VERSION ""

NS_ :

BS_:

BU_: ATCM_FFSM GENERIC_GWMWakeup IPMB Generic_BCM GWM _delete ABS_ESC HUD IPMA CCM PSCM SCCM TBM OCS TCCM TSTR RCM
VAL_TABLE_ Faulty_F 15 "Faulty" ;
VAL_TABLE_ TrlrTrgtAcquire_D_Rq 7 "NotUsed_2" 6 "NotUsed_1" 5 "ActivateRVCforTBA" 4 "CancelAcquisition" 3 "RetryAcquisition" 2 "AcquisitionSuccessful" 1 "StartAcquisition" 0 "Inactive" ;
VAL_TABLE_ TrlrTrgtAcquire_D_Stat 7 "Faulty" 6 "NotUsed_2" 5 "NotUsed_1" 4 "RVCforTBA_Activated" 3 "Processing" 2 "TargetNotAcquired" 1 "TargetAcquired" 0 "Null" ;
VAL_TABLE_ TrlrAidSetup_D_Rq 3 "NotUsed" 2 "EndSetup" 1 "BeginSetup" 0 "Inactive" ;
VAL_TABLE_ TrlBrkInitOut 3 "NotUsed" 2 "Heavy" 1 "Medium" 0 "Light" ;
VAL_TABLE_ BeltWarnThres_D_Stat 7 "Faulty" 6 "No_Data_Exists" 5 "NotUsed3" 4 "NotUsed2" 3 "NotUsed1" 2 "Over_Threshold" 1 "Under_Threshold" 0 "NotSupported" ;
VAL_TABLE_ IsaVLimUnit_D_Rq 3 "NoDataExists" 2 "Mph" 1 "Kph" 0 "Null" ;
VAL_TABLE_ IsaVLim_D_Rq 183 "NotUsed_3_to_72_toHexFC" 2 "LimitSpeed2_to_178_toHexB2" 255 "Faulty" 254 "NoDataExists" 253 "NotUsed_73" 182 "NotUsed_2" 181 "NotUsed_1" 180 "LimitSpeed_180_kph_mph" 179 "LimitSpeed_179_kph_mph" 1 "LimitSpeed_1_kph_mph" 0 "LimitSpeed_0_kph_mph" ;
VAL_TABLE_ NotSupported_Supported 1 "Supported" 0 "NotSupported" ;
VAL_TABLE_ OffOn_NotUsed_NoData 3 "No_Data_Present" 2 "NotUsed" 1 "On" 0 "Off" ;
VAL_TABLE_ BrkDrvMde_D_Rq 7 "Faulty" 6 "NotUsed3" 5 "NotUsed2" 4 "NotUsed1" 3 "Track" 2 "Snow_Wet" 1 "Sport" 0 "Normal" ;
VAL_TABLE_ Off_Indicate1_2_Faulty 3 "Faulty" 2 "Indication_2" 1 "Indication_1" 0 "Off" ;
VAL_TABLE_ AutoHoldMsgTxt_D_Rq 15 "Message15" 14 "Message14" 13 "Message13" 12 "Message12" 11 "Message11" 10 "Message10" 9 "Message9" 8 "Message8" 7 "Message7" 6 "Message6" 5 "Message5" 4 "Message4" 3 "Message3" 2 "Message2" 1 "Message1" 0 "NoMessage" ;
VAL_TABLE_ NoYesNoDataFaulty 3 "Faulty" 2 "NoDataExists" 1 "Yes" 0 "No" ;
VAL_TABLE_ TsrVlPrmntMsgTxt_D_Rq 3 "NotUsed" 2 "ShowPermanentlyWithSupp" 1 "ShowPermanentlyWithoutSupp" 0 "DoNotShowSignPermanent" ;
VAL_TABLE_ TsrVl1RstrcMsgTxt2_D_Rq 7 "NotUsed" 6 "Time" 5 "Trailer" 4 "Snow" 3 "RainWet" 2 "NoRecognizableRestrictn" 1 "NoSpeedLimitRestrictn" 0 "Null" ;
VAL_TABLE_ PtDrvMde_D_Rq 15 "Faulty" 14 "NotUsed11" 13 "NotUsed10" 12 "NotUsed9" 11 "NotUsed8" 10 "NotUsed7" 9 "NotUsed6" 8 "NotUsed5" 7 "NotUsed4" 6 "NotUsed3" 5 "NotUsed2" 4 "NotUsed1" 3 "TowHaulGradeAssist" 2 "SnowWet" 1 "Sport" 0 "Normal" ;
VAL_TABLE_ SteEffort_D_Stat 7 "NotUsed5" 6 "NotUsed4" 5 "NotUsed3" 4 "NotUsed2" 3 "NotUsed1" 2 "Comfort" 1 "Sport" 0 "Normal" ;
VAL_TABLE_ TsrOvtkMsgTxt2_D_Rq 15 "NotUsed5" 14 "NotUsed4" 13 "NotUsed3" 12 "NotUsed2" 11 "NotUsed1" 10 "LimForTrucksCancelled" 9 "LimForTrucksWoQlfdRstrc" 8 "LimForTrucksWithoutRstrc" 7 "LimAllCancelled" 6 "LimAllWithRstrcTime" 5 "LimAllWithRstrcTrailer" 4 "LimAllWithRstrcSnow" 3 "LimAllWithRstrcRain" 2 "LimAllWithoutQlfdRstrc" 1 "LimAllWithoutRestriction" 0 "OvertakingAllowed" ;
VAL_TABLE_ TrlrAnOffstDir 3 "NotUSed" 2 "Right" 1 "Left_or_Center" 0 "Null" ;
VAL_TABLE_ TrlrBrkMde_D_Rq 1 "ElectricOverHydraulic" 0 "Electric" ;
VAL_TABLE_ TrlrAidMsgTxt_D_Rq 31 "Message31" 30 "Message30" 29 "Message29" 28 "Message28" 27 "Message27" 26 "Message26" 25 "Message25" 24 "Message24" 23 "Message23" 22 "Message22" 21 "Message21" 20 "Message20" 19 "Message19" 18 "Message18" 17 "Message17" 16 "Message16" 15 "Message15" 14 "Message14" 13 "Message13" 12 "Message12" 11 "Message11" 10 "Message10" 9 "Message9" 8 "Message8" 7 "Message7" 6 "Message6" 5 "Message5" 4 "Message4" 3 "Message3" 2 "Message2" 1 "Message1" 0 "NoMessage" ;
VAL_TABLE_ Invalid_7F 127 "Invalid" ;
VAL_TABLE_ Faulty_1FFF 8191 "Faulty" ;
VAL_TABLE_ VehStab_D_Stat 15 "Faulty" 14 "NotUsed7" 13 "NotUsed6" 12 "NotUsed5" 11 "NotUsed4" 10 "NotUsed3" 9 "NotUsed2" 8 "NotUsed1" 7 "High_SSRA_no_OS" 6 "Straight" 5 "Post_Oversteer" 4 "Post_Transition" 3 "Countersteer" 2 "Understeer" 1 "Oversteer" 0 "Linear" ;
VAL_TABLE_ TrlrAidEnbl_D_Stat 7 "Faulty" 6 "NoDataExists" 5 "NotUsed2" 4 "NotUsed1" 3 "TbaNotAvailable" 2 "TbaInactive" 1 "TbaActive" 0 "Null" ;
VAL_TABLE_ TrlrAidEnbl_D_Rq 3 "Faulty" 2 "DeactivateTba" 1 "ActivateTba" 0 "Inactive" ;
VAL_TABLE_ Null_Pers1_4_Vehicle 7 "Unused_2" 6 "Unused_1" 5 "Vehicle" 4 "PERS_4" 3 "PERS_3" 2 "PERS_2" 1 "PERS_1" 0 "Null" ;
VAL_TABLE_ PrkLckCtlUnlck_D_Stat 3 "Trans_And_Steer_Unlckd" 2 "Steering_Unlckd" 1 "Transmission_Unlckd" 0 "Null" ;
VAL_TABLE_ VehKeyActv_D_Stat 15 "NotUsed7" 14 "NotUsed6" 13 "NotUsed5" 12 "NotUsed4" 11 "NotUsed3" 10 "NotUsed2" 9 "NotUsed1" 8 "Key8Active" 7 "Key7Active" 6 "Key6Active" 5 "Key5Active" 4 "Key4Active" 3 "Key3Active" 2 "Key2Active" 1 "Key1Active" 0 "NoKeyActive" ;
VAL_TABLE_ PrkBrkDynmc_D_Allw 3 "NotUsed" 2 "EPB_ECD_NotPossible" 1 "EPB_ECD_Possible" 0 "Used_at_Start_Up" ;
VAL_TABLE_ TrnGearMsgTxt_D_Rq 31 "Message_31" 30 "Message_30" 29 "Message_29" 28 "Message_28" 27 "Message_27" 26 "Message_26" 25 "Message_25" 24 "Message_24" 23 "Message_23" 22 "Message_22" 21 "Message_21" 20 "Message_20" 19 "Message_19" 18 "Message_18" 17 "Message_17" 16 "Message_16" 15 "Message_15" 14 "Message_14" 13 "Message_13" 12 "Message_12" 11 "Message_11" 10 "Message_10" 9 "Message_9" 8 "Message_8" 7 "Message_7" 6 "Message_6" 5 "Message_5" 4 "Message_4" 3 "Message_3" 2 "Message_2" 1 "Message_1" 0 "NoMessage" ;
VAL_TABLE_ Off_On_Unknown_Invalid 3 "Invalid" 2 "Unknown" 1 "On" 0 "Off" ;
VAL_TABLE_ TowBarMsgTxt_D_Rq 7 "NotUsed3" 6 "NotUsed2" 5 "NotUsed1" 4 "TowBar_Ext_No_Trlr" 3 "Error_Dealer_Fix" 2 "Start_Engine_Swivel" 1 "Check_Tow_Bar" 0 "Null" ;
VAL_TABLE_ PrkBrk_D_Stat 7 "Gen_Faults_or_Maint_Mode" 6 "ECD_by_Brake_ECU_Active" 5 "EPB_Limphome_Active" 4 "Rear_Caliper_Open" 3 "RWU_by_EPB_Active" 2 "Rear_Caliper_Transition" 1 "Rear_Caliper_Closed" 0 "Not_Supported" ;
VAL_TABLE_ AutoLghtMde_D_Stat 3 "Not_Used" 2 "GFHB" 1 "AHBC" 0 "Manual" ;
VAL_TABLE_ GfhbDistr_D_Stat 7 "High_Beam_Classis" 6 "High_Beam_GFHB" 5 "GFHB_with_Vert_Adjustment" 4 "GFHB_with_Spot" 3 "Motorway" 2 "Low_Beam_GFHB" 1 "Low_Beam_Classic" 0 "Symmetric" ;
VAL_TABLE_ GfhbV_D 3 "Immediately" 2 "Fast" 1 "Medium" 0 "Slow" ;
VAL_TABLE_ GfhbLamp_D_Stat 3 "Both_On" 2 "Left_On_Right_Off" 1 "Right_On_Left_Off" 0 "Both_Off" ;
VAL_TABLE_ GfhbDistrChng_D_Stat 3 "Both_in_Transition" 2 "Left_in_Transition" 1 "Right_in_Transition" 0 "Both_Static" ;
VAL_TABLE_ Faulty_1FF 511 "Faulty" ;
VAL_TABLE_ NoData_Faulty_1FFF_1FFE 8191 "Faulty" 8190 "NoDataExists" ;
VAL_TABLE_ AwdSys_D_Stat 3 "Faulty" 2 "NotUsed" 1 "_4x4_L_H_Active" 0 "_4x4_L_H_Inactive" ;
VAL_TABLE_ TrnSrvcRqd_B_Rq 1 "On" 0 "Off" ;
VAL_TABLE_ immoSecureIdleMode 3 "NotUsed2" 2 "NotUsed1" 1 "Active" 0 "Inactive" ;
VAL_TABLE_ SteMdule_D_Stat 7 "NotUsed" 6 "EPAS_Failure3" 5 "EPAS_Failure2" 4 "System_Failure" 3 "EPAS_Shutdown" 2 "Normal_Op_Full_Assist" 1 "Normal_Op_Limited_Assist" 0 "EPAS_Initialization" ;
VAL_TABLE_ TrlrAid_D_Stat 15 "Faulty" 14 "NoDataExists" 13 "NotUsed5" 12 "NotUsed4" 11 "NotUsed3" 10 "NotUsed2" 9 "NotUsed1" 8 "Sensor_Fault" 7 "Sensor_Blocked" 6 "Target_Cannot_Be_Located" 5 "Acquired_Confidence5" 4 "Acquired_Confidence4" 3 "Acquired_Confidence3" 2 "Acquired_Confidence2" 1 "Acquired_Confidence1" 0 "Target_Not_Acquired" ;
VAL_TABLE_ Faulty_FFF 4095 "Faulty" ;
VAL_TABLE_ Faulty_3FF 1023 "Faulty" ;
VAL_TABLE_ NoData_Faulty_FE_FF 255 "Faulty" 254 "NoDataExists" ;
VAL_TABLE_ TrnLvrV_D_Rq 3 "Full_Speed" 2 "Aggressive" 1 "Normal" 0 "Quiet" ;
VAL_TABLE_ DynoMde_B_Cmd 1 "Two_Wheel_Dyno" 0 "Normal_Operation" ;
VAL_TABLE_ NoData_Faulty_FFFE_FFFF 65535 "Faulty" 65534 "NoDataExists" ;
VAL_TABLE_ NoData_Faulty_7FFE_7FFF 32767 "Faulty" 32766 "NoDataExists" ;
VAL_TABLE_ NoData_Faulty_3FE_3FF 1023 "Faulty" 1022 "NoDataExists" ;
VAL_TABLE_ OffOn_NotUsed 3 "NotUsed2" 2 "NotUsed1" 1 "On" 0 "Off" ;
VAL_TABLE_ DrQltyDrv_D_StatGsm 7 "Faulty" 6 "NoDataExists" 5 "NotUsed2" 4 "NotUsed1" 3 "ClosedDegraded" 2 "OpenDegraded" 1 "ClosedOkay" 0 "OpenOkay" ;
VAL_TABLE_ NoData_Fault_1FF_1FE 511 "Fault" 510 "NoDataExists" ;
VAL_TABLE_ NoData_Fault_FFE_FFF 4095 "Fault" 4094 "NoDataExists" ;
VAL_TABLE_ Quality_Faulty 3 "OK" 2 "Degraded" 1 "No_Data_Exists" 0 "Faulty" ;
VAL_TABLE_ TrnDtpCmd_D_Actl 7 "NotUsed4" 6 "NotUsed3" 5 "NotUsed2" 4 "Relatch" 3 "Deploy" 2 "Self_Test" 1 "No_Command" 0 "NotUsed1" ;
VAL_TABLE_ TrnGsmNtmState_D_Actl 3 "Faulty" 2 "Neutral_Tow_Mode" 1 "Car_Wash_Mode" 0 "None" ;
VAL_TABLE_ TrnTrcmPwmSig_D_Actl 15 "Faulty" 14 "NoDataExists" 13 "NotUsed5" 12 "NotUsed4" 11 "NotUsed3" 10 "NotUsed2" 9 "NotUsed1" 8 "Default_To_Park" 7 "Neutral_Tow" 6 "Car_Wash_Mode" 5 "Manual" 4 "Drive" 3 "Neutral" 2 "Reverse" 1 "Park" 0 "No_Gear" ;
VAL_TABLE_ RgenBrkDynoMde_B_Actl 1 "TwoWheelDyno" 0 "NormalOperation" ;
VAL_TABLE_ Fault_3FFF 16383 "Fault" ;
VAL_TABLE_ CtaInnr_D_Stat 3 "Reporting" 2 "Not_Reporting" 1 "System_Standby" 0 "Initialization" ;
VAL_TABLE_ PrkBrkActv_D_RqTrnGear 3 "NotUsed2" 2 "RequestParkBrakeEngage" 1 "NoRequest" 0 "NotUsed1" ;
VAL_TABLE_ NoRequest_Request 1 "Request" 0 "NoRequest" ;
VAL_TABLE_ Fault_FFF_NoData 4094 "NoDataExists" 4095 "Fault" ;
VAL_TABLE_ Fault_3FF_NoData 1022 "NoDataExists" 1023 "Fault" ;
VAL_TABLE_ ICI_Coding_BtnID_A 15 "Idle" 5 "Stuck" 4 "LongEvent" 3 "ShortElapsed" 2 "ShortEvent" 1 "Active" 0 "Inactive" ;
VAL_TABLE_ Foh_D_Stat 7 "Unused3" 6 "Unused2" 5 "Unused1" 4 "Stopping" 3 "Running" 2 "Starting" 1 "Prestart" 0 "Off" ;
VAL_TABLE_ Fault_1FF 511 "Fault" ;
VAL_TABLE_ SteWhlHeat 15 "NotUsed6" 14 "NotUsed5" 13 "NotUsed4" 12 "NotUsed3" 11 "NotUsed2" 10 "NotUsed1" 9 "Reserved_3" 8 "Reserved_2" 7 "Reserved_1" 6 "Level_3_Heating" 5 "Level_3_Heating_LS" 4 "Level_2_Heating" 3 "Level_2_Heating_LS" 2 "Level_1_Heating" 1 "Level_1_Heating_LS" 0 "Off" ;
VAL_TABLE_ NullKphMph 3 "NoDataExists" 2 "Mph" 1 "Kph" 0 "Null" ;
VAL_TABLE_ TsrVLim1MsgTxt_D_Rq 255 "NoLimit" 254 "NotUsed2" 253 "NotUsed1" 252 "NotToBeDisplayed" 251 "LimitCancelled" 31 "1F_FA_Message31_250" 30 "Message30" 29 "Message29" 28 "Message28" 27 "Message27" 26 "Message26" 25 "Message25" 24 "Message24" 23 "Message23" 22 "Message22" 21 "Message21" 20 "Message20" 19 "Message19" 18 "Message18" 17 "Message17" 16 "Message16" 15 "Message15" 14 "Message14" 13 "Message13" 12 "Message12" 11 "Message11" 10 "Message10" 9 "Message9" 8 "Message8" 7 "Message7" 6 "Message6" 5 "Message5" 4 "Message4" 3 "Message3" 2 "Message2" 1 "Message1" 0 "Null" ;
VAL_TABLE_ TsrVl1RstrcMsgTxt_D_Rq 3 "NotUsed" 2 "NoRecognizableRestriction" 1 "NoSpeedLimitRestriction" 0 "Null" ;
VAL_TABLE_ TsrMsgTxt_D_Rq 15 "NotUsed5" 14 "NotUsed5" 13 "NotUsed4" 12 "NotUsed3" 11 "NotUsed2" 10 "NotUsed1" 9 "RecgnzdSignNotUsblForDsply" 8 "LimitedSystemPerformance" 7 "OffRoad" 6 "RegionNotSupported" 5 "CountryNotSupported" 4 "WrngNavDatIncompDatCarrier" 3 "NoNavDataAvailable" 2 "NoNavAvailableSwitchedOff" 1 "NoInformationAllOK" 0 "Null" ;
VAL_TABLE_ TsrOvtkTypeMsgTxt_D_Rq 3 "NotUsed" 2 "Explicit" 1 "Implicit" 0 "Null" ;
VAL_TABLE_ TsrOvtkStatMsgTxt_D_Rq 3 "LimitOutdated" 2 "LimitReiable" 1 "LimitChanged" 0 "Null" ;
VAL_TABLE_ TsrOvtkMsgTxt_D_Rq 7 "LimForTrucksCancelled" 6 "LimForTrucksWoQlfdRstrc" 5 "LimForTrucksWithoutRstrc" 4 "LimAllCancelled" 3 "LimAllWithoutQlfdRstrc" 2 "LimAllWithoutRestriction" 1 "OvertakingAllowed" 0 "Null" ;
VAL_TABLE_ Null_False_True 3 "NotUsed" 2 "True" 1 "False" 0 "Null" ;
VAL_TABLE_ TsrStatMsgTxt_D_Rq 7 "NotUsed" 6 "NoDataExists" 5 "TSR_Error" 4 "Available_NavigationOnly" 3 "Available_CameraOnly" 2 "Available_FusionMode" 1 "TSR_Off" 0 "Null" ;
VAL_TABLE_ NoMessage_DisplayMessage 1 "DisplayMessage" 0 "NoMessage" ;
VAL_TABLE_ FdsmTrgRight 1 "Object_in_Right_Lobe" 0 "No_Object" ;
VAL_TABLE_ FdsmTrgCntr 1 "Object_in_Center_Lobe" 0 "No_Object" ;
VAL_TABLE_ FdsmTrgLeft 1 "Object_in_Left_Lobe" 0 "No_Object" ;
VAL_TABLE_ EngineBrakeOff_Active 1 "Engine_Braking_Activated" 0 "Engine_Braking_Off" ;
VAL_TABLE_ NoEngineBrake_Brake 1 "Engine_Braking" 0 "No_Engine_Braking" ;
VAL_TABLE_ EngSrvcRqd_B_Rq 1 "Engine_Service_Required" 0 "No_engine_service_required" ;
VAL_TABLE_ Allowed_Denied 1 "Denied" 0 "Allowed" ;
VAL_TABLE_ PrkAidMsgTxt_D_Rq 15 "NotUsed7" 14 "NotUsed6" 13 "NotUsed5" 12 "R_Sns_Inactive_Trlr_atch" 11 "Not_Avail_Trlr_attchd" 10 "Fail_Mode_no_Chime" 9 "Fail_Mode_with_Chime" 8 "NotUsed4" 7 "NotUsed3" 6 "Park_Sys_Alternate_Mode" 5 "R_Snsrs_On_F_Snsrs_On" 4 "NotUsed2" 3 "NotUsed1" 2 "R_Snsrs_Off_F_Snsrs_On" 1 "R_Snsrs_On_F_Snsrs_Off" 0 "All_Park_Sensors_Off" ;
VAL_TABLE_ PrkAidSns_D_Stat 15 "Zone_15" 14 "Zone_14" 13 "Zone_13" 12 "Zone_12" 11 "Zone_11" 10 "Zone_10" 9 "Zone_9" 8 "Zone_8" 7 "Zone_7" 6 "Zone_6" 5 "Zone_5" 4 "Zone_4" 3 "Zone_3" 2 "Zone_2" 1 "Zone_1" 0 "Off" ;
VAL_TABLE_ PrkAid_D_Falt 7 "NotUsed2" 6 "NotUsed1" 5 "Failure_Front_PSM_Sensors" 4 "No_Data_Exists" 3 "Failure_Rear_Sensors" 2 "Speaker_Fault" 1 "ECU_Fault" 0 "No_Fault" ;
VAL_TABLE_ OffOnNoDataFault 3 "Fault" 2 "No_Data_Exists" 1 "On" 0 "Off" ;
VAL_TABLE_ ApaActvSd_D_Actl 3 "Dirver_Side" 2 "Passenger_Side" 1 "No_Side" 0 "Null" ;
VAL_TABLE_ ApaMde_D_Avail 15 "NotUsed7" 14 "NotUsed6" 13 "NotUsed5" 12 "NotUsed4" 11 "NotUsed3" 10 "NotUsed2" 9 "NotUsed1" 8 "PPA_POA" 7 "SAPP_POA" 6 "POA" 5 "PPA" 4 "SAPP" 3 "SAPP_PPA_POA" 2 "SAPP_PPA" 1 "None" 0 "Null" ;
VAL_TABLE_ ApaMde_D_Stat 7 "NotUsed3" 6 "NotUsed2" 5 "NotUsed1" 4 "POA" 3 "PPA" 2 "SAPP" 1 "Off" 0 "Null" ;
VAL_TABLE_ _7F_Null 127 "Null" ;
VAL_TABLE_ MemFeedback 8 "Recall_4" 7 "Recall_3" 6 "Recall_2" 5 "Recall_1" 4 "Store_4" 3 "Store_3" 2 "Store_2" 1 "Store_1" 0 "Inactive" ;
VAL_TABLE_ Null_Off_LowHigh 3 "High" 2 "Low" 1 "Off" 0 "Null" ;
VAL_TABLE_ NotUpdate_Update 1 "Updating" 0 "NotUpdating" ;
VAL_TABLE_ SeatFnDrv_D_Stat 7 "CushionMassage" 6 "LumbarMassage" 5 "UpperBolster" 4 "LowerBolster" 3 "UpperLumbar" 2 "MiddleLumbar" 1 "LowerLumbar" 0 "Null" ;
VAL_TABLE_ GearRvrse_D_Actl 7 "Fault" 6 "NotUsed_3" 5 "NotUsed_2" 4 "NotUsed_1" 3 "Active_confirmed" 2 "Active_not_confirmed" 1 "Inactive_confirmed" 0 "Inactive_not_confirmed" ;
VAL_TABLE_ SideDetect_SnStat_Invalid 3 "Invalid" 2 "System_Failure" 1 "Blocked" 0 "Clear" ;
VAL_TABLE_ SideDetect_OpStat 4 "Invalid" 3 "Disabled" 2 "On" 1 "Trailer_Tow_Off" 0 "Off" ;
VAL_TABLE_ SideDetect_Present 4 "Sensor_Blocked" 3 "Sensor_Fault" 2 "Flash_On" 1 "Alert_On" 0 "AlertOff_FlashOff_SensrClr" ;
VAL_TABLE_ Off_On_Flash_BulbProveout 3 "Bulb_Proveout" 2 "Flash" 1 "On" 0 "Off" ;
VAL_TABLE_ SideDetect_report 3 "Reporting" 2 "Not_Reporting" 1 "System_Standby" 0 "Initialization" ;
VAL_TABLE_ DcacElPw_D_Rq 3 "NotUsed" 2 "AC_HighPower_Requested" 1 "AC_LowPower_Requested" 0 "AC_Power_NotRequested" ;
VAL_TABLE_ Null_Up_Down 3 "Unused" 2 "Down" 1 "Up" 0 "Null" ;
VAL_TABLE_ Null_Fwd_Rwd 3 "Unused" 2 "Rearward" 1 "Forward" 0 "Null" ;
VAL_TABLE_ BattTracWarnLamp_B_Rq 1 "On" 0 "Off" ;
VAL_TABLE_ BattTracSrvcRqd_B_Rq 1 "On" 0 "Off" ;
VAL_TABLE_ HtrnWarnLamp_B_Dsply 1 "On" 0 "Off" ;
VAL_TABLE_ HtrnSrvcRqd_B_Dsply 1 "On" 0 "Off" ;
VAL_TABLE_ NoData_Faulty_7E_7F 127 "Faulty" 126 "NoDataExists" ;
VAL_TABLE_ HMI_HMIMode_St 5 "Load_Shed_Active" 0 "Invalid" 1 "OffMode" 2 "On" 3 "Phone" 4 "Climate" ;
VAL_TABLE_ FuelPumpPwr_D_Stat 7 "NotUsed3" 6 "NotUsed2" 5 "NotUsed1" 4 "Power_Off_Default" 3 "Power_Off_Command" 2 "Power_Off_Service" 1 "Power_Off_Impact" 0 "Power_On" ;
VAL_TABLE_ PtcHtr_D_Cmd 3 "TurnOn" 2 "AutoMode" 1 "TurnOff" 0 "NoDecision_Initializing" ;
VAL_TABLE_ NoData_Fault_FFFE_FFFF 65535 "Fault" 65534 "NoDataExists" ;
VAL_TABLE_ Fault_1FFF 8191 "Fault" ;
VAL_TABLE_ TrlrBattChrg_D_Stat 3 "Reverse" 2 "Normal" 1 "Low" 0 "Null" ;
VAL_TABLE_ TrlrLampCtl_D_Stat 3 "NotUsed" 2 "TrlrLampCnnctDrvFailure" 1 "TrlrLampNotCnnctDrvFailure" 0 "Null" ;
VAL_TABLE_ ElPw_D_StatStrtStop 15 "NotUsed6" 14 "NotUsed5" 13 "NotUsed4" 12 "NotUsed3" 11 "NotUsed2" 10 "NotUsed1" 9 "Supported_Level_4" 8 "Supported_Level_3" 7 "Supported_Level_2" 6 "Supported_Level_1" 5 "Limited_Support" 4 "Fault_Limited" 3 "LV_Event_in_Progress" 2 "Not_Supported_Imminent" 1 "Supported_All" 0 "Not_Supported" ;
VAL_TABLE_ ImpactEvntFdbck_D_Stat 3 "NotUsed" 2 "EventComplete" 1 "EventInProgress" 0 "Normal" ;
VAL_TABLE_ NoData_Fault_7FFE_7FFF 32767 "Fault" 32766 "NoDataExists" ;
VAL_TABLE_ NoData_Fault_3E_3F 63 "Fault" 62 "NoDataExists" ;
VAL_TABLE_ DrvSte_D_Stat 15 "NotUsed10" 14 "NotUsed9" 13 "NotUsed8" 12 "NotUsed7" 11 "NotUsed6" 10 "NotUsed5" 9 "NotUsed4" 8 "NotUsed3" 7 "NotUsed2" 6 "NotUsed1" 5 "Request_Active" 4 "Ignition_Off" 3 "DSR_in_Normal_Idle_Mode" 2 "EPAS_Comm_Disturbed" 1 "DSR_Request_Not_Applicable" 0 "DSR_Deactivated" ;
VAL_TABLE_ HeadLghtHiFdbck_D_Stat 3 "NotUsed" 2 "Cancel" 1 "Hold" 0 "Allow_Change" ;
VAL_TABLE_ Backlit_LED_Status 15 "Unused3" 14 "Unused2" 13 "Unused1" 12 "Night_12" 11 "Night_11" 10 "Night_10" 9 "Night_9" 8 "Night_8" 7 "Night_7" 6 "Night_6" 5 "Night_5" 4 "Night_4" 3 "Night_3" 2 "Night_2" 1 "Night_1" 0 "Off" ;
VAL_TABLE_ Veh_Lock_Status 3 "UNLOCK_DRV" 2 "UNLOCK_ALL" 1 "LOCK_ALL" 0 "LOCK_DBL" ;
VAL_TABLE_ PrkLckCtlMsgTxt_D_Rq 3 "BTSI_DI_3" 2 "BTSI_DI_2" 1 "BTSI_DI_1" 0 "Null_BTSI_DI" ;
VAL_TABLE_ NoShift_Shift 1 "Shift" 0 "NoShift" ;
VAL_TABLE_ CcdMsgTxt_D_RqDsply 15 "Unused8" 14 "Unused7" 13 "Unused6" 12 "Unused5" 11 "Unused4" 10 "Unused3" 9 "Unused2" 8 "Unused1" 7 "Mode_Change_Unavailable" 6 "CCD_Temporarily_Off" 5 "CCD_Service_Required" 4 "Fault" 3 "Sport" 2 "Normal" 1 "Comfort" 0 "No_Mode_Selected" ;
VAL_TABLE_ CrashEvnt_D_Stat 3 "Invalid" 2 "Fuel_Cutoff_Event" 1 "Deploy_Event" 0 "No_Event" ;
VAL_TABLE_ ReducedGuard_D_Stat 3 "NotUsed" 2 "Alarm_On" 1 "Alarm_Off_Previously_On" 0 "Alarm_Off" ;
VAL_TABLE_ ButtonNotPressed 1 "Button_Pressed" 0 "Button_Not_Pressed" ;
VAL_TABLE_ PudLamp_D_Rq 3 "RAMP_DOWN" 2 "RAMP_UP" 1 "ON" 0 "OFF" ;
VAL_TABLE_ WndwGlbl_D_Cmd 7 "NotUsed3" 6 "NotUsed2" 5 "NotUsed1" 4 "GLEARN" 3 "GCLOSE" 2 "GOPEN" 1 "GSTOP" 0 "Null" ;
VAL_TABLE_ Wiper 15 "NO_DATA_EXISTS" 14 "STALLED" 13 "RESERVED" 12 "AUTO_ADJUST" 11 "COURTESYWIPE" 10 "AUTO_HIGH" 9 "AUTO_LOW" 8 "WASH" 7 "MIST_FLICK" 6 "MAN_HIGH" 5 "MAN_LOW" 4 "MAN_INT_ON" 3 "MAN_INT_OFF" 2 "OFF_MOVING" 1 "AUTO_OFF" 0 "OFF" ;
VAL_TABLE_ Turn_switch 3 "Unused_Treat_As_Off" 2 "Right" 1 "Left" 0 "Off" ;
VAL_TABLE_ PrkLght_D_Stat 3 "Park_Both" 2 "Park_Right" 1 "Park_Left" 0 "Off" ;
VAL_TABLE_ LghtAmb_D_Sns 7 "No_Data_Exists" 6 "Unused2" 5 "Unused1" 4 "Tunnel_Off" 3 "Tunnel_On" 2 "Twilight" 1 "Light" 0 "Dark" ;
VAL_TABLE_ HeadLghtSwtch_D_Stat 3 "Autolamp" 2 "Headlamp" 1 "Parklamp" 0 "Off" ;
VAL_TABLE_ EmgcyBrkLamp_D_Rq 3 "NotUsed" 2 "Active_at_standstill" 1 "Active_at_speed" 0 "Inactive" ;
VAL_TABLE_ OpenPressedFault 3 "Fault" 2 "Unused" 1 "Pressed" 0 "Open" ;
VAL_TABLE_ LaHandsOff_D_Dsply 3 "Suppressed" 2 "Level2" 1 "Level1" 0 "HandsOn" ;
VAL_TABLE_ Avail_Unavail 1 "Unavailable" 0 "Available" ;
VAL_TABLE_ LaActvStats_D_Dsply 31 "Unused7" 30 "LA_Off" 29 "Unused5" 28 "Unused4" 27 "Unused3" 26 "Unused2" 25 "Unused1" 24 "InerveneLeft_InterveneRght" 23 "WarnLeft_InterveneRight" 22 "SuppressLeft_InterveneRght" 21 "AvailLeft_InterveneRhtt" 20 "NoLeft_InterveneRight" 19 "InterveneLeft_WarnRight" 18 "WarnLeft_WarnRight" 17 "SuppressLeft_WarnRight" 16 "AvailableLeft_WarnRight" 15 "NoLeft_WarnRight" 14 "InterveneLeft_SuppressRght" 13 "WarnLeft_SuppressRight" 12 "SuppressLeft_SuppressRight" 11 "AvailLeft_SuppressRight" 10 "NoLeft_SuppressRight" 9 "InterveneLeft_AvailRight" 8 "WarnLeft_AvailRight" 7 "SuppressLeft_AvailRight" 6 "AvailableLeft_AvailRight" 5 "NoLeft_AvailableRight" 4 "InterveneLeft_NoRight" 3 "WarnLeft_NoRight" 2 "SuppressLeft_NoRight" 1 "AvailableLeft_NoRight" 0 "NoLeft_NoRight" ;
VAL_TABLE_ AhbcHiBeam_D_Rq 3 "Deactivated_Unavailabl" 2 "Unused" 1 "Main_HighBeamRecommend" 0 "Dipped_LowBeamRecommend" ;
VAL_TABLE_ LifeCycMde_D_Actl 3 "Transport" 2 "NotUsed" 1 "Factory" 0 "Normal" ;
VAL_TABLE_ TrnMsgTxt_D_Rq 15 "Message_15" 14 "Message_14" 13 "Message_13" 12 "Message_12" 11 "Message_11" 10 "Message_10" 9 "Message_9" 8 "Message_8" 7 "Message_7" 6 "Message_6" 5 "Message_5" 4 "Message_4" 3 "Message_3" 2 "Message_2" 1 "Message_1" 0 "NoMessage" ;
VAL_TABLE_ DieslPrtcRgen_D_Rq 7 "Unused_2" 6 "Unused_1" 5 "Full_Regen_2" 4 "Full_Regen_1" 3 "HeatUp_3" 2 "HeatUp_2" 1 "HeatUp_1" 0 "Normal_Mode_NoRegen" ;
VAL_TABLE_ TrnCapHlth_Actl 3 "Capacitor_OK" 2 "Degraded_Capacitor" 1 "Capacitor_State_Unknown" 0 "Capacitor_Fault" ;
VAL_TABLE_ TrnSecPrkStat_D_Actl 7 "Faulty" 6 "Fault_Released" 5 "Fault_Latched" 4 "Recouple_in_Progress" 3 "Mechanism_Released" 2 "RTP_in_Progress" 1 "Pending" 0 "Latched" ;
VAL_TABLE_ TrnGear_D_Actl 7 "Fault" 6 "NotUsed" 5 "Manual" 4 "Drive" 3 "Neutral" 2 "Reverse" 1 "Park" 0 "Transition_State" ;
VAL_TABLE_ TrnNtrlTowCmd_D_Actl 3 "NotUsed" 2 "Neutral_Tow_Entry" 1 "Car_Wash_Mode" 0 "Normal_Mode" ;
VAL_TABLE_ TrnValidGear_D_Cnfm 3 "Accept" 2 "Reject" 1 "Internal_Request" 0 "No_Command" ;
VAL_TABLE_ TrnGear_D_RqPt 7 "Fault" 6 "NotUsed" 5 "Manual" 4 "Drive" 3 "Neutral" 2 "Reverse" 1 "Park" 0 "No_Gear" ;
VAL_TABLE_ TrnValidGearRq_D_Stat 3 "Valid_Request" 2 "Valid_Degraded_Request" 1 "Invalid_Request" 0 "No_Request" ;
VAL_TABLE_ NoData_Fault_3FE_3FF 1023 "Fault" 1022 "NoDataExists" ;
VAL_TABLE_ HtrnHvilOpen_B_Actl 1 "HVIL_is_Open" 0 "Normal_Operation" ;
VAL_TABLE_ EngFuelCutFull_B_Rq 1 "FuelCutRequest" 0 "NormalOperation" ;
VAL_TABLE_ Fault_7FF 2047 "Fault" ;
VAL_TABLE_ EngStopFst_B_Rq 1 "FastEngineShutdown" 0 "NormalOperation" ;
VAL_TABLE_ EngStrtCold_B_Rq 1 "ExtremeColdStart" 0 "NormalStart" ;
VAL_TABLE_ Fault_FFF 4095 "Fault" ;
VAL_TABLE_ PrkBrkMsgTxt_D_Rq 15 "Message15" 14 "Message14" 13 "Message13" 12 "Message12" 11 "Message11" 10 "Message10" 9 "Message9" 8 "Message8" 7 "Message7" 6 "Message6" 5 "Message5" 4 "Message4" 3 "Message3" 2 "Message2" 1 "Message1" 0 "No_Message" ;
VAL_TABLE_ VehStrtStop_D_Rq 3 "NotUsed" 2 "Vehicle_Start_Request" 1 "Vehicle_Stop_Request" 0 "NoRequest" ;
VAL_TABLE_ PrkBrkStatus 7 "GeneralFault_MaintenceMode" 6 "ECD_by_Brake_ECU_Active" 5 "EPB_Limphome_Active" 4 "Rear_Caliper_Open" 3 "RWU_By_EPB_Active" 2 "Rear_Caliper_Transition" 1 "Rear_Caliper_Closed" 0 "Not_Supported" ;
VAL_TABLE_ DontCare_StartInhibit 1 "Start_Inhibit" 0 "Dont_Care" ;
VAL_TABLE_ BattULoChrg_D_Rq 3 "Not_Used" 2 "Charging_Requested" 1 "Chrg_Requested_HighCurrent" 0 "No_Request" ;
VAL_TABLE_ PwSysULoFalt_D_Stat 15 "Not_Used_6" 14 "LowBatterySOC" 13 "PSS_Shed2_Contin" 12 "Not_Used_4" 11 "Not_Used_3" 10 "Not_Used_2" 9 "BattMonitoringSensorFault" 8 "LowBattVoltDuringPwSrcOn" 7 "LowBatt2_PowerSaveMode" 6 "LowBatt1_Warning" 5 "Overvoltage" 4 "Fault_NoOutput" 3 "Fault_ReducedOutput" 2 "Fault_Nonspecific" 1 "Cluster_Proveout" 0 "No_Fault" ;
VAL_TABLE_ AccStopMde_D_Rq 3 "Stop_Mode_Active" 2 "EPBApplyOrBrakeReleaseWarn" 1 "Limit_Rolling_Speed" 0 "Stop_Mode_Not_Active" ;
VAL_TABLE_ EngFuelCutFull_B_Sched 1 "DFSO_Event_Scheduled" 0 "Normal" ;
VAL_TABLE_ Eng_D_Stat 3 "NotUsed" 2 "EngAutoStopped" 1 "EngOn" 0 "EngOff" ;
VAL_TABLE_ ElPw_D_Stat 7 "NotUsed_3" 6 "NotUsed_2" 5 "NotUsed_1" 4 "Fault_Limited" 3 "LV_Event_In_Progress" 2 "Not_Supported_Imminent" 1 "Supported" 0 "Not_Supported" ;
VAL_TABLE_ PwPckTq_D_Stat 3 "PwPckOn_TqAvailable" 2 "StartInPrgrss_TqNotAvail" 1 "PwPckOn_TqNotAvailable" 0 "PwPckOff_TqNotAvailable" ;
VAL_TABLE_ Fault_FF 255 "Fault" ;
VAL_TABLE_ PsngrFrntDetct_D_Actl 3 "Unknown" 2 "Empty" 0 "Faulty" 1 "Occupied" ;
VAL_TABLE_ LaActvAvail 3 "LKA_LCA_LDW_Avail" 2 "LCA_LKA_Avail_LDW_Suppress" 1 "LCA_LKA_Suppress_LDW_Avail" 0 "LCA_LKA_LDW_Suppress" ;
VAL_TABLE_ LA_NotDenied 1 "LA_Denied" 0 "LA_Not_Denied" ;
VAL_TABLE_ HandsOn_Off 1 "Hands_Off" 0 "Hands_On" ;
VAL_TABLE_ Smooth_Quick 1 "Quick" 0 "Smooth" ;
VAL_TABLE_ LkaActvStats 7 "LKALCA_Suppress_Right_Left" 6 "LCA_In_Progress" 5 "LKA_Suppress_Right" 4 "LKA_Intervention_Right" 3 "LKA_Suppress_Left" 2 "LKA_Intervention_Left" 1 "LKA_Idle_LCA_Suppress" 0 "LKA_Idle" ;
VAL_TABLE_ None_Low_Med_High 3 "High" 2 "Medium" 1 "Low" 0 "None" ;
VAL_TABLE_ LdwActvStats 7 "LDW_Suppress_Right_Left" 6 "Not_Used2" 5 "LDW_Suppress_Right" 4 "LDW_Warning_Right" 3 "LDW_Suppress_Left" 2 "LDW_Warning_Left" 1 "Not_Used1" 0 "LDW_Idle" ;
VAL_TABLE_ Fault_3FF 1023 "Fault" ;
VAL_TABLE_ VedsEvnt_6 5 "Unused_3" 4 "Unused_2" 3 "Unused_1" 2 "NotBelted" 1 "Belted" 0 "NoEvent" 7 "Fault" 6 "NotSupported" ;
VAL_TABLE_ VedsEvnt_5 7 "Fault" 6 "NotSupported" 5 "Unused_3" 4 "Unused_2" 3 "Unused_1" 2 "ChildNotDetected" 1 "ChildDetected" 0 "NoEvent" ;
VAL_TABLE_ VedsEvnt_4 7 "Fault" 6 "NotSupported" 5 "Unused_3" 4 "Unused_2" 3 "Unused_1" 2 "NotDeployed" 1 "Deployed" 0 "NoEvent" ;
VAL_TABLE_ VedsEvnt_3 0 "NoEvent" 255 "Fault" 254 "NotSupported" ;
VAL_TABLE_ VedsEvnt_2 7 "Fault" 6 "NotSupported" 5 "Unused_3" 4 "Unused_2" 3 "Unused_1" 2 "Yes" 1 "No" 0 "NoEvent" ;
VAL_TABLE_ VedsEvnt_1 7 "Fault" 6 "NotSupported" 5 "Unused" 4 "Rolllover" 3 "Rear" 2 "Side" 1 "Frontal" 0 "NoEvent" ;
VAL_TABLE_ TmsStatRqDsply 15 "Reserved4" 14 "Reserved3" 13 "Reserved2" 12 "Crawl_Mode_4LOW_Reqd" 11 "Economy_Mode_Select" 10 "ModeChangeNotAvailable" 9 "Terrain_Sys_Not_Avail" 8 "Terrain_System_Fault" 7 "Mode_Change_InProgress" 6 "Dynamics_Mode_Select" 5 "Rock_Crawl_Mode_Select" 4 "Sand_Mode_Select" 3 "Mud_Ruts_Mode_Select" 2 "Low_Mu_Mode_Select" 1 "Special_Modes_Off" 0 "No_Message" ;
VAL_TABLE_ Invalid_FFF 4095 "Invalid" ;
VAL_TABLE_ ParkAid_Chime 15 "Zone15_Chime" 14 "Zone14_Chime" 13 "Zone13_Chime" 12 "Zone12_Chime" 11 "Zone11_Chime" 10 "Zone10_Chime" 9 "Zone9_Chime" 8 "Zone8_Chime" 7 "Zone7_Chime" 6 "Zone6_Chime" 5 "Zone5_Chime" 4 "Zone4_Chime" 3 "Zone3_Chime" 2 "Zone2_Chime" 1 "Zone1_Chime" 0 "No_Chime" ;
VAL_TABLE_ Shed_Feature_Group_ID 14 "HtdMirr" 13 "HvacRearBlwr_Third" 12 "HvacRearBlwr_Second" 11 "HvacRearBlwr_First" 31 "All LSHED1 Features" 10 "Htd_Windscrn" 9 "SpltHtdBcklight_HtdMirr" 8 "HtdBcklight_HtdMirr" 7 "HtdCoolSeat_FrtDriver" 6 "HtdCoolSeat_FrtPass" 5 "HtdCoolSeat_RearPass" 4 "HtdCoolSeat_RearDriver" 3 "SmartTrlrTowBattCharge" 2 "Htd_StrWhl" 1 "Htd_Washer_Fluid" 0 "No_LSHED1_Features" 15 "Engine_Coolant_Fan" ;
VAL_TABLE_ Null_Cancel 1 "Cancel" 0 "Null" ;
VAL_TABLE_ Veh_Lock_Requestor 31 "Unused8" 30 "Unused7" 29 "Unused6" 28 "Unused5" 27 "Unused4" 26 "Unused3" 25 "Unused2" 24 "Unused1" 23 "Diagnostics" 22 "Console_Lock" 21 "Child_Lock" 20 "Double_Lock" 19 "Passive_Pasenger" 18 "Passive_Driver" 17 "Slam_Lock_Protect" 16 "SYNC" 15 "Passport" 14 "Passive_Smart_Unlock" 13 "Autorelock" 12 "RemoteStart" 0 "Null" 1 "Autolock" 11 "Smart_Unlock" 10 "Sliding_Door" 9 "Passive" 8 "Remote" 7 "Programming" 6 "Powerslide" 5 "Keypad" 4 "Key_Cylinder" 3 "Interior" 2 "Auto_Unlock" ;
VAL_TABLE_ EPAS_FAILURE 3 "SERVICE_POWER_STEERING_NOW" 2 "SERVICE_POWER_STEERING" 1 "POWER_STRG_ASSIST_FAULT" 0 "EPAS_OK_NO_MESSAGE" ;
VAL_TABLE_ Perimeter_Alarm_Mode 3 "Activated" 2 "Armed" 1 "Prearmed" 0 "Disarmed" ;
VAL_TABLE_ Invalid_FFFF 65535 "Invalid" ;
VAL_TABLE_ FdaStat_D_Dsply 7 "Undefined_3" 6 "Undefined_2" 5 "Undefined_1" 4 "Distance_Alert_Unavailable" 3 "DistanceAlertUnavail_Low" 2 "DistanceAlertUnavailActive" 1 "Distance_Alert_Available" 0 "Distance_Alert_Off" ;
VAL_TABLE_ Shed_Level_Req 7 "Unused_2" 6 "Loads_On" 5 "SHED_ENG_OFF" 4 "SOON_ENG_OFF" 3 "SHED2_CONTIN" 2 "SHED2_TRANS" 1 "SHED1" 0 "NO_SHED" ;
VAL_TABLE_ BpedMove_D_Actl 3 "Unknown" 2 "DriverApplyingBrakePedal" 1 "NoAutonomousBrkPdlMovement" 0 "AutonomousBrkPedalMove" ;
VAL_TABLE_ Off_On_Undefined_Fault 3 "Fault" 2 "Undefined" 1 "On" 0 "Off" ;
VAL_TABLE_ ChargeMode 7 "Undefined_2" 6 "Undefined_1" 5 "Battery_Identify" 4 "Battery_Refresh" 3 "SlowRegenAllowNoDischarge" 2 "Fast_Regen_Allowed" 1 "Slow_Regen_Allowed" 0 "Conventional_Charging" ;
VAL_TABLE_ Unknown_FFFE_Invalid_FFFF 65535 "Invalid" 65534 "Unknown" ;
VAL_TABLE_ eCallNotification 3 "Not_Used" 2 "Active" 1 "Normal" 0 "Not_Supported" ;
VAL_TABLE_ eCallConfirmation 7 "Unused_2" 6 "CallComplete_DTMF_Timeout" 5 "eCall_Configured_Off" 4 "Call_Unsuccessful" 3 "Call_Cancelled" 2 "Call_Completed" 1 "Call_In_Progress" 0 "Normal" ;
VAL_TABLE_ SAPPAngleControlStat5 1 "StrgColTorqueExceed_EAROn" 0 "ExternalSigContentOKforEAC" ;
VAL_TABLE_ Closed_Open_Active_Fault 3 "Fault" 2 "Active" 1 "Open" 0 "Closed" ;
VAL_TABLE_ SAPPAngleControlStat2 1 "Rel_ExtSteeringAngleReqx" 0 "NoRel_ExtSteeringAngleReqx" ;
VAL_TABLE_ SAPPAngleControlStat3 1 "EARactiveNoReverseEngage" 0 "ExternalSigContentOKforEAC" ;
VAL_TABLE_ RstrnImpactEvntStatus 7 "Invalid" 6 "Not_Used_4" 5 "Threshold_2_Exceeded" 4 "Not_Used_3" 3 "Threshold_1_Exceeded" 2 "Not_Used_2" 1 "Not_Used_1" 0 "Normal" ;
VAL_TABLE_ EDRTriggerEvntSync 1 "Threshold_Exceeded" 0 "Normal" ;
VAL_TABLE_ EngTeColdPrtct_D_Stats 3 "Undefined" 2 "OK_to_Drive" 1 "Engine_Warning" 0 "Normal_Operation" ;
VAL_TABLE_ HILL_DESC_MC 7 "Fault_Detected" 6 "Cooling_Down" 5 "Abort_Apply_Brakes" 4 "Active" 3 "Disabled" 2 "Enabled" 1 "Off_Road" 0 "Normal" ;
VAL_TABLE_ Closed_Ajar 1 "Ajar" 0 "Closed" ;
VAL_TABLE_ Quality_Factor 3 "OK" 2 "Not_Within_Specifications" 1 "No_Data_Exists" 0 "Faulty" ;
VAL_TABLE_ Null_Day_Night 3 "NotUsed" 2 "Night" 1 "Day" 0 "Null" ;
VAL_TABLE_ Null_Flash_High 3 "NotUsed" 2 "High" 1 "Flash_to_Pass" 0 "Null" ;
VAL_TABLE_ TrnShifMde_D_RqDrv 7 "Undefined" 6 "Tow_Haul_Range_Select" 5 "Overdrive_Cancel" 4 "Tow_haul" 3 "Sport_Tip" 2 "Sport" 1 "Range_Select" 0 "Normal" ;
VAL_TABLE_ GearPos_D_Actl 15 "Unknown" 14 "Reverse" 13 "Undefined_5" 12 "Undefined_4" 11 "Undefined_3" 10 "Undefined_2" 9 "Undefined_1" 8 "Eighth" 7 "Seventh" 6 "Sixth" 5 "Fifth" 4 "Fourth" 3 "Third" 2 "Second" 1 "First" 0 "Neutral" ;
VAL_TABLE_ OffOn_SlowFast_Flash 3 "Fast_Flash" 2 "Slow_Flash" 1 "On" 0 "Off" ;
VAL_TABLE_ AwdStat_D_RqDsply 31 "NotUsed9" 30 "NotUsed8" 29 "NotUsed7" 28 "NotUsed6" 27 "NotUsed5" 26 "NotUsed4" 25 "NotUsed3" 24 "NotUsed2" 23 "Out_of_4Low_Crawl" 22 "AWD_PTU_Oil_Changed" 21 "Change_AWD_PTU_Oil" 20 "Neutral_Tow_Disabled" 19 "Neutral_Tow_Enabled" 18 "AWD_OFF" 17 "_4x4_Off_Road_Speed" 16 "_4x4_Extreme_Off_Road_Mode" 15 "_4x4_Exiting_Off_Road" 14 "_4x4_Off_Road_Mode" 10 "_4x4_Locked_Temporarily" 9 "Shift_In_Progress" 13 "Blocked_Shift_Assist" 12 "_4x4_Auto_Restored" 11 "_4x4_Disabled_Temporarily" 7 "Out_of_4Low__Neutral" 6 "Out_of_4Low__Brake" 5 "Out_of_4Low__Speed" 4 "Into_4Low__Clutch" 3 "Into_4Low__Neutral" 2 "Into_4Low__Brake" 1 "Into_4Low__Speed" 0 "Normal__No_Message" 8 "Out_of_4Low__Clutch" ;
VAL_TABLE_ AngleReached 1 "RequestedAngleNotReached" 0 "RequestedAngleCanBeReached" ;
VAL_TABLE_ WhlDir 3 "Failed" 2 "Unknown" 1 "Backward" 0 "Forward" ;
VAL_TABLE_ Unknown_Fault_1FE_1FF 511 "Fault" 510 "Unknown" ;
VAL_TABLE_ Fault_NoFault 1 "Fault" 0 "No_Fault" ;
VAL_TABLE_ TrnIpcDsplyMde_D_Actl 7 "Manual_3" 6 "Manual_2" 5 "Manual_1_Low" 4 "Sport" 3 "Drive" 2 "Neutral" 1 "Reverse" 0 "Park" ;
VAL_TABLE_ TrnIpcDsplyMde_D_Stat 3 "Reserved_Blank_No_Display" 2 "Flash" 1 "On" 0 "Blank_No_Display" ;
VAL_TABLE_ Unknown_Fault_7FE_7FF 2047 "Fault" 2046 "Unknown" ;
VAL_TABLE_ TerrMde_D_Actl 7 "Fail_Safe_Default" 6 "Dynamic_Mode" 5 "Rock_Crawl_Mode" 4 "Mud_Ruts_Mode" 3 "Sand_Mode" 2 "Undefined" 1 "Low_Mu_Mode" 0 "Special_Operating_Mode_Off" ;
VAL_TABLE_ TerrMdeChng_D_Rdy 7 "Fault" 6 "Undefined_2" 5 "Undefined_1" 4 "ModeUnavailDrInputRqd" 3 "SpOpModes_NotSupported" 2 "ModeUnavailDynamicCond" 1 "Module_In_Initialization" 0 "Mode_Change_Available" ;
VAL_TABLE_ Unknown_Fault_FFFE_FFFF 65535 "Fault" 65534 "Unknown" ;
VAL_TABLE_ Invalid_FFFFFF 16777215 "Invalid" ;
VAL_TABLE_ AutoParkSpdExitCond 1 "SpeedLimitExceededEAROn" 0 "ExternalSigContentOKforEAC" ;
VAL_TABLE_ HdcMde_D_Actl 7 "Fault" 6 "Temporarily_Unavailable" 5 "NotEnabled_WrongGearSel" 4 "NotEnabled_SpdLimitExceed" 3 "Active_Braking" 2 "Not_Active_Braking" 1 "Off" 0 "Undefined" ;
VAL_TABLE_ GearLvrPos_D_Actl 15 "Fault" 14 "Unknown_Position" 13 "Undefined_Treat_as__Fault" 12 "Undefined_Treat_as_Fault" 11 "sixth" 10 "fifth" 9 "fourth" 8 "third" 7 "second" 6 "first" 5 "Low" 4 "Sport_DriveSport" 3 "Drive" 2 "Neutral" 1 "Reverse" 0 "Park" ;
VAL_TABLE_ FcwMsgTxt_D_Rq 7 "Undefined_3" 6 "Undefined_2" 5 "Low_Visibility" 4 "Unavailable_DueTo_LowSpeed" 3 "Available" 2 "Unavailable" 1 "Off" 0 "No_Text" ;
VAL_TABLE_ FcwSens_B_Actl 3 "FCW_Sensitivity_3" 2 "FCW_Sensitivity_2" 1 "FCW_Sensitivity_1" 0 "Not_Used" ;
VAL_TABLE_ LastSettind_DefaultOn 1 "Default_On" 0 "Last_Setting" ;
VAL_TABLE_ EngTurboMde_D_Actl 3 "Fault" 2 "One_Turbo_Active" 1 "Two_Turbos_Active" 0 "Initializing" ;
VAL_TABLE_ EngMde_D_Rq 8 "VSC_Sets_Speed_Type_3" 7 "VSC_Sets_Speed_Type_2" 6 "VSC_Sets_Torque_Type_2" 5 "Dependability_Shutdown" 4 "Dependability_Follow" 3 "Start" 2 "VSC_Sets_Torque_Type_1" 1 "VSC_Sets_Speed_Type_1" 0 "Off" 15 "Undefined_7" 14 "Undefined_6" 13 "Undefined_5" 12 "Undefined_4" 11 "Undefined_3" 10 "Undefined_2" 9 "Undefined_1" ;
VAL_TABLE_ DrvHdcMsg_D_Rq 7 "Undefined" 6 "Speed_too_High" 5 "Temporarily_Unavailable" 4 "System_Fault" 3 "Select_Gear" 2 "Off" 1 "On" 0 "No_Message" ;
VAL_TABLE_ CmbbBrkPrchg_B_Rq 3 "Undefined" 2 "Level_2_PreCharge_Request" 1 "Level_1_PreCharge_Request" 0 "No_PreCharge_Request" ;
VAL_TABLE_ CmbbBaSens_D_Rq 3 "Level_3" 2 "Level_2" 1 "Level_1" 0 "Normal" ;
VAL_TABLE_ CcStat_D_Actl 7 "Undefined_2" 6 "Undefined_1" 5 "Active" 4 "Active_Que_Assist" 3 "Standby" 2 "Standby_Denied" 1 "Denied" 0 "Off" ;
VAL_TABLE_ CadsAudioMute_D_Rq 3 "Reserved" 2 "Partial_Audio_Mute" 1 "Full_Audio_Mute" 0 "No_Audio_Mute" ;
VAL_TABLE_ BpedDrvAppl_D_Actl 3 "_Not_Allowed" 2 "Driver_Braking" 1 "Driver_Not_Braking" 0 "Not_Allowed" ;
VAL_TABLE_ AslIconDsply_D_Rq 3 "Not_Used" 2 "On_Active" 1 "On_Passive" 0 "Off" ;
VAL_TABLE_ AccWarn_D_Dsply 3 "BrakeReleaseWarn_In_StopMd" 2 "Brake_Capacity_Warning" 1 "Cancel_Warning" 0 "No_Warning" ;
VAL_TABLE_ AccTrgDist2_D_Dsply 15 "DIST_ACTIVE_13_Farthest" 14 "DIST_ACTIVE_12" 13 "DIST_ACTIVE_11" 12 "DIST_ACTIVE_10" 11 "DIST_ACTIVE_9" 10 "DIST_ACTIVE_8" 9 "DIST_ACTIVE_7" 8 "DIST_ACTIVE_6" 7 "DIST_ACTIVE_5" 6 "DIST_ACTIVE_4" 5 "DIST_ACTIVE_3" 4 "DIST_ACTIVE_2" 3 "DIST_ACTIVE_1_Closest" 2 "DIST_ACTIVE_No_Target" 1 "DIST_STANDBY" 0 "DIST_OFF" ;
VAL_TABLE_ AccMsgTxt_D_Rq 15 "Undefined_2" 14 "NCC_Enabled_Warning" 13 "Driver_Intervene" 12 "Resume_Inhibited" 11 "Resume_to_FollowNewVehicle" 10 "Press_Brake_to_Hold" 9 "Only_Following_in_Low_Spd" 8 "PressAccelerator_to_Resume" 7 "Shift_Down" 6 "Press_Resume_to_Start" 5 "Turn_ESC_On_to_Enable_ACC" 4 "ACC_Overridden" 3 "Brake_Capacity_Warning" 2 "ACC_Cancelled" 1 "ACC_Unavailable" 0 "No_Text" ;
VAL_TABLE_ AccTGap_D_Dsply 7 "Undefined_2" 6 "Undefined_1" 5 "Time_Gap_5" 4 "Time_Gap_4" 3 "Time_Gap_3" 2 "Time_Gap_2" 1 "Time_Gap_1" 0 "Not_Used" ;
VAL_TABLE_ AccEngStat_D_Actl 7 "Undefined_2" 6 "Undefined_1" 5 "ACCSoonCancel_due_Low_Spd" 4 "Shift_Down_Recommendation" 3 "Shift_Up_Recommendation" 2 "ACCNotAllowedToBeActivated" 1 "ACCStandby_due_Auto_Cancel" 0 "Normal_Operation" ;
VAL_TABLE_ NotPressed_Pressed 1 "Pressed" 0 "Not_Pressed" ;
VAL_TABLE_ TrnGear_D_RqDrv 31 "Fault" 30 "NotUsed_25" 29 "NotUsed_24" 28 "NotUsed_23" 27 "NotUsed_22" 26 "Return_to_Park" 25 "NotUsed_20" 24 "NotUsed_19" 23 "NotUsed_18" 22 "NotUsed_17" 21 "Return_To_Park" 20 "NotUsed_15" 19 "NotUsed_14" 18 "NotUsed_13" 17 "NotUsed_12" 16 "Manual" 15 "Not_Used11" 14 "Not_Used10" 13 "NotUsed_9" 12 "NotUsed_8" 11 "NotUsed_7" 10 "NotUsed_6" 9 "NotUsed_5" 8 "Drive" 7 "NotUsed_4" 6 "NotUsed_3" 5 "NotUsed_2" 4 "Neutral" 3 "NotUsed_1" 2 "Reverse" 1 "Park" 0 "No_Gear" ;
VAL_TABLE_ DasWarn 3 "Undefined" 2 "Warning_Level_2" 1 "Warning_Level_1" 0 "No_Warning" ;
VAL_TABLE_ DasAlert 5 "Alertness_Level_5" 4 "Alertness_Level_4" 3 "Alertness_Level_3" 2 "Alertness_Level_2" 1 "Alertness_Level_1" 0 "Undefined" ;
VAL_TABLE_ DasStat 3 "Available" 2 "Unavailable_Other" 1 "Feedback_due_to_Speed" 0 "Off" ;
VAL_TABLE_ No_Crank_Req 1 "Crank_Request" 0 "No_Crank_Request" ;
VAL_TABLE_ DrvSlipCtlMde_D_Rq 3 "App_Specific_Off_Mode_3" 2 "App_Specific_Off_Mode_2" 1 "App_Specific_Off_Mode_1" 0 "Default_Mode" ;
VAL_TABLE_ AwdOffRoadMode 3 "Invalid" 2 "Extreme_Off_Road" 1 "Off_Road" 0 "Normal_Mode" ;
VAL_TABLE_ Normal_AdaptiveCruise 1 "Adaptive_Cruise" 0 "Normal_Cruise" ;
VAL_TABLE_ DieslPrtc_D_RqDsply 7 "Unused_2" 6 "Unused_1" 5 "DPF_SOOT_Level3_Blocked" 4 "DPFSootLvl2_SevereOverload" 3 "DPFRegen_ExhFilterComplete" 2 "DPFRegen_CleanExhFilter" 1 "DPF_Soot_Level1_Overloaded" 0 "DPF_OK_Normal_Operation" ;
VAL_TABLE_ Unknown_Fault_FFE_FFF 4095 "Fault" 4094 "Unknown" ;
VAL_TABLE_ Unknown_Fault_1FFE_1FFF 8191 "Fault" 8190 "Unknown" ;
VAL_TABLE_ TrnCnvtClu_D_Actl 3 "Transition_or_Micro_Slip" 2 "Lock_Up_Fixed" 1 "Lock_Up_Slip" 0 "No_Lock_Up" ;
VAL_TABLE_ InhibitNoinhibit 1 "Inhibit" 0 "No_Inibit" ;
VAL_TABLE_ DisableEnable 1 "Enable" 0 "Disable" ;
VAL_TABLE_ Unknown_Fault_7FFE_7FFF 32767 "Fault" 32766 "Unknown" ;
VAL_TABLE_ Side_Detect_Sn_State 3 "Second_Warning_Audio" 2 "System_Failure" 1 "Blocked" 0 "Clear" ;
VAL_TABLE_ Litval_values 255 "Invalid" 254 "Unknown" 5 "Day" 4 "Twilight_4" 3 "Twilight_3" 2 "Twilight_2" 1 "Twilight_1" 0 "Night" ;
VAL_TABLE_ Dimming_Lvl 255 "Invalid" 254 "Unknown" 18 "Day_6" 17 "Day_5" 16 "Day_4" 15 "Day_3" 14 "Day_2" 13 "Day_1" 12 "Night_12" 11 "Night_11" 10 "Night_10" 9 "Night_9" 8 "Night_8" 7 "Night_7" 6 "Night_6" 5 "Night_5" 4 "Night_4" 3 "Night_3" 2 "Night_2" 1 "Night_1" 0 "Off" ;
VAL_TABLE_ CamraStat 3 "FrtCam_TempUnavailOther" 2 "FrtCam_TempUnavailVisibile" 1 "Front_Camera_Service_Reqd" 0 "Front_Camera_OK" ;
VAL_TABLE_ NotReady_Ready_Invalid 3 "Invalid" 2 "Not_Used" 1 "Ready" 0 "Not_Ready" ;
VAL_TABLE_ EngPtoMde_D_Actl 7 "Undefined" 6 "Split_Shaft_Stationary" 5 "Not_Used_2" 4 "PTO_Mobile" 3 "Not_Used_1" 2 "PTO_Stationary" 1 "BCP" 0 "Off" ;
VAL_TABLE_ Remote_Start_Status 3 "Invalid" 2 "Unknown" 1 "Remote" 0 "Null" ;
VAL_TABLE_ Lock_Subld 15 "Unused7" 14 "Unused6" 13 "Unused5" 12 "Unused4" 11 "Unused3" 10 "Unused2" 9 "Unused1" 8 "Customer_8" 7 "Customer_7" 6 "Customer_6" 5 "Customer_5" 4 "Customer_4" 3 "Customer_3" 2 "Customer_2" 1 "Customer_1" 0 "Null" ;
VAL_TABLE_ OFF_ON_Unknown_Invalid 1 "On" 0 "Off" 3 "Invalid" 2 "Unknown" ;
VAL_TABLE_ Brake_Fluid 3 "Invalid" 2 "Unknown" 1 "Low" 0 "OK" ;
VAL_TABLE_ Unknown_Invalid_FE_FF 255 "Invalid" 254 "Unknown" ;
VAL_TABLE_ Invalid_FF 255 "Invalid" ;
VAL_TABLE_ NotLow_Low 1 "Low" 0 "Not_Low" ;
VAL_TABLE_ Key_In_Ignition_Status 1 "In" 0 "Out" ;
VAL_TABLE_ Ignition_Status 0 "Unknown" 1 "Off" 15 "Invalid" 8 "Start" 4 "Run" 2 "Accessory" ;
VAL_TABLE_ Disabled_Enabled_Faulted 3 "Faulted" 2 "Unused" 1 "Enabled" 0 "Disabled" ;
VAL_TABLE_ Unknown_Fault_FE_FF 255 "Fault" 254 "Unknown" ;
VAL_TABLE_ HsaStat_D_Actl 7 "Undefined" 6 "Failed" 5 "SlowRelease" 4 "FastRelease" 3 "ActiveBrakePedalReleased" 2 "ActiveBrakePedalPressed" 1 "FindingGradient" 0 "Inactive" ;
VAL_TABLE_ Off_Auto_Manual 3 "Undefined" 2 "Manual" 1 "Automatic" 0 "Off" ;
VAL_TABLE_ HsaStat_D_Dsply 7 "NotUsed3" 6 "NotUsed2" 5 "NotUsed1" 4 "NotAvailable" 3 "SlowReleaseWithChime" 2 "SlowReleaseWithoutChime" 1 "Active" 0 "Inactive" ;
VAL_TABLE_ PassRstrnInd_Stat 7 "Invalid" 6 "Unused_2" 5 "Unused_1" 4 "Both_Indicators_Faulted" 3 "AirbagOff_Indicator_fault" 2 "AirbagOn_Indicator_fault" 1 "Normal" 0 "Not_Supported" ;
VAL_TABLE_ PassRstrnInd_Req 3 "ABOnNotIllum_OffNotIllum" 2 "AirbagOnNot_Illum_OffIllum" 1 "AirbagOn_Illum_OffNotIllum" 0 "AirbagOn_Illum_Off_Illum" ;
VAL_TABLE_ RearDiffLckMsg_D_Rq 7 "Locker_Disabled" 6 "Locker_Enabled" 5 "Locker_Accel_Pedal" 4 "Locker_4Low_Speed" 3 "Locker_4High_Speed" 2 "Locker_4Auto_Speed" 1 "Locker_2High_Speed" 0 "Normal__No_Message " ;
VAL_TABLE_ DrvHdcWarnInfo_D_Rq 3 "Undefined" 2 "Lamp_On_Continuously" 1 "Lamp_Flashing" 0 "Lamp_Off_Continuously" ;
VAL_TABLE_ DieslPrtcRgen_D_Actl 3 "Undefined" 2 "Regen_Level_2" 1 "Regen_Level_1" 0 "No_regen" ;
VAL_TABLE_ Off_On 1 "On" 0 "Off" ;
VAL_TABLE_ CcMde_D_Actl 7 "TapDownWaiting" 6 "TapUpWaiting" 5 "Resuming_Low" 4 "Resuming_High" 3 "Decelerating" 2 "Accelerating" 1 "Keeping_Speed" 0 "Not_Active" ;
VAL_TABLE_ InactiveActive 1 "Active" 0 "Inactive" ;
VAL_TABLE_ Fault_FFFF 65535 "Fault" ;
VAL_TABLE_ NoYes 1 "Yes" 0 "No" ;
VAL_TABLE_ AwdRnge_D_Actl 7 "Unknown" 6 "High_Range_2wd" 5 "High_Range_Auto" 4 "High_Range_Locked" 3 "Neutral" 2 "Low_Range_2wd" 1 "Low_Range_Auto" 0 "Low_Range_Locked" ;
VAL_TABLE_ AwdLck_D_Stat 9 "Undefined" 8 "Under_External_Torque_Ctrl" 7 "Torque_Limited_by_Cmd" 6 "Fully_Locked_by_Cmd" 5 "Disabled" 4 "Warning" 3 "Fault" 2 "Inactive" 1 "Completely_Opened_by_Cmd" 0 "OK" ;
VAL_TABLE_ Unknown_Fault_3FE_3FF 1023 "Fault" 1022 "Unknown" ;
VAL_TABLE_ Null_Override 1 "Override" 0 "Null" ;
VAL_TABLE_ SAPPErrorCoding 32 "Error_32" 31 "Error_31" 30 "Error_30" 29 "Error_29" 28 "Error_28" 27 "Error_27" 26 "Error_26" 25 "Error_25" 24 "Error_24" 23 "Error_23" 22 "Error_22" 21 "Error_21" 20 "Error_20" 19 "Error_19" 18 "Error_18" 17 "Error_17" 16 "Error_16" 15 "Error_15" 14 "Error_14" 13 "Error_13" 12 "Error_12" 11 "Error_11" 10 "Error_10" 9 "Error_9" 8 "Error_8" 7 "Error_7" 6 "Error_6" 5 "Error_5" 4 "Error_4" 3 "Error_3" 2 "Error_2" 1 "Error_1" 0 "Not_Used" ;
VAL_TABLE_ Off_On_Flash 3 "Not_Used" 2 "Flash" 1 "On" 0 "Off" ;
VAL_TABLE_ immoTargetStatCoding 7 "Unused4" 6 "Unused3" 5 "Unused2" 4 "Unused1" 3 "DISABLED_RESET   " 2 "ENABLED_NONMOTIVE_START" 1 "ENABLED_MOTIVE_START" 0 "DISABLED" ;
VAL_TABLE_ BeltBuckle 3 "Unknown" 2 "Unbelted" 1 "Belted" 0 "Faulty" ;
VAL_TABLE_ RILStat 3 "Fault" 2 "Plant_Mode" 1 "On" 0 "Off" ;
VAL_TABLE_ RILReqCoding 3 "Not_Used" 2 "Plant_Mode" 1 "On" 0 "Off" ;
VAL_TABLE_ Update_Bit 1 "Fresh_data" 0 "Unchanged_data" ;
VAL_TABLE_ Tire_Pressure_System2 13 "Training_Complete" 12 "Train_InsideLeftRear_tire" 11 "Train_OutsideLeftRear_tire" 10 "Train_LeftRear_tire" 9 "Train_InsideRtRear_tire" 8 "Train_OutsideRtRear_tire" 7 "Train_RightRear_tire" 14 "Tires_not_trained" 6 "Train_RightFront_tire" 5 "Train_LeftFront_tire" 4 "Systm_Activ_Composite_Stat" 3 "Low_Composite_Stat" 2 "Sensr_Fault_Composite_Stat" 1 "Systm_Fault_Composite_Stat" 0 "Unknown_Composite_Stat" ;
VAL_TABLE_ HudFlashRate 3 "Unused" 2 "Flash_4Hz_50Prct_DutyCycle" 1 "On" 0 "Off" ;
VAL_TABLE_ Unknown_7FFF_7FFE_zzz 32767 "Invalid" 32766 "Unknown" ;
VAL_TABLE_ Turn_Seq 3 "Seq" 2 "On" 1 "Off" 0 "Null" ;
VAL_TABLE_ immoTargetCmdCoding 7 "Unused4" 6 "Unused3" 5 "Unused2" 4 "Unused1" 3 "TARGET1_IDBLOCK2" 2 "TARGET1_IDBLOCK1" 1 "CHALLENGE" 0 "IDLE" ;
VAL_TABLE_ immoSubTargetCmdCoding 7 "Unused3" 6 "Unused2" 5 "ECHO_TARGET1_IDBLOCK2" 4 "Unused1" 3 "RQST_TARGET1_IDBLOCK2" 2 "RQST_TARGET1_IDBLOCK1" 1 "RESPONSE" 0 "IDLE" ;
VAL_TABLE_ Electric_EOH 1 "Electric_Over_Hydraulic" 0 "Electric" ;
VAL_TABLE_ PersOptIn 1 "OPTED_IN" 0 "NOT_OPTED_IN" ;
VAL_TABLE_ PersonalSetUp 3 "Non_Moveable_Person" 2 "Moveable_Person" 1 "Vehicle" 0 "Factory" ;
VAL_TABLE_ Full_Limited 1 "Limited" 0 "Full" ;
VAL_TABLE_ NoConflict_Conflict 1 "Conflict" 0 "No_Conflict" ;
VAL_TABLE_ Assoc_Confirm 0 "None" 7 "Associate" 6 "Keycode_Rejected" 5 "Keycode_Accepted" 4 "In_Progress" 3 "Erase" 2 "Duplicate" 1 "Disassociate" ;
VAL_TABLE_ Pers1_4 7 "Unused_3" 6 "Unused_2" 5 "Unused_1" 4 "Vehicle" 3 "PERS_4" 2 "PERS_3" 1 "PERS_2" 0 "PERS_1" ;
VAL_TABLE_ Null_Query 7 "Unused_2" 6 "Unused_1" 5 "Copy" 4 "Restore" 3 "Upload" 2 "Set" 1 "Query" 0 "Null" ;
VAL_TABLE_ RearDiffFalt_D_Stat 3 "Diff_Failed_Closed" 2 "Diff_Failed_Open" 1 "Fault_Non_Specific" 0 "No_Fault" ;
VAL_TABLE_ CCOverridden 1 "Cruise_Overridden" 0 "Cruise_Req_Not_Overridden" ;
VAL_TABLE_ Ign_Key_Device_Type 15 "Invalid" 14 "Unknown" 3 "Key_Not_Prgrm_Read_Failure" 2 "Key_In_Ign_My_Key" 1 "Key_In_Ign_Standard_Key" 0 "Key_Read_In_Progress" ;
VAL_TABLE_ Off_No_Eff_Unknown_Invalid 3 "Invalid" 2 "Unknown" 1 "No_Effect" 0 "Off" ;
VAL_TABLE_ Null_Out 1 "Out" 0 "Null" ;

BO_ 1100 GatewayData2_HS2: 8 GWM
 SG_ GrossTrainWeight_M_Est_UB : 15|1@0+ (1,0) [0|1] "SED"  TCCM
 SG_ GrossTrainWeight_M_Est : 7|8@0+ (100,0) [0|25300] "kilogram"  TCCM

BO_ 370 TransData_2_HS2: 8 GWM
 SG_ GearPos_D_Actl : 55|4@0+ (1,0) [0|15] "SED"  IPMB

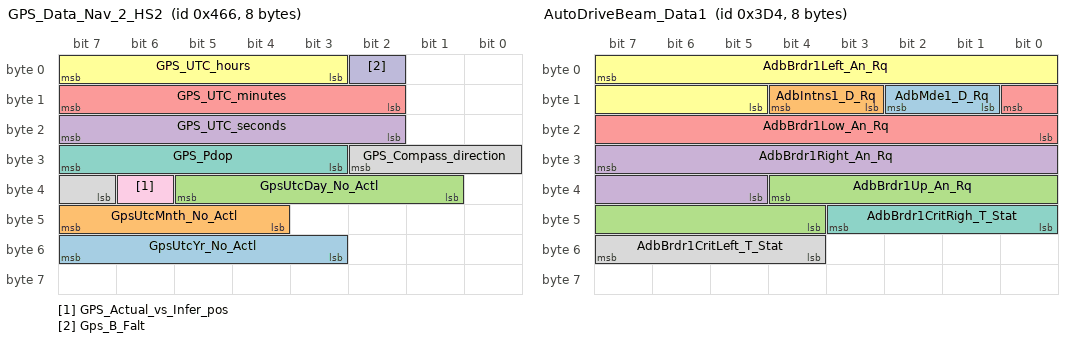
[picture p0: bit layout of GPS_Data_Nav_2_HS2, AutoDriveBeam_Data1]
BO_ 1126 GPS_Data_Nav_2_HS2: 8 GWM
 SG_ GpsUtcYr_No_Actl : 55|5@0+ (1,2010) [2010|2040] "Year"  IPMA
 SG_ GpsUtcMnth_No_Actl : 47|4@0+ (1,1) [1|15] "Month"  IPMA
 SG_ GpsUtcDay_No_Actl : 37|5@0+ (1,1) [1|32] "Day"  IPMA
 SG_ GPS_UTC_seconds : 23|6@0+ (1,0) [0|59] "seconds"  IPMA
 SG_ GPS_UTC_minutes : 15|6@0+ (1,0) [0|59] "Minutes"  IPMA
 SG_ GPS_UTC_hours : 7|5@0+ (1,0) [0|23] "Hours"  IPMA
 SG_ GPS_Pdop : 31|5@0+ (0.2,0) [0|5.8] "unitless" Vector__XXX
 SG_ GPS_Compass_direction : 26|4@0+ (1,0) [0|15] "SED" Vector__XXX
 SG_ GPS_Actual_vs_Infer_pos : 38|1@0+ (1,0) [0|1] "SED"  IPMA
 SG_ Gps_B_Falt : 2|1@0+ (1,0) [0|1] "SED"  IPMA

BO_ 1215 ElecHorizon_Data2_HS2: 8 GWM
 SG_ EhData2_No_Actl : 7|64@0+ (1,0) [0|1.844674407371E+019] "unitless"  IPMA

BO_ 1214 ElecHorizon_Data1_HS2: 8 GWM
 SG_ EhData1_No_Actl : 7|64@0+ (1,0) [0|1.844674407371E+019] "unitless"  IPMA

BO_ 980 AutoDriveBeam_Data1: 8 IPMA
 SG_ AdbMde1_D_Rq : 10|2@0+ (1,0) [0|3] "SED"  GWM
 SG_ AdbIntns1_D_Rq : 12|2@0+ (1,0) [0|3] "SED"  GWM
 SG_ AdbBrdr1Up_An_Rq : 36|9@0+ (0.02,-8) [-8|2.18] "degrees"  GWM
 SG_ AdbBrdr1Right_An_Rq : 31|11@0+ (0.02,-20) [-20|20.9] "degrees"  GWM
 SG_ AdbBrdr1Low_An_Rq : 8|9@0+ (0.02,-8) [-8|2.18] "degrees"  GWM
 SG_ AdbBrdr1Left_An_Rq : 7|11@0+ (0.02,-20) [-20|20.9] "degrees"  GWM
 SG_ AdbBrdr1CritRigh_T_Stat : 43|4@0+ (100,0) [0|1500] "millisecond"  GWM
 SG_ AdbBrdr1CritLeft_T_Stat : 55|4@0+ (100,0) [0|1500] "millisecond"  GWM

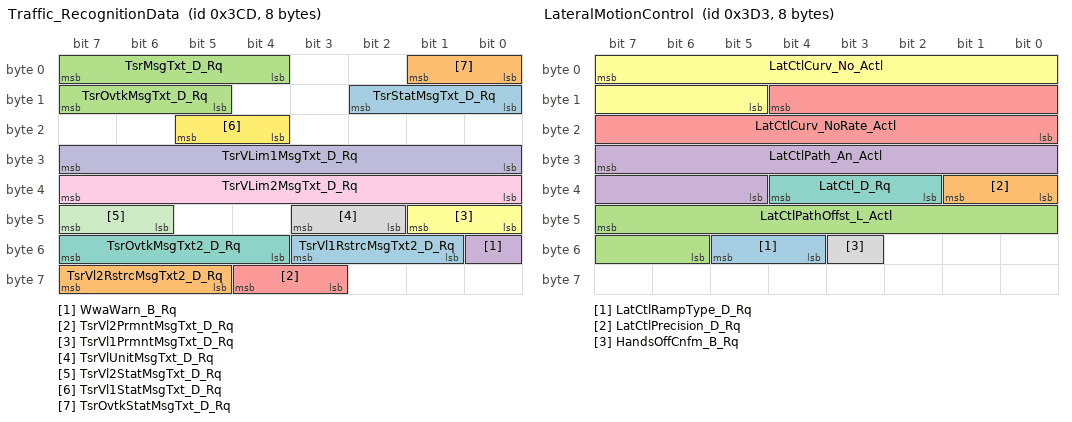
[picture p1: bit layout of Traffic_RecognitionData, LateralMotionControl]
BO_ 973 Traffic_RecognitionData: 8 IPMA
 SG_ TsrVl1RstrcMsgTxt2_D_Rq : 51|3@0+ (1,0) [0|7] "SED" Vector__XXX
 SG_ TsrVl2RstrcMsgTxt2_D_Rq : 63|3@0+ (1,0) [0|7] "SED" Vector__XXX
 SG_ TsrOvtkMsgTxt_D_Rq : 15|3@0+ (1,0) [0|7] "SED" Vector__XXX
 SG_ WwaWarn_B_Rq : 48|1@0+ (1,0) [0|1] "SED"  GWM
 SG_ TsrVl2PrmntMsgTxt_D_Rq : 60|2@0+ (1,0) [0|3] "SED"  GWM
 SG_ TsrVl1PrmntMsgTxt_D_Rq : 41|2@0+ (1,0) [0|3] "SED"  GWM
 SG_ TsrOvtkMsgTxt2_D_Rq : 55|4@0+ (1,0) [0|15] "SED"  GWM
 SG_ TsrVlUnitMsgTxt_D_Rq : 43|2@0+ (1,0) [0|3] "SED"  GWM
 SG_ TsrVLim2MsgTxt_D_Rq : 39|8@0+ (1,0) [0|255] "SED"  GWM
 SG_ TsrVLim1MsgTxt_D_Rq : 31|8@0+ (1,0) [0|255] "SED"  GWM
 SG_ TsrVl2StatMsgTxt_D_Rq : 47|2@0+ (1,0) [0|3] "SED"  GWM
 SG_ TsrVl1StatMsgTxt_D_Rq : 21|2@0+ (1,0) [0|3] "SED"  GWM
 SG_ TsrStatMsgTxt_D_Rq : 10|3@0+ (1,0) [0|7] "SED"  GWM
 SG_ TsrOvtkStatMsgTxt_D_Rq : 1|2@0+ (1,0) [0|3] "SED"  GWM
 SG_ TsrMsgTxt_D_Rq : 7|4@0+ (1,0) [0|15] "SED"  GWM

BO_ 979 LateralMotionControl: 8 IPMA
 SG_ LatCtlRampType_D_Rq : 53|2@0+ (1,0) [0|3] "SED" Vector__XXX
 SG_ LatCtlPrecision_D_Rq : 33|2@0+ (1,0) [0|3] "SED" Vector__XXX
 SG_ LatCtlPathOffst_L_Actl : 47|10@0+ (0.01,-5.12) [-5.12|5.11] "meter" Vector__XXX
 SG_ LatCtlPath_An_Actl : 31|11@0+ (0.005,-0.5) [-0.5|0.5235] "radians" Vector__XXX
 SG_ LatCtlCurv_NoRate_Actl : 12|13@0+ (2.5E-007,-0.001024) [-0.001024|0.00102375] "1/meter" Vector__XXX
 SG_ LatCtlCurv_No_Actl : 7|11@0+ (2E-005,-0.02) [-0.02|0.02094] "1/meter" Vector__XXX
 SG_ LatCtl_D_Rq : 36|3@0+ (1,0) [0|7] "SED" Vector__XXX
 SG_ HandsOffCnfm_B_Rq : 51|1@0+ (1,0) [0|1] "SED" Vector__XXX

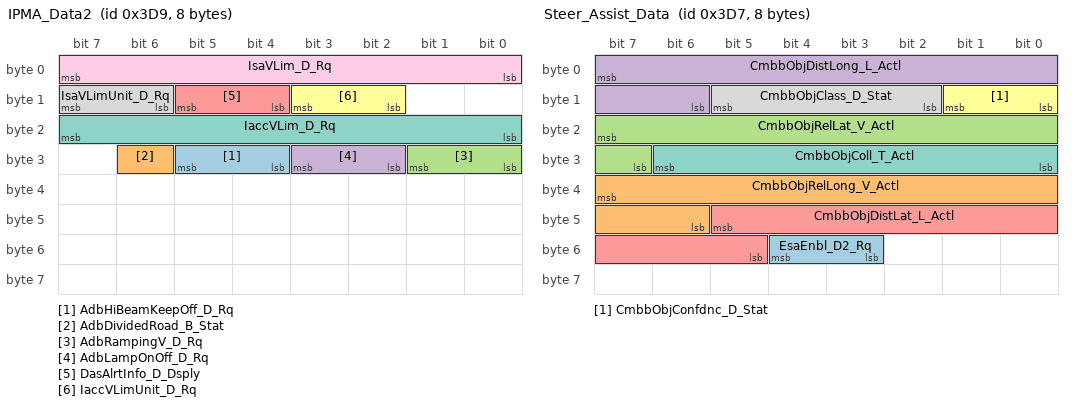
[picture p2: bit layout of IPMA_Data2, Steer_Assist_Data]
BO_ 985 IPMA_Data2: 8 IPMA
 SG_ AdbHiBeamKeepOff_D_Rq : 29|2@0+ (1,0) [0|3] "SED"  GWM
 SG_ AdbDividedRoad_B_Stat : 30|1@0+ (1,0) [0|1] "SED"  GWM
 SG_ AdbRampingV_D_Rq : 25|2@0+ (1,0) [0|3] "SED"  GWM
 SG_ AdbLampOnOff_D_Rq : 27|2@0+ (1,0) [0|3] "SED"  GWM
 SG_ DasAlrtInfo_D_Dsply : 13|2@0+ (1,0) [0|3] "SED"  GWM
 SG_ IaccVLimUnit_D_Rq : 11|2@0+ (1,0) [0|3] "SED"  GWM
 SG_ IaccVLim_D_Rq : 23|8@0+ (1,0) [0|255] "SED"  GWM
 SG_ IsaVLimUnit_D_Rq : 15|2@0+ (1,0) [0|3] "SED"  GWM
 SG_ IsaVLim_D_Rq : 7|8@0+ (1,0) [0|255] "SED"  GWM

BO_ 983 Steer_Assist_Data: 8 IPMA
 SG_ EsaEnbl_D2_Rq : 52|2@0+ (1,0) [0|3] "SED" Vector__XXX
 SG_ CmbbObjRelLong_V_Actl : 39|10@0+ (0.1,-102.1) [-102.1|0] "meters/sec" Vector__XXX
 SG_ CmbbObjRelLat_V_Actl : 23|9@0+ (0.1,-25.5) [-25.5|25.4] "meters/sec" Vector__XXX
 SG_ CmbbObjDistLong_L_Actl : 7|10@0+ (0.1,0) [0|102.1] "meter" Vector__XXX
 SG_ CmbbObjDistLat_L_Actl : 45|9@0+ (0.1,-25.5) [-25.5|25.4] "meter" Vector__XXX
 SG_ CmbbObjConfdnc_D_Stat : 9|2@0+ (1,0) [0|3] "SED" Vector__XXX
 SG_ CmbbObjColl_T_Actl : 30|7@0+ (0.05,0) [0|6.25] "second" Vector__XXX
 SG_ CmbbObjClass_D_Stat : 13|4@0+ (1,0) [0|15] "SED" Vector__XXX

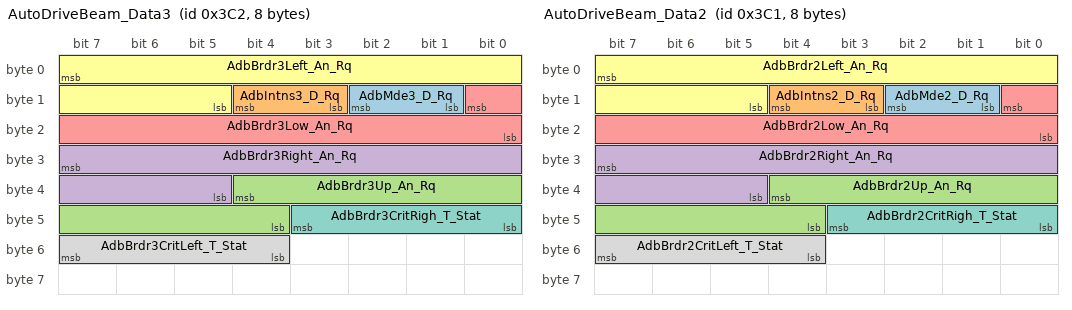
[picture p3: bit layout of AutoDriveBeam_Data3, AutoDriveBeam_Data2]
BO_ 962 AutoDriveBeam_Data3: 8 IPMA
 SG_ AdbMde3_D_Rq : 10|2@0+ (1,0) [0|3] "SED"  GWM
 SG_ AdbIntns3_D_Rq : 12|2@0+ (1,0) [0|3] "SED"  GWM
 SG_ AdbBrdr3Up_An_Rq : 36|9@0+ (0.02,-8) [-8|2.18] "degrees"  GWM
 SG_ AdbBrdr3Right_An_Rq : 31|11@0+ (0.02,-20) [-20|20.9] "degrees"  GWM
 SG_ AdbBrdr3Low_An_Rq : 8|9@0+ (0.02,-8) [-8|2.18] "degrees"  GWM
 SG_ AdbBrdr3Left_An_Rq : 7|11@0+ (0.02,-20) [-20|20.9] "degrees"  GWM
 SG_ AdbBrdr3CritRigh_T_Stat : 43|4@0+ (100,0) [0|1500] "millisecond"  GWM
 SG_ AdbBrdr3CritLeft_T_Stat : 55|4@0+ (100,0) [0|1500] "millisecond"  GWM

BO_ 961 AutoDriveBeam_Data2: 8 IPMA
 SG_ AdbMde2_D_Rq : 10|2@0+ (1,0) [0|3] "SED"  GWM
 SG_ AdbIntns2_D_Rq : 12|2@0+ (1,0) [0|3] "SED"  GWM
 SG_ AdbBrdr2Up_An_Rq : 36|9@0+ (0.02,-8) [-8|2.18] "degrees"  GWM
 SG_ AdbBrdr2Right_An_Rq : 31|11@0+ (0.02,-20) [-20|20.9] "degrees"  GWM
 SG_ AdbBrdr2Low_An_Rq : 8|9@0+ (0.02,-8) [-8|2.18] "degrees"  GWM
 SG_ AdbBrdr2Left_An_Rq : 7|11@0+ (0.02,-20) [-20|20.9] "degrees"  GWM
 SG_ AdbBrdr2CritRigh_T_Stat : 43|4@0+ (100,0) [0|1500] "millisecond"  GWM
 SG_ AdbBrdr2CritLeft_T_Stat : 55|4@0+ (100,0) [0|1500] "millisecond"  GWM

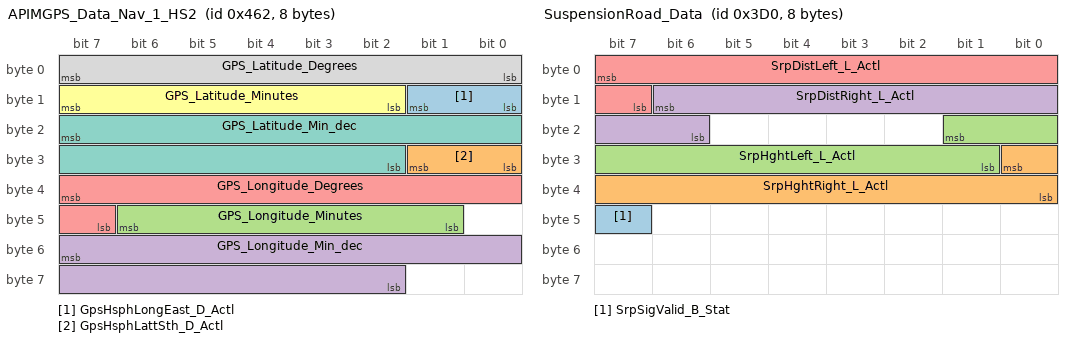
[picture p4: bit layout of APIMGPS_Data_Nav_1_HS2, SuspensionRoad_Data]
BO_ 1122 APIMGPS_Data_Nav_1_HS2: 8 GWM
 SG_ GpsHsphLongEast_D_Actl : 9|2@0+ (1,0) [0|3] "SED"  IPMA
 SG_ GpsHsphLattSth_D_Actl : 25|2@0+ (1,0) [0|3] "SED"  IPMA
 SG_ GPS_Longitude_Minutes : 46|6@0+ (1,0) [0|61] "Minutes"  IPMA
 SG_ GPS_Longitude_Min_dec : 55|14@0+ (0.0001,0) [0|1.6381] "Minutes"  IPMA
 SG_ GPS_Longitude_Degrees : 39|9@0+ (1,-179) [-179|330] "Degrees"  IPMA
 SG_ GPS_Latitude_Minutes : 15|6@0+ (1,0) [0|61] "Minutes"  IPMA
 SG_ GPS_Latitude_Min_dec : 23|14@0+ (0.0001,0) [0|1.6381] "Minutes"  IPMA
 SG_ GPS_Latitude_Degrees : 7|8@0+ (1,-89) [-89|164] "Degrees"  IPMA

BO_ 976 SuspensionRoad_Data: 8 IPMA
 SG_ SrpSigValid_B_Stat : 47|1@0+ (1,0) [0|1] "SED" Vector__XXX
 SG_ SrpHghtRight_L_Actl : 24|9@0+ (0.000625,-0.16) [-0.16|0.15875] "meter" Vector__XXX
 SG_ SrpHghtLeft_L_Actl : 17|9@0+ (0.000625,-0.16) [-0.16|0.15875] "meter" Vector__XXX
 SG_ SrpDistRight_L_Actl : 14|9@0+ (0.02,0) [0|10.2] "meter" Vector__XXX
 SG_ SrpDistLeft_L_Actl : 7|9@0+ (0.02,0) [0|10.2] "meter" Vector__XXX

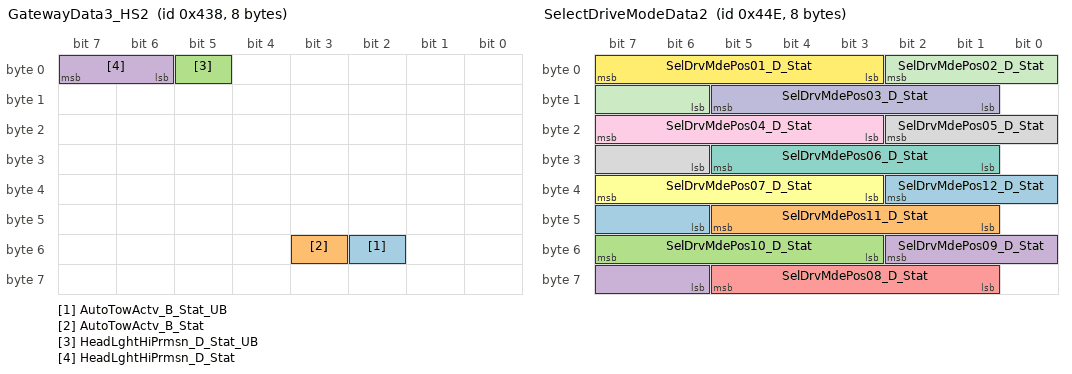
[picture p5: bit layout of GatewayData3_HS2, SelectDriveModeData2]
BO_ 1080 GatewayData3_HS2: 8 GWM
 SG_ AutoTowActv_B_Stat_UB : 50|1@0+ (1,0) [0|1] "SED" Vector__XXX
 SG_ AutoTowActv_B_Stat : 51|1@0+ (1,0) [0|1] "SED"  IPMA
 SG_ HeadLghtHiPrmsn_D_Stat_UB : 5|1@0+ (1,0) [0|1] "SED"  SCCM,IPMA
 SG_ HeadLghtHiPrmsn_D_Stat : 7|2@0+ (1,0) [0|3] "SED"  SCCM,IPMA

BO_ 945 Body_Info_7_HS2: 8 GWM
 SG_ KeyOffMde_D_Actl : 7|4@0+ (1,0) [0|15] "SED" Vector__XXX

BO_ 1053 Torque_Request: 8 ABS_ESC
 SG_ VehStab_D_Stat : 23|4@0+ (1,0) [0|15] "SED"  GWM

BO_ 1102 SelectDriveModeData2: 8 ABS_ESC
 SG_ SelDrvMdePos12_D_Stat : 34|5@0+ (1,0) [0|31] "SED"  GWM
 SG_ SelDrvMdePos11_D_Stat : 45|5@0+ (1,0) [0|31] "SED"  GWM
 SG_ SelDrvMdePos10_D_Stat : 55|5@0+ (1,0) [0|31] "SED"  GWM
 SG_ SelDrvMdePos09_D_Stat : 50|5@0+ (1,0) [0|31] "SED"  GWM
 SG_ SelDrvMdePos08_D_Stat : 61|5@0+ (1,0) [0|31] "SED"  GWM
 SG_ SelDrvMdePos07_D_Stat : 39|5@0+ (1,0) [0|31] "SED"  GWM
 SG_ SelDrvMdePos06_D_Stat : 29|5@0+ (1,0) [0|31] "SED"  GWM
 SG_ SelDrvMdePos05_D_Stat : 18|5@0+ (1,0) [0|31] "SED"  GWM
 SG_ SelDrvMdePos04_D_Stat : 23|5@0+ (1,0) [0|31] "SED"  GWM
 SG_ SelDrvMdePos03_D_Stat : 13|5@0+ (1,0) [0|31] "SED"  GWM
 SG_ SelDrvMdePos02_D_Stat : 2|5@0+ (1,0) [0|31] "SED"  GWM
 SG_ SelDrvMdePos01_D_Stat : 7|5@0+ (1,0) [0|31] "SED"  GWM

BO_ 1056 SelectDriveModeData: 8 ABS_ESC
 SG_ SelDrvMde_D_Stat : 26|2@0+ (1,0) [0|3] "SED"  GWM
 SG_ ActvDrvMde_D2_Stat : 53|5@0+ (1,0) [0|31] "SED"  IPMA,GWM
 SG_ SelDrvMde_D2_Rq : 63|5@0+ (1,0) [0|31] "SED"  GWM
 SG_ SelDrvMdePos12_B_Avail : 54|1@0+ (1,0) [0|1] "SED"  GWM
 SG_ SelDrvMdePos11_B_Avail : 55|1@0+ (1,0) [0|1] "SED"  GWM
 SG_ SelDrvMdePos10_B_Avail : 40|1@0+ (1,0) [0|1] "SED"  GWM
 SG_ SelDrvMdePos09_B_Avail : 41|1@0+ (1,0) [0|1] "SED"  GWM
 SG_ SelDrvMdePos08_B_Avail : 42|1@0+ (1,0) [0|1] "SED"  GWM
 SG_ SelDrvMdePos07_B_Avail : 43|1@0+ (1,0) [0|1] "SED"  GWM
 SG_ SelDrvMdePos06_B_Avail : 44|1@0+ (1,0) [0|1] "SED"  GWM
 SG_ SelDrvMdePos05_B_Avail : 45|1@0+ (1,0) [0|1] "SED"  GWM
 SG_ SelDrvMdePos04_B_Avail : 46|1@0+ (1,0) [0|1] "SED"  GWM
 SG_ SelDrvMdePos03_B_Avail : 47|1@0+ (1,0) [0|1] "SED"  GWM
 SG_ SelDrvMdePos02_B_Avail : 32|1@0+ (1,0) [0|1] "SED"  GWM
 SG_ SelDrvMdePos01_B_Avail : 24|1@0+ (1,0) [0|1] "SED"  GWM
 SG_ SelDrvMdePt_D_Rq : 31|5@0+ (1,0) [0|31] "SED"  TCCM,GWM
 SG_ SelDrvMdeMsgTxt_D_Rq : 19|4@0+ (1,0) [0|0] "SED"  GWM
 SG_ AwdMde_D_RqBrk : 35|3@0+ (1,0) [0|7] "SED"  GWM

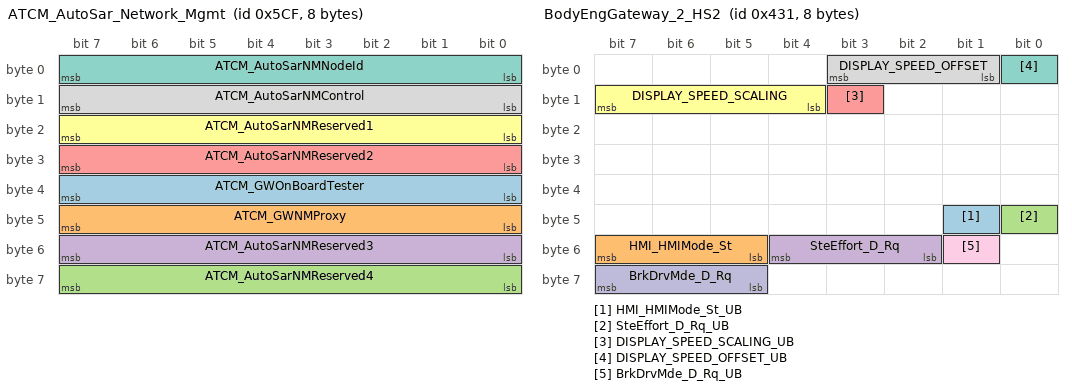
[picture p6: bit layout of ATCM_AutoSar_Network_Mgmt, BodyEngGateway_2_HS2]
BO_ 1487 ATCM_AutoSar_Network_Mgmt: 8 ATCM_FFSM
 SG_ ATCM_GWOnBoardTester : 39|8@0+ (1,0) [0|255] "unitless"  GWM
 SG_ ATCM_GWNMProxy : 47|8@0+ (1,0) [0|255] "unitless"  GWM
 SG_ ATCM_AutoSarNMReserved4 : 63|8@0+ (1,0) [0|255] "unitless"  GWM
 SG_ ATCM_AutoSarNMReserved3 : 55|8@0+ (1,0) [0|255] "unitless"  GWM
 SG_ ATCM_AutoSarNMReserved2 : 31|8@0+ (1,0) [0|255] "unitless"  GWM
 SG_ ATCM_AutoSarNMReserved1 : 23|8@0+ (1,0) [0|255] "unitless"  GWM
 SG_ ATCM_AutoSarNMNodeId : 7|8@0+ (1,0) [0|255] "unitless"  GWM
 SG_ ATCM_AutoSarNMControl : 15|8@0+ (1,0) [0|255] "unitless"  GWM

BO_ 1938 TesterPhysicalReqATCM: 8 TSTR
 SG_ TesterPhysicalReqATCM : 7|64@0+ (1,0) [0|1.84467E+019] "unitless"  ATCM_FFSM

BO_ 1120 FourByFourSwitchData: 8 ATCM_FFSM
 SG_ RearDiffLck_D_RqDrv : 4|2@0+ (1,0) [0|3] "SED"  GWM,TCCM
 SG_ AwdMde_D_RqDrv : 7|3@0+ (1,0) [0|7] "SED"  GWM,TCCM

BO_ 1946 TesterPhysicalResATCM: 8 ATCM_FFSM
 SG_ TesterPhysicalResATCM : 7|64@0+ (1,0) [0|1.84467E+019] "unitless"  TSTR

BO_ 1110 Power_Stat_HS2: 8 GWM
 SG_ RstrnMdulePw_D_Falt : 7|2@0+ (1,0) [0|3] "SED"  RCM

BO_ 1073 BodyEngGateway_2_HS2: 8 GWM
 SG_ HMI_HMIMode_St_UB : 41|1@0+ (1,0) [0|1] "SED"  SCCM
 SG_ HMI_HMIMode_St : 55|3@0+ (1,0) [0|7] "SED"  SCCM
 SG_ SteEffort_D_Rq_UB : 40|1@0+ (1,0) [0|1] "SED"  PSCM
 SG_ SteEffort_D_Rq : 52|3@0+ (1,0) [0|7] "SED"  PSCM
 SG_ DISPLAY_SPEED_SCALING_UB : 11|1@0+ (1,0) [0|1] "SED"  IPMA
 SG_ DISPLAY_SPEED_SCALING : 15|4@0+ (0.5,100) [100|107.5] "%"  IPMA
 SG_ DISPLAY_SPEED_OFFSET_UB : 0|1@0+ (1,0) [0|1] "SED"  IPMA
 SG_ DISPLAY_SPEED_OFFSET : 3|3@0+ (0.5,0) [0|3.5] "kph"  IPMA
 SG_ BrkDrvMde_D_Rq_UB : 49|1@0+ (1,0) [0|1] "SED" Vector__XXX
 SG_ BrkDrvMde_D_Rq : 63|3@0+ (1,0) [0|7] "SED" Vector__XXX

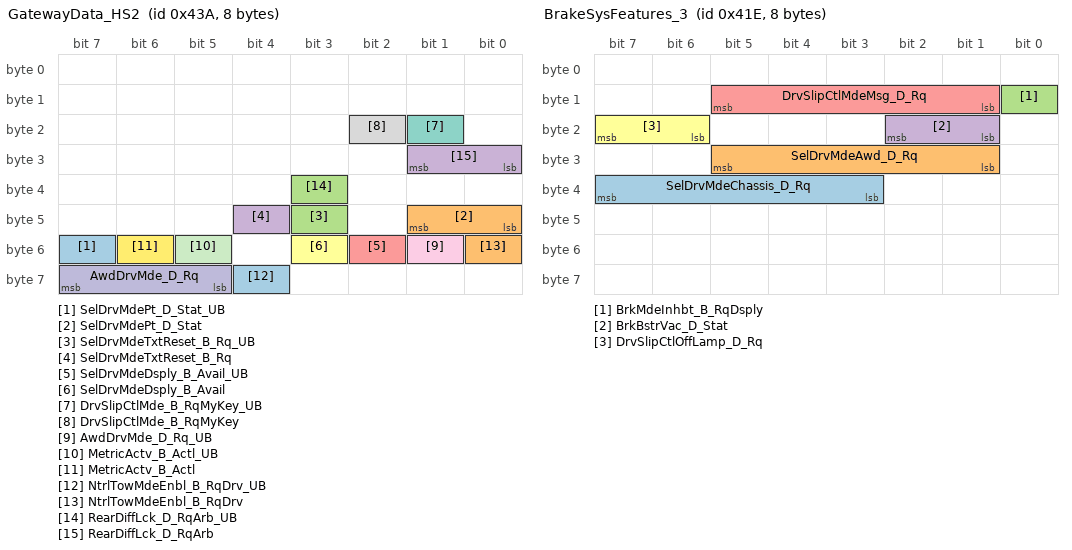
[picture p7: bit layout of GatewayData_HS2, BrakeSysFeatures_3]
BO_ 1082 GatewayData_HS2: 8 GWM
 SG_ SelDrvMdePt_D_Stat_UB : 55|1@0+ (1,0) [0|1] "SED"  ABS_ESC
 SG_ SelDrvMdePt_D_Stat : 41|2@0+ (1,0) [0|3] "SED"  ABS_ESC
 SG_ SelDrvMdeTxtReset_B_Rq_UB : 43|1@0+ (1,0) [0|1] "SED" Vector__XXX
 SG_ SelDrvMdeTxtReset_B_Rq : 44|1@0+ (1,0) [0|1] "SED"  ABS_ESC
 SG_ SelDrvMdeDsply_B_Avail_UB : 50|1@0+ (1,0) [0|1] "SED"  ABS_ESC
 SG_ SelDrvMdeDsply_B_Avail : 51|1@0+ (1,0) [0|1] "SED"  ABS_ESC
 SG_ DrvSlipCtlMde_B_RqMyKey_UB : 17|1@0+ (1,0) [0|1] "SED" Vector__XXX
 SG_ DrvSlipCtlMde_B_RqMyKey : 18|1@0+ (1,0) [0|1] "SED"  ABS_ESC
 SG_ AwdDrvMde_D_Rq_UB : 49|1@0+ (1,0) [0|1] "SED" Vector__XXX
 SG_ AwdDrvMde_D_Rq : 63|3@0+ (1,0) [0|7] "SED"  TCCM
 SG_ MetricActv_B_Actl_UB : 53|1@0+ (1,0) [0|1] "SED"  IPMA
 SG_ MetricActv_B_Actl : 54|1@0+ (1,0) [0|1] "SED"  IPMA
 SG_ NtrlTowMdeEnbl_B_RqDrv_UB : 60|1@0+ (1,0) [0|1] "SED" Vector__XXX
 SG_ NtrlTowMdeEnbl_B_RqDrv : 48|1@0+ (1,0) [0|1] "SED"  TCCM
 SG_ RearDiffLck_D_RqArb_UB : 35|1@0+ (1,0) [0|1] "SED" Vector__XXX
 SG_ RearDiffLck_D_RqArb : 25|2@0+ (1,0) [0|3] "SED" Vector__XXX

BO_ 1059 PowertrainData2_HS2: 8 GWM
 SG_ TrlrTrgtAcquire_D_Rq_UB : 9|1@0+ (1,0) [0|1] "SED"  IPMB
 SG_ TrlrTrgtAcquire_D_Rq : 12|3@0+ (1,0) [0|7] "SED"  IPMB

BO_ 1054 BrakeSysFeatures_3: 8 ABS_ESC
 SG_ SelDrvMdeChassis_D_Rq : 39|5@0+ (1,0) [0|31] "SED" Vector__XXX
 SG_ SelDrvMdeAwd_D_Rq : 29|5@0+ (1,0) [0|31] "SED" Vector__XXX
 SG_ BrkMdeInhbt_B_RqDsply : 8|1@0+ (1,0) [0|1] "SED"  GWM
 SG_ BrkBstrVac_D_Stat : 18|2@0+ (1,0) [0|3] "SED"  GWM
 SG_ DrvSlipCtlMdeMsg_D_Rq : 13|5@0+ (1,0) [0|31] "SED"  GWM
 SG_ DrvSlipCtlOffLamp_D_Rq : 23|2@0+ (1,0) [0|3] "SED"  GWM

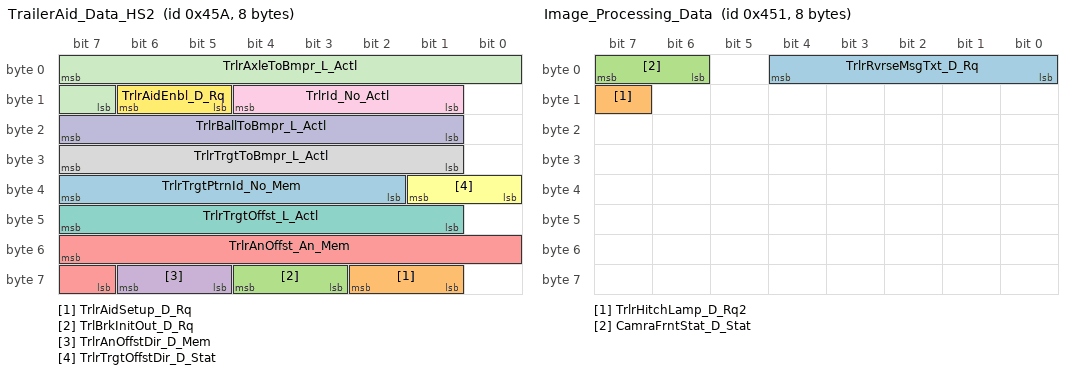
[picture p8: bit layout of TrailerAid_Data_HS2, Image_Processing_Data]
BO_ 1114 TrailerAid_Data_HS2: 8 GWM
 SG_ TrlrTrgtPtrnId_No_Mem : 39|6@0+ (1,0) [0|63] "unitless"  IPMB,GWM
 SG_ TrlrAidSetup_D_Rq : 58|2@0+ (1,0) [0|3] "SED"  IPMB,PSCM
 SG_ TrlBrkInitOut_D_Rq : 60|2@0+ (1,0) [0|3] "SED"  TBM
 SG_ TrlrAnOffstDir_D_Mem : 62|2@0+ (1,0) [0|3] "SED"  PSCM,IPMB
 SG_ TrlrAnOffst_An_Mem : 55|9@0+ (0.1,0) [0|51.1] "degrees"  PSCM,IPMB
 SG_ TrlrTrgtOffstDir_D_Stat : 33|2@0+ (1,0) [0|3] "SED"  IPMB
 SG_ TrlrTrgtOffst_L_Actl : 47|7@0+ (0.0127,0) [0|1.6129] "meter"  PSCM,IPMB
 SG_ TrlrTrgtToBmpr_L_Actl : 31|7@0+ (0.0127,0) [0|1.6129] "meter"  PSCM,IPMB
 SG_ TrlrId_No_Actl : 12|4@0+ (1,0) [0|15] "unitless"  IPMB,PSCM
 SG_ TrlrBallToBmpr_L_Actl : 23|7@0+ (0.0127,0) [0|1.6129] "meter"  IPMB,PSCM
 SG_ TrlrAxleToBmpr_L_Actl : 7|9@0+ (0.0254,0) [0|12.9794] "meter"  IPMB,PSCM
 SG_ TrlrAidEnbl_D_Rq : 14|2@0+ (1,0) [0|3] "SED"  IPMB,PSCM

BO_ 1047 TrailerAid_Data2: 8 PSCM
 SG_ TrlrAidMsgTxt_D_Rq : 4|5@0+ (1,0) [0|31] "SED"  IPMB,GWM
 SG_ TrlrAidEnbl_D_Stat : 7|3@0+ (1,0) [0|7] "SED"  IPMB,GWM

BO_ 1105 Image_Processing_Data: 8 IPMB
 SG_ TrlrRvrseMsgTxt_D_Rq : 4|5@0+ (1,0) [0|31] "SED"  GWM
 SG_ TrlrHitchLamp_D_Rq2 : 15|1@0+ (1,0) [0|1] "SED"  GWM
 SG_ CamraFrntStat_D_Stat : 7|2@0+ (1,0) [0|3] "SED"  GWM

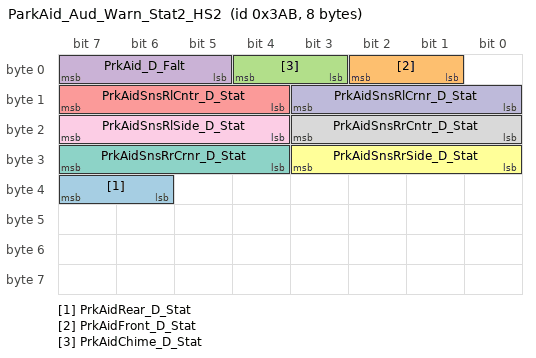
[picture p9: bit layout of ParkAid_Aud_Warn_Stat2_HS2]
BO_ 939 ParkAid_Aud_Warn_Stat2_HS2: 8 GWM
 SG_ PrkAidRear_D_Stat : 39|2@0+ (1,0) [0|3] "SED" Vector__XXX
 SG_ PrkAidFront_D_Stat : 2|2@0+ (1,0) [0|3] "SED" Vector__XXX
 SG_ PrkAidChime_D_Stat : 4|2@0+ (1,0) [0|3] "SED" Vector__XXX
 SG_ PrkAid_D_Falt : 7|3@0+ (1,0) [0|7] "SED"  IPMB
 SG_ PrkAidSnsRlCntr_D_Stat : 15|4@0+ (1,0) [0|15] "SED"  IPMB
 SG_ PrkAidSnsRrSide_D_Stat : 27|4@0+ (1,0) [0|15] "SED"  IPMB
 SG_ PrkAidSnsRrCrnr_D_Stat : 31|4@0+ (1,0) [0|15] "SED"  IPMB
 SG_ PrkAidSnsRrCntr_D_Stat : 19|4@0+ (1,0) [0|15] "SED"  IPMB
 SG_ PrkAidSnsRlSide_D_Stat : 23|4@0+ (1,0) [0|15] "SED"  IPMB
 SG_ PrkAidSnsRlCrnr_D_Stat : 11|4@0+ (1,0) [0|15] "SED"  IPMB

CM_ BU_ ATCM_FFSM "Four-by-Four Switch Module";
CM_ BU_ IPMB "Image Processing Module B";
CM_ BU_ GWM "Gateway Module CGEA1.3(Star Architecture)";
CM_ BU_ ABS_ESC "Anti-lock Brake / Traction Control Module";
CM_ BU_ HUD "Head Up Display (Driver Info.)";
CM_ BU_ IPMA "Lane Departure Warning (Image processing Mod A)";
CM_ BU_ CCM "(Adaptive) Cruise Control Module";
CM_ BU_ PSCM "Power Steering Control Module, Variable Assist Power Steering (VAPS)";
CM_ BU_ SCCM "Steering Column Control Module, SWC Steering Wheel Controller (Stalk Module) ";
CM_ BU_ TBM "Trailer Brake Control Module, TBC (Trailer Brake Control Module)";
CM_ BU_ OCS "Restraints Occupant Classification System Module";
CM_ BU_ TCCM "Transfer Case Control Module, 4x4 Control Module";
CM_ BU_ TSTR "Diagnostic Tester";
CM_ BU_ RCM "Restraints Control Module";
CM_ BO_ 1126 "HS3 APIM Sync Gen3 Tx 0x463.  FrameGateway to 0x466 on HS1, HS2, HS3 and MS1.";
CM_ BO_ 1122 "HS3 APIM Sync Gen3 Tx 0x462.  FrameGateway to 0x465 on HS1, HS2, HS3 and MS1.";
CM_ SG_ 1487 ATCM_GWOnBoardTester "Signal not transmitted on gas, diesel and HEV.  Only supported on PHEV.";
CM_ SG_ 1487 ATCM_GWNMProxy "Signal not transmitted on gas, diesel and HEV.  Only supported on PHEV.";
CM_ SG_ 1487 ATCM_AutoSarNMReserved4 "Signal not transmitted on gas, diesel and HEV.  Only supported on PHEV.";
CM_ SG_ 1487 ATCM_AutoSarNMReserved3 "Signal not transmitted on gas, diesel and HEV.  Only supported on PHEV.";
CM_ SG_ 1487 ATCM_AutoSarNMReserved2 "Signal not transmitted on gas, diesel and HEV.  Only supported on PHEV.";
CM_ SG_ 1487 ATCM_AutoSarNMReserved1 "Signal not transmitted on gas, diesel and HEV.  Only supported on PHEV.";
CM_ SG_ 1487 ATCM_AutoSarNMNodeId "Signal not transmitted on gas, diesel and HEV.  Only supported on PHEV.";
CM_ SG_ 1487 ATCM_AutoSarNMControl "Signal not transmitted on gas, diesel and HEV.  Only supported on PHEV.";
CM_ SG_ 1073 HMI_HMIMode_St "Object ACU System Master.HMIMode
OR
Object NAV System Master.HMIMode

Refer Method HMIAudioMode in the SPSS";
CM_ SG_ 1082 MetricActv_B_Actl "0 =Inactive(English), 1=Active(Metric)";
BA_DEF_ SG_  "U_UP375_MY19_Gas_Rx" ENUM  "No","Yes";
BA_DEF_ SG_  "U_UP375_MY19_Diesel_Rx" ENUM  "No","Yes";
BA_DEF_ SG_  "U_V36X_MY19_Rx" ENUM  "No","Yes";
BA_DEF_ SG_  "U_UP375_MY19_Gas_Tx" ENUM  "No","Yes";
BA_DEF_ SG_  "U_UP375_MY19_Diesel_Tx" ENUM  "No","Yes";
BA_DEF_ SG_  "U_V36X_MY19_Tx" ENUM  "No","Yes";
BA_DEF_ SG_  "U_UP375_MY18_Gas_Rx" ENUM  "No","Yes";
BA_DEF_ SG_  "U_UP375_MY18_Diesel_Rx" ENUM  "No","Yes";
BA_DEF_ SG_  "U_V36X_MY18_5_Gas_Rx" ENUM  "No","Yes";
BA_DEF_ SG_  "U_V36X_MY18_5_Hev_Rx" ENUM  "No","Yes";
BA_DEF_ SG_  "U_UP375_MY18_Gas_Tx" ENUM  "No","Yes";
BA_DEF_ SG_  "U_UP375_MY18_Diesel_Tx" ENUM  "No","Yes";
BA_DEF_ SG_  "U_V36X_MY18_5_Gas_Tx" ENUM  "No","Yes";
BA_DEF_ SG_  "U_V36X_MY18_5_Hev_Tx" ENUM  "No","Yes";
BA_DEF_ SG_  "GenSigTimeoutTime_HCM_HS2" INT 0 100000;
BA_DEF_ SG_  "U_V36X_MY19_5_Diesel_Rx" ENUM  "No","Yes";
BA_DEF_ SG_  "U_V363E_N_MY19_5_20_Gas_Rx" ENUM  "No","Yes";
BA_DEF_ SG_  "U_V363E_N_MY19_5_20_Diesel_Rx" ENUM  "No","Yes";
BA_DEF_ SG_  "U_CD42_MY19_Diesel_Rx" ENUM  "No","Yes";
BA_DEF_ SG_  "U_CD42_MY19_Gas_Rx" ENUM  "No","Yes";
BA_DEF_ SG_  "U_V36X_MY19_5_Diesel_Tx" ENUM  "No","Yes";
BA_DEF_ SG_  "U_V363E_N_MY19_5_20_Gas_Tx" ENUM  "No","Yes";
BA_DEF_ SG_  "U_V363E_N_MY19_5_20_Diesel_Tx" ENUM  "No","Yes";
BA_DEF_ SG_  "U_CD42_MY19_Diesel_Tx" ENUM  "No","Yes";
BA_DEF_ SG_  "U_CD42_MY19_Gas_Tx" ENUM  "No","Yes";
BA_DEF_ BO_  "FrameGatewayNetworkold" ENUM  "None","HS1_CAN","HS2_CAN","HS3_CAN","MS1_CAN";
BA_DEF_ SG_  "U_B562_MY18_Gas_Rx" ENUM  "No","Yes";
BA_DEF_ SG_  "U_C490_MY18_Diesel_Rx" ENUM  "No","Yes";
BA_DEF_ SG_  "U_C490_MY18_Gas_Rx" ENUM  "No","Yes";
BA_DEF_ SG_  "U_V408_MY18_Gas_Rx" ENUM  "No","Yes";
BA_DEF_ SG_  "U_V408_MY18_Diesel_Rx" ENUM  "No","Yes";
BA_DEF_ SG_  "U_V36X_MY18_5_Diesel_Rx" ENUM  "No","Yes";
BA_DEF_ SG_  "U_V408_MY18_Gas_Tx" ENUM  "No","Yes";
BA_DEF_ SG_  "U_V408_MY18_Diesel_Tx" ENUM  "No","Yes";
BA_DEF_ SG_  "U_V36X_MY18_5_Diesel_Tx" ENUM  "No","Yes";
BA_DEF_ SG_  "U_P552_MY18_5_Gas_Tx" ENUM  "No","Yes";
BA_DEF_ SG_  "U_P552_MY18_5_Diesel_Tx" ENUM  "No","Yes";
BA_DEF_ SG_  "U_U502_MY17_Gas_Rx" ENUM  "No","Yes";
BA_DEF_ SG_  "U_S550_MY18_Gas_Rx" ENUM  "No","Yes";
BA_DEF_ SG_  "U_U502_MY17_Gas_Tx" ENUM  "No","Yes";
BA_DEF_ SG_  "U_S550_MY18_Gas_Tx" ENUM  "No","Yes";
BA_DEF_ SG_  "GenSigTimeoutTime_ATCM_FFSM" INT 0 100000;
BA_DEF_ SG_  "GenSigTimeoutTime_ATCM_DMSM" INT 0 100000;
BA_DEF_ SG_  "U_C489_MY17_Gas_Rx" ENUM  "No","Yes";
BA_DEF_ SG_  "U_P552_MY18_Gas_Rx" ENUM  "No","Yes";
BA_DEF_ SG_  "U_U55x_MY18_Gas_Rx" ENUM  "No","Yes";
BA_DEF_ SG_  "U_C489_MY17_Gas_Tx" ENUM  "No","Yes";
BA_DEF_ SG_  "U_P552_MY18_Gas_Tx" ENUM  "No","Yes";
BA_DEF_ SG_  "U_U55x_MY18_Gas_Tx" ENUM  "No","Yes";
BA_DEF_ BO_  "FrameGatewayNetwork" STRING ;
BA_DEF_ SG_  "U_CD43_MY17_Gas_Rx" ENUM  "No","Yes";
BA_DEF_ SG_  "U_P552_MY17_Gas_Rx" ENUM  "No","Yes";
BA_DEF_ SG_  "U_P552_MY17_Diesel_Rx" ENUM  "No","Yes";
BA_DEF_ SG_  "U_B515_MCA_MY17_Diesel_Rx" ENUM  "No","Yes";
BA_DEF_ SG_  "U_B515_MCA_MY17_Gas_Rx" ENUM  "No","Yes";
BA_DEF_ SG_  "U_CD43_MY17_Gas_Tx" ENUM  "No","Yes";
BA_DEF_ SG_  "U_P552_MY17_Gas_Tx" ENUM  "No","Yes";
BA_DEF_ SG_  "U_P552_MY17_Diesel_Tx" ENUM  "No","Yes";
BA_DEF_ SG_  "U_B515_MCA_MY17_Diesel_Tx" ENUM  "No","Yes";
BA_DEF_ SG_  "U_B515_MCA_MY17_Gas_Tx" ENUM  "No","Yes";
BA_DEF_ SG_  "U_B562LC_MY15_Diesel_Rx" ENUM  "No","Yes";
BA_DEF_ SG_  "U_B562LC_MY15_Gas_Rx" ENUM  "No","Yes";
BA_DEF_ SG_  "U_B479_MY17_Gas_Rx" ENUM  "No","Yes";
BA_DEF_ SG_  "U_B479_MY17_Diesel_Rx" ENUM  "No","Yes";
BA_DEF_ SG_  "U_CD4_MY17_Diesel_Rx" ENUM  "No","Yes";
BA_DEF_ SG_  "U_CD4_MY17_Gas_Rx" ENUM  "No","Yes";
BA_DEF_ SG_  "U_CD4_MY17_Hev_Rx" ENUM  "No","Yes";
BA_DEF_ SG_  "U_CD4_MY17_Phev_Rx" ENUM  "No","Yes";
BA_DEF_ SG_  "U_CD42_MY16_Diesel_Rx" ENUM  "No","Yes";
BA_DEF_ SG_  "U_CD42_MY16_Gas_Rx" ENUM  "No","Yes";
BA_DEF_ SG_  "U_B562LC_MY15_Diesel_Tx" ENUM  "No","Yes";
BA_DEF_ SG_  "U_B562LC_MY15_Gas_Tx" ENUM  "No","Yes";
BA_DEF_ SG_  "U_CD4_MY17_Diesel_Tx" ENUM  "No","Yes";
BA_DEF_ SG_  "U_CD4_MY17_Gas_Tx" ENUM  "No","Yes";
BA_DEF_ SG_  "U_CD4_MY17_Hev_Tx" ENUM  "No","Yes";
BA_DEF_ SG_  "U_CD4_MY17_Phev_Tx" ENUM  "No","Yes";
BA_DEF_ SG_  "U_CD42_MY16_Diesel_Tx" ENUM  "No","Yes";
BA_DEF_ SG_  "U_CD42_MY16_Gas_Tx" ENUM  "No","Yes";
BA_DEF_ SG_  "GenSigTimeoutTime_SECM" INT 0 100000;
BA_DEF_ BO_  "MessageGateway" ENUM  "No","Yes";
BA_DEF_ SG_  "U_CD42_MY15_Diesel_Rx" ENUM  "No","Yes";
BA_DEF_ SG_  "U_CD42_MY15_Gas_Rx" ENUM  "No","Yes";
BA_DEF_ SG_  "U_U502_MY16_Gas_Rx" ENUM  "No","Yes";
BA_DEF_ SG_  "U_P558_MY17_Gas_Rx" ENUM  "No","Yes";
BA_DEF_ SG_  "U_P558_MY17_Diesel_Rx" ENUM  "No","Yes";
BA_DEF_ SG_  "U_V36X_MY16_5_Diesel_Rx" ENUM  "No","Yes";
BA_DEF_ SG_  "U_CD42_MY15_Diesel_Tx" ENUM  "No","Yes";
BA_DEF_ SG_  "U_CD42_MY15_Gas_Tx" ENUM  "No","Yes";
BA_DEF_ SG_  "U_U502_MY16_Gas_Tx" ENUM  "No","Yes";
BA_DEF_ SG_  "U_P558_MY17_Gas_Tx" ENUM  "No","Yes";
BA_DEF_ SG_  "U_P558_MY17_Diesel_Tx" ENUM  "No","Yes";
BA_DEF_ SG_  "U_V36X_MY16_5_Diesel_Tx" ENUM  "No","Yes";
BA_DEF_ SG_  "GenSigTimeoutTime_VDM" INT 0 100000;
BA_DEF_ SG_  "GenSigTimeoutTime_ATCM" INT 0 100000;
BA_DEF_ SG_  "GenSigTimeoutTime_GENERIC" INT 0 100000;
BA_DEF_ SG_  "GenSigTimeoutTime_TRCM" INT 0 100000;
BA_DEF_ SG_  "GenSigTimeoutTime_GSM" INT 0 100000;
BA_DEF_ SG_  "GenSigTimeoutTime_FDSM" INT 0 100000;
BA_DEF_ SG_  "GenSigTimeoutTime_PCU" INT 0 100000;
BA_DEF_ SG_  "GenSigTimeoutTime_SASM" INT 0 100000;
BA_DEF_ SG_  "GenSigTimeoutTime_TCU_TBS" INT 0 100000;
BA_DEF_ SG_  "Gateway_ID" INT 0 0;
BA_DEF_ SG_  "GenSigTimeoutTime_IPMB" INT 0 100000;
BA_DEF_ SG_  "GenSigTimeoutTime__delete" INT 0 100000;
BA_DEF_ SG_  "GenSigTimeoutTime_PBM" INT 0 100000;
BA_DEF_ SG_  "GenSigTimeoutTime_TCCM" INT 0 100000;
BA_DEF_ SG_  "GenSigTimeoutTime_HUD" INT 0 100000;
BA_DEF_ SG_  "GenSigTimeoutTime_PSCM" INT 0 100000;
BA_DEF_ SG_  "GenSigTimeoutTime_SCCM" INT 0 100000;
BA_DEF_ SG_  "GenSigTimeoutTime_TBM" INT 0 100000;
BA_DEF_ SG_  "GenSigTimeoutTime_TSTR" INT 0 100000;
BA_DEF_ SG_  "GenSigTimeoutTime_IPMA" INT 0 100000;
BA_DEF_ SG_  "GenSigTimeoutTime_CCM" INT 0 100000;
BA_DEF_ SG_  "GenSigTimeoutTime_ABS_ESC" INT 0 100000;
BA_DEF_ SG_  "GenSigTimeoutTime_OCS" INT 0 100000;
BA_DEF_ SG_  "GenSigTimeoutTime_GWM" INT 0 100000;
BA_DEF_ SG_  "GenSigTimeoutTime_RCM" INT 0 100000;
BA_DEF_  "BusType" STRING ;
BA_DEF_ BO_  "FrameGatewayMS1" HEX 0 1407;
BA_DEF_ BO_  "FrameGatewayHS3" HEX 0 1407;
BA_DEF_ BO_  "FrameGatewayHS1" HEX 0 1407;
BA_DEF_ BO_  "NetworkInitialization" ENUM  "No","Yes";
BA_DEF_ BO_  "FrameGatewayId" HEX 0 1407;
BA_DEF_ BO_  "EventRateOfChange" INT 10 10000;
BA_DEF_ BO_  "GenMsgStartDelayTime" INT 0 10000;
BA_DEF_ BO_  "GenMsgNrOfRepetition" INT 0 100;
BA_DEF_ BO_  "GenMsgDelayTime" INT 0 1000;
BA_DEF_ BO_  "GenMsgCycleTime" INT 0 100000;
BA_DEF_ BO_  "GenMsgSendType" ENUM  "FixedPeriodic","Event","EnabledPeriodic","NotUsed","NotUsed","EventPeriodic","NotUsed","NotUsed","NoMsgSendType";
BA_DEF_ SG_  "U_CD4_MY14_Phev_Tx" ENUM  "No","Yes";
BA_DEF_ SG_  "U_CD4_MY14_Hev_Tx" ENUM  "No","Yes";
BA_DEF_ SG_  "U_CD4_MY14_Gas_Tx" ENUM  "No","Yes";
BA_DEF_ SG_  "U_CD4_MY14_Diesel_Tx" ENUM  "No","Yes";
BA_DEF_ SG_  "U_CD43_MY16_Gas_Tx" ENUM  "No","Yes";
BA_DEF_ SG_  "U_C490LC_MY15_Gas_Tx" ENUM  "No","Yes";
BA_DEF_ SG_  "U_UP375_MY15_Diesel_Tx" ENUM  "No","Yes";
BA_DEF_ SG_  "U_UP375_MY15_Gas_Tx" ENUM  "No","Yes";
BA_DEF_ SG_  "U_U502_MY15_Gas_Tx" ENUM  "No","Yes";
BA_DEF_ SG_  "U_B562LC_MY14_Gas_Tx" ENUM  "No","Yes";
BA_DEF_ SG_  "U_B562LC_MY14_Diesel_Tx" ENUM  "No","Yes";
BA_DEF_ SG_  "U_C489_MY14_Gas_Tx" ENUM  "No","Yes";
BA_DEF_ SG_  "U_S550_MY15_Gas_Tx" ENUM  "No","Yes";
BA_DEF_ SG_  "U_P552_MY15_Gas_Tx" ENUM  "No","Yes";
BA_DEF_ SG_  "U_CD42_MY14_Gas_Tx" ENUM  "No","Yes";
BA_DEF_ SG_  "U_CD42_MY14_Diesel_Tx" ENUM  "No","Yes";
BA_DEF_ SG_  "U_CD4_MY13_Phev_Tx" ENUM  "No","Yes";
BA_DEF_ SG_  "U_CD4_MY13_Hev_Tx" ENUM  "No","Yes";
BA_DEF_ SG_  "U_CD4_MY13_Gas_Tx" ENUM  "No","Yes";
BA_DEF_ SG_  "U_CD4_MY13_Diesel_Tx" ENUM  "No","Yes";
BA_DEF_ SG_  "U_CD4_MY14_Phev_Rx" ENUM  "No","Yes";
BA_DEF_ SG_  "U_CD4_MY14_Hev_Rx" ENUM  "No","Yes";
BA_DEF_ SG_  "U_CD4_MY14_Gas_Rx" ENUM  "No","Yes";
BA_DEF_ SG_  "U_CD4_MY14_Diesel_Rx" ENUM  "No","Yes";
BA_DEF_ SG_  "U_CD43_MY16_Gas_Rx" ENUM  "No","Yes";
BA_DEF_ SG_  "U_UP375_MY15_Diesel_Rx" ENUM  "No","Yes";
BA_DEF_ SG_  "U_UP375_MY15_Gas_Rx" ENUM  "No","Yes";
BA_DEF_ SG_  "U_B479_MY15_Gas_Rx" ENUM  "No","Yes";
BA_DEF_ SG_  "U_U502_MY15_Gas_Rx" ENUM  "No","Yes";
BA_DEF_ SG_  "U_B562LC_MY14_Gas_Rx" ENUM  "No","Yes";
BA_DEF_ SG_  "U_B562LC_MY14_Diesel_Rx" ENUM  "No","Yes";
BA_DEF_ SG_  "U_C489_MY14_Gas_Rx" ENUM  "No","Yes";
BA_DEF_ SG_  "U_S550_MY15_Gas_Rx" ENUM  "No","Yes";
BA_DEF_ SG_  "U_P552_MY15_Gas_Rx" ENUM  "No","Yes";
BA_DEF_ SG_  "U_CD42_MY14_Gas_Rx" ENUM  "No","Yes";
BA_DEF_ SG_  "U_CD42_MY14_Diesel_Rx" ENUM  "No","Yes";
BA_DEF_ SG_  "U_CD4_MY13_Phev_Rx" ENUM  "No","Yes";
BA_DEF_ SG_  "U_CD4_MY13_Hev_Rx" ENUM  "No","Yes";
BA_DEF_ SG_  "U_CD4_MY13_Gas_Rx" ENUM  "No","Yes";
BA_DEF_ SG_  "U_CD4_MY13_Diesel_Rx" ENUM  "No","Yes";
BA_DEF_ SG_  "ContentDependant" ENUM  "No","Yes";
BA_DEF_ SG_  "GenSigStartValue" INT 0 1000000000;
BA_DEF_ SG_  "UsedOnPgmDBC" ENUM  "No","Yes";
BA_DEF_ SG_  "CrossOver_LIN" ENUM  "No","Yes";
BA_DEF_ SG_  "CrossOver_InfoCAN" ENUM  "No","Yes";
BA_DEF_ SG_  "WakeupSignal" ENUM  "No","Yes";
BA_DEF_ SG_  "FMC_SIG_SSPEC" STRING ;
BA_DEF_ SG_  "GenSigMissingSourceValue" INT 0 1000000000;
BA_DEF_ SG_  "GenSigSendType" ENUM  "Cyclic","OnWrite","vector_leerstring","OnChange","vector_leerstring","IfActive","vector_leerstring","NoSigSendType";
BA_DEF_ BO_  "NmAsrMessage" ENUM  "No","Yes";
BA_DEF_ BO_  "TpApplType" STRING ;
BA_DEF_ BO_  "DiagState" ENUM  "No","Yes";
BA_DEF_ BO_  "DiagRequest" ENUM  "No","Yes";
BA_DEF_ BO_  "DiagResponse" ENUM  "No","Yes";
BA_DEF_ BO_  "GenMsgILSupport" ENUM  "No","Yes";
BA_DEF_ BU_  "Terminator" ENUM  "No","Yes";
BA_DEF_ BU_  "NodeWakeUpTime" INT 0 1000;
BA_DEF_ BU_  "NodeStartUpTime" INT 0 1000;
BA_DEF_ BU_  "NmAsrNodeIdentifier" HEX 128 255;
BA_DEF_ BU_  "NmAsrNode" ENUM  "No","Yes";
BA_DEF_ BU_  "PowerType" ENUM  "Switched","Latched","Sleep","vector_leerstring","vector_leerstring";
BA_DEF_ BU_  "DiagNode" ENUM  "GGDS","GDS","NONE";
BA_DEF_ BU_  "EOL_SB_Flash" ENUM  "GGDS","GDS","NONE","vector_leerstring";
BA_DEF_ BU_  "NetworkInitializationUsed" ENUM  "No","Yes";
BA_DEF_ BU_  "NmNode" ENUM  "No","Yes";
BA_DEF_ BU_  "NmStationAddress" INT 0 255;
BA_DEF_ BU_  "ILUsed" ENUM  "No","Yes";
BA_DEF_ BU_  "NosPackage" ENUM  "None","I3_1","I3_2","1.0.1","RP","EuCD","Volcano";
BA_DEF_ BU_  "PackageID" STRING ;
BA_DEF_ BU_  "GatewayECU" ENUM  "No","Yes";
BA_DEF_  "StarNetworkGwType" ENUM  "0=NotDefined","1=HS1","2=HS2","3=HS3","4=HS4","5=HS5","6=MS1";
BA_DEF_  "CMDB_Version" STRING ;
BA_DEF_  "NmType" STRING ;
BA_DEF_  "NetworkSpeed" ENUM  "500kBits/s","125kBit/s";
BA_DEF_  "NmAsrMessageCount" INT 128 128;
BA_DEF_  "NmAsrBaseAddress" HEX 1408 1408;
BA_DEF_  "DBName" STRING ;
BA_DEF_  "VersionDay" INT 1 31;
BA_DEF_  "Manufacturer" STRING ;
BA_DEF_  "VersionNumber" INT 0 10000;
BA_DEF_  "VersionMonth" INT 1 12;
BA_DEF_  "VersionYear" INT 2000 3000;
BA_DEF_  "NmBaseAddress" HEX 1280 1280;
BA_DEF_  "NmMessageCount" INT 0 128;
BA_DEF_DEF_  "U_UP375_MY19_Gas_Rx" "No";
BA_DEF_DEF_  "U_UP375_MY19_Diesel_Rx" "No";
BA_DEF_DEF_  "U_V36X_MY19_Rx" "No";
BA_DEF_DEF_  "U_UP375_MY19_Gas_Tx" "No";
BA_DEF_DEF_  "U_UP375_MY19_Diesel_Tx" "No";
BA_DEF_DEF_  "U_V36X_MY19_Tx" "No";
BA_DEF_DEF_  "U_UP375_MY18_Gas_Rx" "No";
BA_DEF_DEF_  "U_UP375_MY18_Diesel_Rx" "No";
BA_DEF_DEF_  "U_V36X_MY18_5_Gas_Rx" "No";
BA_DEF_DEF_  "U_V36X_MY18_5_Hev_Rx" "No";
BA_DEF_DEF_  "U_UP375_MY18_Gas_Tx" "No";
BA_DEF_DEF_  "U_UP375_MY18_Diesel_Tx" "No";
BA_DEF_DEF_  "U_V36X_MY18_5_Gas_Tx" "No";
BA_DEF_DEF_  "U_V36X_MY18_5_Hev_Tx" "No";
BA_DEF_DEF_  "GenSigTimeoutTime_HCM_HS2" 5000;
BA_DEF_DEF_  "U_V36X_MY19_5_Diesel_Rx" "No";
BA_DEF_DEF_  "U_V363E_N_MY19_5_20_Gas_Rx" "No";
BA_DEF_DEF_  "U_V363E_N_MY19_5_20_Diesel_Rx" "No";
BA_DEF_DEF_  "U_CD42_MY19_Diesel_Rx" "No";
BA_DEF_DEF_  "U_CD42_MY19_Gas_Rx" "No";
BA_DEF_DEF_  "U_V36X_MY19_5_Diesel_Tx" "No";
BA_DEF_DEF_  "U_V363E_N_MY19_5_20_Gas_Tx" "No";
BA_DEF_DEF_  "U_V363E_N_MY19_5_20_Diesel_Tx" "No";
BA_DEF_DEF_  "U_CD42_MY19_Diesel_Tx" "No";
BA_DEF_DEF_  "U_CD42_MY19_Gas_Tx" "No";
BA_DEF_DEF_  "FrameGatewayNetworkold" "None";
BA_DEF_DEF_  "U_B562_MY18_Gas_Rx" "No";
BA_DEF_DEF_  "U_C490_MY18_Diesel_Rx" "No";
BA_DEF_DEF_  "U_C490_MY18_Gas_Rx" "No";
BA_DEF_DEF_  "U_V408_MY18_Gas_Rx" "No";
BA_DEF_DEF_  "U_V408_MY18_Diesel_Rx" "No";
BA_DEF_DEF_  "U_V36X_MY18_5_Diesel_Rx" "No";
BA_DEF_DEF_  "U_V408_MY18_Gas_Tx" "No";
BA_DEF_DEF_  "U_V408_MY18_Diesel_Tx" "No";
BA_DEF_DEF_  "U_V36X_MY18_5_Diesel_Tx" "No";
BA_DEF_DEF_  "U_P552_MY18_5_Gas_Tx" "No";
BA_DEF_DEF_  "U_P552_MY18_5_Diesel_Tx" "No";
BA_DEF_DEF_  "U_U502_MY17_Gas_Rx" "No";
BA_DEF_DEF_  "U_S550_MY18_Gas_Rx" "No";
BA_DEF_DEF_  "U_U502_MY17_Gas_Tx" "No";
BA_DEF_DEF_  "U_S550_MY18_Gas_Tx" "No";
BA_DEF_DEF_  "GenSigTimeoutTime_ATCM_FFSM" 5000;
BA_DEF_DEF_  "GenSigTimeoutTime_ATCM_DMSM" 5000;
BA_DEF_DEF_  "U_C489_MY17_Gas_Rx" "No";
BA_DEF_DEF_  "U_P552_MY18_Gas_Rx" "No";
BA_DEF_DEF_  "U_U55x_MY18_Gas_Rx" "No";
BA_DEF_DEF_  "U_C489_MY17_Gas_Tx" "No";
BA_DEF_DEF_  "U_P552_MY18_Gas_Tx" "No";
BA_DEF_DEF_  "U_U55x_MY18_Gas_Tx" "No";
BA_DEF_DEF_  "FrameGatewayNetwork" "NONE";
BA_DEF_DEF_  "U_CD43_MY17_Gas_Rx" "No";
BA_DEF_DEF_  "U_P552_MY17_Gas_Rx" "No";
BA_DEF_DEF_  "U_P552_MY17_Diesel_Rx" "No";
BA_DEF_DEF_  "U_B515_MCA_MY17_Diesel_Rx" "No";
BA_DEF_DEF_  "U_B515_MCA_MY17_Gas_Rx" "No";
BA_DEF_DEF_  "U_CD43_MY17_Gas_Tx" "No";
BA_DEF_DEF_  "U_P552_MY17_Gas_Tx" "No";
BA_DEF_DEF_  "U_P552_MY17_Diesel_Tx" "No";
BA_DEF_DEF_  "U_B515_MCA_MY17_Diesel_Tx" "No";
BA_DEF_DEF_  "U_B515_MCA_MY17_Gas_Tx" "No";
BA_DEF_DEF_  "U_B562LC_MY15_Diesel_Rx" "No";
BA_DEF_DEF_  "U_B562LC_MY15_Gas_Rx" "No";
BA_DEF_DEF_  "U_B479_MY17_Gas_Rx" "No";
BA_DEF_DEF_  "U_B479_MY17_Diesel_Rx" "No";
BA_DEF_DEF_  "U_CD4_MY17_Diesel_Rx" "No";
BA_DEF_DEF_  "U_CD4_MY17_Gas_Rx" "No";
BA_DEF_DEF_  "U_CD4_MY17_Hev_Rx" "No";
BA_DEF_DEF_  "U_CD4_MY17_Phev_Rx" "No";
BA_DEF_DEF_  "U_CD42_MY16_Diesel_Rx" "No";
BA_DEF_DEF_  "U_CD42_MY16_Gas_Rx" "No";
BA_DEF_DEF_  "U_B562LC_MY15_Diesel_Tx" "No";
BA_DEF_DEF_  "U_B562LC_MY15_Gas_Tx" "No";
BA_DEF_DEF_  "U_CD4_MY17_Diesel_Tx" "No";
BA_DEF_DEF_  "U_CD4_MY17_Gas_Tx" "No";
BA_DEF_DEF_  "U_CD4_MY17_Hev_Tx" "No";
BA_DEF_DEF_  "U_CD4_MY17_Phev_Tx" "No";
BA_DEF_DEF_  "U_CD42_MY16_Diesel_Tx" "No";
BA_DEF_DEF_  "U_CD42_MY16_Gas_Tx" "No";
BA_DEF_DEF_  "GenSigTimeoutTime_SECM" 5000;
BA_DEF_DEF_  "MessageGateway" "No";
BA_DEF_DEF_  "U_CD42_MY15_Diesel_Rx" "No";
BA_DEF_DEF_  "U_CD42_MY15_Gas_Rx" "No";
BA_DEF_DEF_  "U_U502_MY16_Gas_Rx" "No";
BA_DEF_DEF_  "U_P558_MY17_Gas_Rx" "No";
BA_DEF_DEF_  "U_P558_MY17_Diesel_Rx" "No";
BA_DEF_DEF_  "U_V36X_MY16_5_Diesel_Rx" "No";
BA_DEF_DEF_  "U_CD42_MY15_Diesel_Tx" "No";
BA_DEF_DEF_  "U_CD42_MY15_Gas_Tx" "No";
BA_DEF_DEF_  "U_U502_MY16_Gas_Tx" "No";
BA_DEF_DEF_  "U_P558_MY17_Gas_Tx" "No";
BA_DEF_DEF_  "U_P558_MY17_Diesel_Tx" "No";
BA_DEF_DEF_  "U_V36X_MY16_5_Diesel_Tx" "No";
BA_DEF_DEF_  "GenSigTimeoutTime_VDM" 5000;
BA_DEF_DEF_  "GenSigTimeoutTime_ATCM" 5000;
BA_DEF_DEF_  "GenSigTimeoutTime_GENERIC" 5000;
BA_DEF_DEF_  "GenSigTimeoutTime_TRCM" 5000;
BA_DEF_DEF_  "GenSigTimeoutTime_GSM" 5000;
BA_DEF_DEF_  "GenSigTimeoutTime_FDSM" 5000;
BA_DEF_DEF_  "GenSigTimeoutTime_PCU" 5000;
BA_DEF_DEF_  "GenSigTimeoutTime_SASM" 5000;
BA_DEF_DEF_  "GenSigTimeoutTime_TCU_TBS" 5000;
BA_DEF_DEF_  "Gateway_ID" 0;
BA_DEF_DEF_  "GenSigTimeoutTime_IPMB" 5000;
BA_DEF_DEF_  "GenSigTimeoutTime__delete" 5000;
BA_DEF_DEF_  "GenSigTimeoutTime_PBM" 5000;
BA_DEF_DEF_  "GenSigTimeoutTime_TCCM" 5000;
BA_DEF_DEF_  "GenSigTimeoutTime_HUD" 5000;
BA_DEF_DEF_  "GenSigTimeoutTime_PSCM" 5000;
BA_DEF_DEF_  "GenSigTimeoutTime_SCCM" 5000;
BA_DEF_DEF_  "GenSigTimeoutTime_TBM" 5000;
BA_DEF_DEF_  "GenSigTimeoutTime_TSTR" 5000;
BA_DEF_DEF_  "GenSigTimeoutTime_IPMA" 5000;
BA_DEF_DEF_  "GenSigTimeoutTime_CCM" 5000;
BA_DEF_DEF_  "GenSigTimeoutTime_ABS_ESC" 5000;
BA_DEF_DEF_  "GenSigTimeoutTime_OCS" 5000;
BA_DEF_DEF_  "GenSigTimeoutTime_GWM" 5000;
BA_DEF_DEF_  "GenSigTimeoutTime_RCM" 5000;
BA_DEF_DEF_  "BusType" "";
BA_DEF_DEF_  "FrameGatewayMS1" 0;
BA_DEF_DEF_  "FrameGatewayHS3" 0;
BA_DEF_DEF_  "FrameGatewayHS1" 0;
BA_DEF_DEF_  "NetworkInitialization" "No";
BA_DEF_DEF_  "FrameGatewayId" 0;
BA_DEF_DEF_  "EventRateOfChange" 10000;
BA_DEF_DEF_  "GenMsgStartDelayTime" 0;
BA_DEF_DEF_  "GenMsgNrOfRepetition" 1;
BA_DEF_DEF_  "GenMsgDelayTime" 20;
BA_DEF_DEF_  "GenMsgCycleTime" 0;
BA_DEF_DEF_  "GenMsgSendType" "NoMsgSendType";
BA_DEF_DEF_  "U_CD4_MY14_Phev_Tx" "No";
BA_DEF_DEF_  "U_CD4_MY14_Hev_Tx" "No";
BA_DEF_DEF_  "U_CD4_MY14_Gas_Tx" "No";
BA_DEF_DEF_  "U_CD4_MY14_Diesel_Tx" "No";
BA_DEF_DEF_  "U_CD43_MY16_Gas_Tx" "No";
BA_DEF_DEF_  "U_C490LC_MY15_Gas_Tx" "No";
BA_DEF_DEF_  "U_UP375_MY15_Diesel_Tx" "No";
BA_DEF_DEF_  "U_UP375_MY15_Gas_Tx" "No";
BA_DEF_DEF_  "U_U502_MY15_Gas_Tx" "No";
BA_DEF_DEF_  "U_B562LC_MY14_Gas_Tx" "No";
BA_DEF_DEF_  "U_B562LC_MY14_Diesel_Tx" "No";
BA_DEF_DEF_  "U_C489_MY14_Gas_Tx" "No";
BA_DEF_DEF_  "U_S550_MY15_Gas_Tx" "No";
BA_DEF_DEF_  "U_P552_MY15_Gas_Tx" "No";
BA_DEF_DEF_  "U_CD42_MY14_Gas_Tx" "No";
BA_DEF_DEF_  "U_CD42_MY14_Diesel_Tx" "No";
BA_DEF_DEF_  "U_CD4_MY13_Phev_Tx" "No";
BA_DEF_DEF_  "U_CD4_MY13_Hev_Tx" "No";
BA_DEF_DEF_  "U_CD4_MY13_Gas_Tx" "No";
BA_DEF_DEF_  "U_CD4_MY13_Diesel_Tx" "No";
BA_DEF_DEF_  "U_CD4_MY14_Phev_Rx" "No";
BA_DEF_DEF_  "U_CD4_MY14_Hev_Rx" "No";
BA_DEF_DEF_  "U_CD4_MY14_Gas_Rx" "No";
BA_DEF_DEF_  "U_CD4_MY14_Diesel_Rx" "No";
BA_DEF_DEF_  "U_CD43_MY16_Gas_Rx" "No";
BA_DEF_DEF_  "U_UP375_MY15_Diesel_Rx" "No";
BA_DEF_DEF_  "U_UP375_MY15_Gas_Rx" "No";
BA_DEF_DEF_  "U_B479_MY15_Gas_Rx" "No";
BA_DEF_DEF_  "U_U502_MY15_Gas_Rx" "No";
BA_DEF_DEF_  "U_B562LC_MY14_Gas_Rx" "No";
BA_DEF_DEF_  "U_B562LC_MY14_Diesel_Rx" "No";
BA_DEF_DEF_  "U_C489_MY14_Gas_Rx" "No";
BA_DEF_DEF_  "U_S550_MY15_Gas_Rx" "No";
BA_DEF_DEF_  "U_P552_MY15_Gas_Rx" "No";
BA_DEF_DEF_  "U_CD42_MY14_Gas_Rx" "No";
BA_DEF_DEF_  "U_CD42_MY14_Diesel_Rx" "No";
BA_DEF_DEF_  "U_CD4_MY13_Phev_Rx" "No";
BA_DEF_DEF_  "U_CD4_MY13_Hev_Rx" "No";
BA_DEF_DEF_  "U_CD4_MY13_Gas_Rx" "No";
BA_DEF_DEF_  "U_CD4_MY13_Diesel_Rx" "No";
BA_DEF_DEF_  "ContentDependant" "No";
BA_DEF_DEF_  "GenSigStartValue" 0;
BA_DEF_DEF_  "UsedOnPgmDBC" "Yes";
BA_DEF_DEF_  "CrossOver_LIN" "No";
BA_DEF_DEF_  "CrossOver_InfoCAN" "No";
BA_DEF_DEF_  "WakeupSignal" "No";
BA_DEF_DEF_  "FMC_SIG_SSPEC" "Unknown";
BA_DEF_DEF_  "GenSigMissingSourceValue" 0;
BA_DEF_DEF_  "GenSigSendType" "NoSigSendType";
BA_DEF_DEF_  "NmAsrMessage" "No";
BA_DEF_DEF_  "TpApplType" "";
BA_DEF_DEF_  "DiagState" "No";
BA_DEF_DEF_  "DiagRequest" "No";
BA_DEF_DEF_  "DiagResponse" "No";
BA_DEF_DEF_  "GenMsgILSupport" "Yes";
BA_DEF_DEF_  "Terminator" "No";
BA_DEF_DEF_  "NodeWakeUpTime" 10;
BA_DEF_DEF_  "NodeStartUpTime" 250;
BA_DEF_DEF_  "NmAsrNodeIdentifier" 128;
BA_DEF_DEF_  "NmAsrNode" "No";
BA_DEF_DEF_  "PowerType" "Switched";
BA_DEF_DEF_  "DiagNode" "GGDS";
BA_DEF_DEF_  "EOL_SB_Flash" "GGDS";
BA_DEF_DEF_  "NetworkInitializationUsed" "No";
BA_DEF_DEF_  "NmNode" "No";
BA_DEF_DEF_  "NmStationAddress" 0;
BA_DEF_DEF_  "ILUsed" "Yes";
BA_DEF_DEF_  "NosPackage" "I3_1";
BA_DEF_DEF_  "PackageID" "08.05.00.00.71.xx.xx.rr.00.00";
BA_DEF_DEF_  "GatewayECU" "No";
BA_DEF_DEF_  "StarNetworkGwType" "0=NotDefined";
BA_DEF_DEF_  "CMDB_Version" "v11.01";
BA_DEF_DEF_  "NmType" "Ford-OSEK";
BA_DEF_DEF_  "NetworkSpeed" "500kBits/s";
BA_DEF_DEF_  "NmAsrMessageCount" 128;
BA_DEF_DEF_  "NmAsrBaseAddress" 1408;
BA_DEF_DEF_  "DBName" "";
BA_DEF_DEF_  "VersionDay" 1;
BA_DEF_DEF_  "Manufacturer" "Ford";
BA_DEF_DEF_  "VersionNumber" 1;
BA_DEF_DEF_  "VersionMonth" 1;
BA_DEF_DEF_  "VersionYear" 2011;
BA_DEF_DEF_  "NmBaseAddress" 1280;
BA_DEF_DEF_  "NmMessageCount" 128;
BA_ "BusType" "CAN";
BA_ "VersionYear" 2018;
BA_ "VersionMonth" 3;
BA_ "CMDB_Version" "v13.09";
BA_ "StarNetworkGwType" 2;
BA_ "VersionNumber" 9;
BA_ "VersionDay" 20;
BA_ "DBName" "HS2_CAN";
BA_ "NmStationAddress" BU_ ATCM_FFSM 79;
BA_ "NmAsrNode" BU_ ATCM_FFSM 1;
BA_ "NmAsrNodeIdentifier" BU_ ATCM_FFSM 207;
BA_ "PowerType" BU_ ATCM_FFSM 2;
BA_ "NmStationAddress" BU_ IPMB 104;
BA_ "NmStationAddress" BU_ Generic_BCM 1;
BA_ "PowerType" BU_ Generic_BCM 2;
BA_ "NmAsrNode" BU_ Generic_BCM 1;
BA_ "NmAsrNodeIdentifier" BU_ Generic_BCM 129;
BA_ "NodeStartUpTime" BU_ Generic_BCM 1000;
BA_ "NmStationAddress" BU_ GWM 30;
BA_ "PowerType" BU_ GWM 2;
BA_ "NmAsrNode" BU_ GWM 1;
BA_ "NmAsrNodeIdentifier" BU_ GWM 158;
BA_ "NodeStartUpTime" BU_ GWM 100;
BA_ "Terminator" BU_ GWM 1;
BA_ "GatewayECU" BU_ GWM 1;
BA_ "NosPackage" BU_ GWM 4;
BA_ "NmStationAddress" BU_ ABS_ESC 22;
BA_ "PowerType" BU_ ABS_ESC 2;
BA_ "NmAsrNode" BU_ ABS_ESC 1;
BA_ "NmAsrNodeIdentifier" BU_ ABS_ESC 150;
BA_ "NodeStartUpTime" BU_ ABS_ESC 1000;
BA_ "NodeWakeUpTime" BU_ ABS_ESC 300;
BA_ "NmStationAddress" BU_ HUD 27;
BA_ "NmStationAddress" BU_ IPMA 28;
BA_ "NetworkInitializationUsed" BU_ IPMA 1;
BA_ "NmStationAddress" BU_ CCM 67;
BA_ "NmAsrNodeIdentifier" BU_ PSCM 181;
BA_ "NmStationAddress" BU_ PSCM 53;
BA_ "PowerType" BU_ PSCM 1;
BA_ "NmStationAddress" BU_ SCCM 51;
BA_ "PowerType" BU_ SCCM 2;
BA_ "NmAsrNode" BU_ SCCM 1;
BA_ "NmAsrNodeIdentifier" BU_ SCCM 179;
BA_ "NodeStartUpTime" BU_ SCCM 1000;
BA_ "NodeWakeUpTime" BU_ SCCM 100;
BA_ "Terminator" BU_ SCCM 1;
BA_ "NosPackage" BU_ SCCM 4;
BA_ "NodeWakeUpTime" BU_ TBM 50;
BA_ "NmStationAddress" BU_ TBM 64;
BA_ "PowerType" BU_ TBM 2;
BA_ "NmAsrNode" BU_ TBM 1;
BA_ "NmAsrNodeIdentifier" BU_ TBM 192;
BA_ "NodeStartUpTime" BU_ TBM 1000;
BA_ "NmStationAddress" BU_ OCS 68;
BA_ "NodeWakeUpTime" BU_ TCCM 25;
BA_ "NmStationAddress" BU_ TCCM 33;
BA_ "PowerType" BU_ TCCM 2;
BA_ "NmAsrNode" BU_ TCCM 1;
BA_ "NmAsrNodeIdentifier" BU_ TCCM 161;
BA_ "NodeStartUpTime" BU_ TCCM 1000;
BA_ "NmStationAddress" BU_ RCM 23;
BA_ "GenMsgCycleTime" BO_ 1100 1000;
BA_ "GenMsgSendType" BO_ 1100 5;
BA_ "NetworkInitialization" BO_ 1100 1;
BA_ "FrameGatewayId" BO_ 370 370;
BA_ "FrameGatewayHS1" BO_ 370 370;
BA_ "FrameGatewayNetwork" BO_ 370 "HS1_CAN";
BA_ "FrameGatewayHS3" BO_ 1126 1123;
BA_ "FrameGatewayMS1" BO_ 1126 1126;
BA_ "FrameGatewayId" BO_ 1215 559;
BA_ "FrameGatewayHS3" BO_ 1215 559;
BA_ "FrameGatewayNetwork" BO_ 1215 "HS3_CAN";
BA_ "FrameGatewayId" BO_ 1214 558;
BA_ "FrameGatewayHS3" BO_ 1214 558;
BA_ "FrameGatewayNetwork" BO_ 1214 "HS3_CAN";
BA_ "GenMsgSendType" BO_ 980 0;
BA_ "GenMsgCycleTime" BO_ 980 30;
BA_ "GenMsgCycleTime" BO_ 973 1000;
BA_ "GenMsgSendType" BO_ 973 5;
BA_ "NetworkInitialization" BO_ 973 1;
BA_ "GenMsgCycleTime" BO_ 979 50;
BA_ "GenMsgSendType" BO_ 979 0;
BA_ "GenMsgCycleTime" BO_ 985 1000;
BA_ "GenMsgSendType" BO_ 985 5;
BA_ "GenMsgCycleTime" BO_ 983 50;
BA_ "GenMsgSendType" BO_ 983 0;
BA_ "GenMsgCycleTime" BO_ 962 1000;
BA_ "GenMsgSendType" BO_ 962 5;
BA_ "GenMsgCycleTime" BO_ 961 1000;
BA_ "GenMsgSendType" BO_ 961 5;
BA_ "FrameGatewayNetwork" BO_ 1122 "HS3_CAN";
BA_ "FrameGatewayHS3" BO_ 1122 1122;
BA_ "FrameGatewayId" BO_ 1122 1122;
BA_ "GenMsgCycleTime" BO_ 976 100;
BA_ "GenMsgSendType" BO_ 976 0;
BA_ "NetworkInitialization" BO_ 976 1;
BA_ "GenMsgSendType" BO_ 1080 5;
BA_ "GenMsgCycleTime" BO_ 1080 1000;
BA_ "NetworkInitialization" BO_ 1080 1;
BA_ "FrameGatewayNetwork" BO_ 945 "HS1_CAN";
BA_ "FrameGatewayHS1" BO_ 945 945;
BA_ "FrameGatewayId" BO_ 945 945;
BA_ "GenMsgSendType" BO_ 1053 0;
BA_ "GenMsgCycleTime" BO_ 1053 20;
BA_ "GenMsgDelayTime" BO_ 1053 10;
BA_ "NetworkInitialization" BO_ 1102 1;
BA_ "GenMsgStartDelayTime" BO_ 1102 1125;
BA_ "GenMsgCycleTime" BO_ 1102 100000;
BA_ "GenMsgSendType" BO_ 1102 5;
BA_ "NetworkInitialization" BO_ 1056 1;
BA_ "GenMsgCycleTime" BO_ 1056 1000;
BA_ "GenMsgSendType" BO_ 1056 5;
BA_ "GenMsgCycleTime" BO_ 1487 1000;
BA_ "GenMsgSendType" BO_ 1487 0;
BA_ "NmAsrMessage" BO_ 1487 1;
BA_ "GenMsgILSupport" BO_ 1487 0;
BA_ "GenMsgDelayTime" BO_ 1938 0;
BA_ "GenMsgSendType" BO_ 1938 1;
BA_ "DiagRequest" BO_ 1938 1;
BA_ "GenMsgILSupport" BO_ 1938 0;
BA_ "GenMsgCycleTime" BO_ 1120 1000;
BA_ "GenMsgSendType" BO_ 1120 5;
BA_ "GenMsgDelayTime" BO_ 1946 0;
BA_ "GenMsgSendType" BO_ 1946 1;
BA_ "DiagResponse" BO_ 1946 1;
BA_ "GenMsgILSupport" BO_ 1946 0;
BA_ "FrameGatewayId" BO_ 1110 1110;
BA_ "FrameGatewayNetwork" BO_ 1110 "HS1_CAN";
BA_ "NetworkInitialization" BO_ 1073 1;
BA_ "GenMsgSendType" BO_ 1073 5;
BA_ "GenMsgCycleTime" BO_ 1073 1000;
BA_ "GenMsgCycleTime" BO_ 1082 1000;
BA_ "GenMsgSendType" BO_ 1082 5;
BA_ "NetworkInitialization" BO_ 1082 1;
BA_ "GenMsgSendType" BO_ 1059 0;
BA_ "GenMsgCycleTime" BO_ 1059 100;
BA_ "NetworkInitialization" BO_ 1054 1;
BA_ "GenMsgSendType" BO_ 1054 5;
BA_ "GenMsgCycleTime" BO_ 1054 1000;
BA_ "FrameGatewayId" BO_ 1114 1114;
BA_ "FrameGatewayHS3" BO_ 1114 1114;
BA_ "FrameGatewayNetwork" BO_ 1114 "HS3_CAN";
BA_ "GenMsgSendType" BO_ 1047 5;
BA_ "GenMsgCycleTime" BO_ 1047 1000;
BA_ "NetworkInitialization" BO_ 1105 1;
BA_ "GenMsgSendType" BO_ 1105 5;
BA_ "GenMsgCycleTime" BO_ 1105 1000;
BA_ "NetworkInitialization" BO_ 939 1;
BA_ "FrameGatewayId" BO_ 939 939;
BA_ "FrameGatewayHS1" BO_ 939 939;
BA_ "FrameGatewayNetwork" BO_ 939 "HS1_CAN";
BA_ "U_U55x_MY18_Gas_Rx" SG_ 1100 GrossTrainWeight_M_Est 1;
BA_ "GenSigStartValue" SG_ 1100 GrossTrainWeight_M_Est 254;
BA_ "GenSigStartValue" SG_ 370 GearPos_D_Actl 15;
BA_ "U_V36X_MY16_5_Diesel_Rx" SG_ 370 GearPos_D_Actl 1;
BA_ "CrossOver_InfoCAN" SG_ 1126 GpsUtcYr_No_Actl 1;
BA_ "U_CD42_MY15_Diesel_Rx" SG_ 1126 GpsUtcYr_No_Actl 1;
BA_ "U_CD42_MY15_Gas_Rx" SG_ 1126 GpsUtcYr_No_Actl 1;
BA_ "U_UP375_MY18_Gas_Rx" SG_ 1126 GpsUtcYr_No_Actl 1;
BA_ "U_UP375_MY18_Diesel_Rx" SG_ 1126 GpsUtcYr_No_Actl 1;
BA_ "U_CD4_MY17_Diesel_Rx" SG_ 1126 GpsUtcYr_No_Actl 1;
BA_ "U_CD4_MY17_Gas_Rx" SG_ 1126 GpsUtcYr_No_Actl 1;
BA_ "U_V36X_MY16_5_Diesel_Rx" SG_ 1126 GpsUtcYr_No_Actl 1;
BA_ "U_CD42_MY16_Diesel_Rx" SG_ 1126 GpsUtcYr_No_Actl 1;
BA_ "U_CD42_MY16_Gas_Rx" SG_ 1126 GpsUtcYr_No_Actl 1;
BA_ "U_P552_MY18_Gas_Rx" SG_ 1126 GpsUtcYr_No_Actl 1;
BA_ "U_S550_MY18_Gas_Rx" SG_ 1126 GpsUtcYr_No_Actl 1;
BA_ "U_V408_MY18_Gas_Rx" SG_ 1126 GpsUtcYr_No_Actl 1;
BA_ "U_V408_MY18_Diesel_Rx" SG_ 1126 GpsUtcYr_No_Actl 1;
BA_ "U_V36X_MY18_5_Diesel_Rx" SG_ 1126 GpsUtcYr_No_Actl 1;
BA_ "U_V36X_MY19_5_Diesel_Rx" SG_ 1126 GpsUtcYr_No_Actl 1;
BA_ "U_V36X_MY18_5_Gas_Rx" SG_ 1126 GpsUtcYr_No_Actl 1;
BA_ "U_V36X_MY18_5_Hev_Rx" SG_ 1126 GpsUtcYr_No_Actl 1;
BA_ "CrossOver_InfoCAN" SG_ 1126 GpsUtcMnth_No_Actl 1;
BA_ "U_CD42_MY15_Diesel_Rx" SG_ 1126 GpsUtcMnth_No_Actl 1;
BA_ "U_CD42_MY15_Gas_Rx" SG_ 1126 GpsUtcMnth_No_Actl 1;
BA_ "U_UP375_MY18_Gas_Rx" SG_ 1126 GpsUtcMnth_No_Actl 1;
BA_ "U_UP375_MY18_Diesel_Rx" SG_ 1126 GpsUtcMnth_No_Actl 1;
BA_ "U_CD4_MY17_Diesel_Rx" SG_ 1126 GpsUtcMnth_No_Actl 1;
BA_ "U_CD4_MY17_Gas_Rx" SG_ 1126 GpsUtcMnth_No_Actl 1;
BA_ "U_V36X_MY16_5_Diesel_Rx" SG_ 1126 GpsUtcMnth_No_Actl 1;
BA_ "U_CD42_MY16_Diesel_Rx" SG_ 1126 GpsUtcMnth_No_Actl 1;
BA_ "U_CD42_MY16_Gas_Rx" SG_ 1126 GpsUtcMnth_No_Actl 1;
BA_ "U_P552_MY18_Gas_Rx" SG_ 1126 GpsUtcMnth_No_Actl 1;
BA_ "U_S550_MY18_Gas_Rx" SG_ 1126 GpsUtcMnth_No_Actl 1;
BA_ "U_V408_MY18_Gas_Rx" SG_ 1126 GpsUtcMnth_No_Actl 1;
BA_ "U_V408_MY18_Diesel_Rx" SG_ 1126 GpsUtcMnth_No_Actl 1;
BA_ "U_V36X_MY18_5_Diesel_Rx" SG_ 1126 GpsUtcMnth_No_Actl 1;
BA_ "U_V36X_MY19_5_Diesel_Rx" SG_ 1126 GpsUtcMnth_No_Actl 1;
BA_ "U_V36X_MY18_5_Gas_Rx" SG_ 1126 GpsUtcMnth_No_Actl 1;
BA_ "U_V36X_MY18_5_Hev_Rx" SG_ 1126 GpsUtcMnth_No_Actl 1;
BA_ "CrossOver_InfoCAN" SG_ 1126 GpsUtcDay_No_Actl 1;
BA_ "U_CD42_MY15_Diesel_Rx" SG_ 1126 GpsUtcDay_No_Actl 1;
BA_ "U_CD42_MY15_Gas_Rx" SG_ 1126 GpsUtcDay_No_Actl 1;
BA_ "U_UP375_MY18_Gas_Rx" SG_ 1126 GpsUtcDay_No_Actl 1;
BA_ "U_UP375_MY18_Diesel_Rx" SG_ 1126 GpsUtcDay_No_Actl 1;
BA_ "U_CD4_MY17_Diesel_Rx" SG_ 1126 GpsUtcDay_No_Actl 1;
BA_ "U_CD4_MY17_Gas_Rx" SG_ 1126 GpsUtcDay_No_Actl 1;
BA_ "U_V36X_MY16_5_Diesel_Rx" SG_ 1126 GpsUtcDay_No_Actl 1;
BA_ "U_CD42_MY16_Diesel_Rx" SG_ 1126 GpsUtcDay_No_Actl 1;
BA_ "U_CD42_MY16_Gas_Rx" SG_ 1126 GpsUtcDay_No_Actl 1;
BA_ "U_P552_MY18_Gas_Rx" SG_ 1126 GpsUtcDay_No_Actl 1;
BA_ "U_S550_MY18_Gas_Rx" SG_ 1126 GpsUtcDay_No_Actl 1;
BA_ "U_V408_MY18_Gas_Rx" SG_ 1126 GpsUtcDay_No_Actl 1;
BA_ "U_V408_MY18_Diesel_Rx" SG_ 1126 GpsUtcDay_No_Actl 1;
BA_ "U_V36X_MY18_5_Diesel_Rx" SG_ 1126 GpsUtcDay_No_Actl 1;
BA_ "U_V36X_MY19_5_Diesel_Rx" SG_ 1126 GpsUtcDay_No_Actl 1;
BA_ "U_V36X_MY18_5_Gas_Rx" SG_ 1126 GpsUtcDay_No_Actl 1;
BA_ "U_V36X_MY18_5_Hev_Rx" SG_ 1126 GpsUtcDay_No_Actl 1;
BA_ "CrossOver_InfoCAN" SG_ 1126 GPS_UTC_seconds 1;
BA_ "U_CD42_MY15_Diesel_Rx" SG_ 1126 GPS_UTC_seconds 1;
BA_ "U_CD42_MY15_Gas_Rx" SG_ 1126 GPS_UTC_seconds 1;
BA_ "U_UP375_MY18_Gas_Rx" SG_ 1126 GPS_UTC_seconds 1;
BA_ "U_UP375_MY18_Diesel_Rx" SG_ 1126 GPS_UTC_seconds 1;
BA_ "U_CD4_MY17_Diesel_Rx" SG_ 1126 GPS_UTC_seconds 1;
BA_ "U_CD4_MY17_Gas_Rx" SG_ 1126 GPS_UTC_seconds 1;
BA_ "U_V36X_MY16_5_Diesel_Rx" SG_ 1126 GPS_UTC_seconds 1;
BA_ "U_CD42_MY16_Diesel_Rx" SG_ 1126 GPS_UTC_seconds 1;
BA_ "U_CD42_MY16_Gas_Rx" SG_ 1126 GPS_UTC_seconds 1;
BA_ "U_P552_MY18_Gas_Rx" SG_ 1126 GPS_UTC_seconds 1;
BA_ "U_S550_MY18_Gas_Rx" SG_ 1126 GPS_UTC_seconds 1;
BA_ "U_V408_MY18_Gas_Rx" SG_ 1126 GPS_UTC_seconds 1;
BA_ "U_V408_MY18_Diesel_Rx" SG_ 1126 GPS_UTC_seconds 1;
BA_ "U_V36X_MY18_5_Diesel_Rx" SG_ 1126 GPS_UTC_seconds 1;
BA_ "U_V36X_MY19_5_Diesel_Rx" SG_ 1126 GPS_UTC_seconds 1;
BA_ "U_V36X_MY18_5_Gas_Rx" SG_ 1126 GPS_UTC_seconds 1;
BA_ "U_V36X_MY18_5_Hev_Rx" SG_ 1126 GPS_UTC_seconds 1;
BA_ "CrossOver_InfoCAN" SG_ 1126 GPS_UTC_minutes 1;
BA_ "U_CD42_MY15_Diesel_Rx" SG_ 1126 GPS_UTC_minutes 1;
BA_ "U_CD42_MY15_Gas_Rx" SG_ 1126 GPS_UTC_minutes 1;
BA_ "U_UP375_MY18_Gas_Rx" SG_ 1126 GPS_UTC_minutes 1;
BA_ "U_UP375_MY18_Diesel_Rx" SG_ 1126 GPS_UTC_minutes 1;
BA_ "U_CD4_MY17_Diesel_Rx" SG_ 1126 GPS_UTC_minutes 1;
BA_ "U_CD4_MY17_Gas_Rx" SG_ 1126 GPS_UTC_minutes 1;
BA_ "U_V36X_MY16_5_Diesel_Rx" SG_ 1126 GPS_UTC_minutes 1;
BA_ "U_CD42_MY16_Diesel_Rx" SG_ 1126 GPS_UTC_minutes 1;
BA_ "U_CD42_MY16_Gas_Rx" SG_ 1126 GPS_UTC_minutes 1;
BA_ "U_P552_MY18_Gas_Rx" SG_ 1126 GPS_UTC_minutes 1;
BA_ "U_S550_MY18_Gas_Rx" SG_ 1126 GPS_UTC_minutes 1;
BA_ "U_V408_MY18_Gas_Rx" SG_ 1126 GPS_UTC_minutes 1;
BA_ "U_V408_MY18_Diesel_Rx" SG_ 1126 GPS_UTC_minutes 1;
BA_ "U_V36X_MY18_5_Diesel_Rx" SG_ 1126 GPS_UTC_minutes 1;
BA_ "U_V36X_MY19_5_Diesel_Rx" SG_ 1126 GPS_UTC_minutes 1;
BA_ "U_V36X_MY18_5_Gas_Rx" SG_ 1126 GPS_UTC_minutes 1;
BA_ "U_V36X_MY18_5_Hev_Rx" SG_ 1126 GPS_UTC_minutes 1;
BA_ "CrossOver_InfoCAN" SG_ 1126 GPS_UTC_hours 1;
BA_ "U_CD42_MY15_Diesel_Rx" SG_ 1126 GPS_UTC_hours 1;
BA_ "U_CD42_MY15_Gas_Rx" SG_ 1126 GPS_UTC_hours 1;
BA_ "U_UP375_MY18_Gas_Rx" SG_ 1126 GPS_UTC_hours 1;
BA_ "U_UP375_MY18_Diesel_Rx" SG_ 1126 GPS_UTC_hours 1;
BA_ "U_CD4_MY17_Diesel_Rx" SG_ 1126 GPS_UTC_hours 1;
BA_ "U_CD4_MY17_Gas_Rx" SG_ 1126 GPS_UTC_hours 1;
BA_ "U_V36X_MY16_5_Diesel_Rx" SG_ 1126 GPS_UTC_hours 1;
BA_ "U_CD42_MY16_Diesel_Rx" SG_ 1126 GPS_UTC_hours 1;
BA_ "U_CD42_MY16_Gas_Rx" SG_ 1126 GPS_UTC_hours 1;
BA_ "U_P552_MY18_Gas_Rx" SG_ 1126 GPS_UTC_hours 1;
BA_ "U_S550_MY18_Gas_Rx" SG_ 1126 GPS_UTC_hours 1;
BA_ "U_V408_MY18_Gas_Rx" SG_ 1126 GPS_UTC_hours 1;
BA_ "U_V408_MY18_Diesel_Rx" SG_ 1126 GPS_UTC_hours 1;
BA_ "U_V36X_MY18_5_Diesel_Rx" SG_ 1126 GPS_UTC_hours 1;
BA_ "U_V36X_MY19_5_Diesel_Rx" SG_ 1126 GPS_UTC_hours 1;
BA_ "U_V36X_MY18_5_Gas_Rx" SG_ 1126 GPS_UTC_hours 1;
BA_ "U_V36X_MY18_5_Hev_Rx" SG_ 1126 GPS_UTC_hours 1;
BA_ "CrossOver_InfoCAN" SG_ 1126 GPS_Pdop 1;
BA_ "U_P552_MY18_Gas_Rx" SG_ 1126 GPS_Pdop 1;
BA_ "CrossOver_InfoCAN" SG_ 1126 GPS_Compass_direction 1;
BA_ "U_P552_MY18_Gas_Rx" SG_ 1126 GPS_Compass_direction 1;
BA_ "CrossOver_InfoCAN" SG_ 1126 GPS_Actual_vs_Infer_pos 1;
BA_ "U_P552_MY18_Gas_Rx" SG_ 1126 GPS_Actual_vs_Infer_pos 1;
BA_ "U_S550_MY18_Gas_Rx" SG_ 1126 GPS_Actual_vs_Infer_pos 1;
BA_ "CrossOver_InfoCAN" SG_ 1126 Gps_B_Falt 1;
BA_ "U_P552_MY18_Gas_Rx" SG_ 1126 Gps_B_Falt 1;
BA_ "U_S550_MY18_Gas_Rx" SG_ 1126 Gps_B_Falt 1;
BA_ "CrossOver_InfoCAN" SG_ 1215 EhData2_No_Actl 1;
BA_ "U_CD4_MY13_Diesel_Rx" SG_ 1215 EhData2_No_Actl 1;
BA_ "U_CD4_MY13_Gas_Rx" SG_ 1215 EhData2_No_Actl 1;
BA_ "U_CD4_MY13_Hev_Rx" SG_ 1215 EhData2_No_Actl 1;
BA_ "U_CD4_MY13_Phev_Rx" SG_ 1215 EhData2_No_Actl 1;
BA_ "U_CD42_MY15_Diesel_Rx" SG_ 1215 EhData2_No_Actl 1;
BA_ "U_CD42_MY15_Gas_Rx" SG_ 1215 EhData2_No_Actl 1;
BA_ "U_UP375_MY18_Gas_Rx" SG_ 1215 EhData2_No_Actl 1;
BA_ "U_UP375_MY18_Diesel_Rx" SG_ 1215 EhData2_No_Actl 1;
BA_ "U_CD4_MY14_Diesel_Rx" SG_ 1215 EhData2_No_Actl 1;
BA_ "U_CD4_MY14_Gas_Rx" SG_ 1215 EhData2_No_Actl 1;
BA_ "U_CD4_MY14_Hev_Rx" SG_ 1215 EhData2_No_Actl 1;
BA_ "U_CD4_MY14_Phev_Rx" SG_ 1215 EhData2_No_Actl 1;
BA_ "U_CD4_MY17_Diesel_Rx" SG_ 1215 EhData2_No_Actl 1;
BA_ "U_CD4_MY17_Gas_Rx" SG_ 1215 EhData2_No_Actl 1;
BA_ "U_CD4_MY17_Hev_Rx" SG_ 1215 EhData2_No_Actl 1;
BA_ "U_CD4_MY17_Phev_Rx" SG_ 1215 EhData2_No_Actl 1;
BA_ "U_V36X_MY16_5_Diesel_Rx" SG_ 1215 EhData2_No_Actl 1;
BA_ "U_CD42_MY16_Diesel_Rx" SG_ 1215 EhData2_No_Actl 1;
BA_ "U_CD42_MY16_Gas_Rx" SG_ 1215 EhData2_No_Actl 1;
BA_ "U_P552_MY18_Gas_Rx" SG_ 1215 EhData2_No_Actl 1;
BA_ "U_U55x_MY18_Gas_Rx" SG_ 1215 EhData2_No_Actl 1;
BA_ "U_S550_MY18_Gas_Rx" SG_ 1215 EhData2_No_Actl 1;
BA_ "U_V408_MY18_Gas_Rx" SG_ 1215 EhData2_No_Actl 1;
BA_ "U_V408_MY18_Diesel_Rx" SG_ 1215 EhData2_No_Actl 1;
BA_ "U_V36X_MY18_5_Diesel_Rx" SG_ 1215 EhData2_No_Actl 1;
BA_ "U_V36X_MY19_5_Diesel_Rx" SG_ 1215 EhData2_No_Actl 1;
BA_ "U_V36X_MY18_5_Gas_Rx" SG_ 1215 EhData2_No_Actl 1;
BA_ "U_V36X_MY18_5_Hev_Rx" SG_ 1215 EhData2_No_Actl 1;
BA_ "CrossOver_InfoCAN" SG_ 1214 EhData1_No_Actl 1;
BA_ "U_CD4_MY13_Diesel_Rx" SG_ 1214 EhData1_No_Actl 1;
BA_ "U_CD4_MY13_Gas_Rx" SG_ 1214 EhData1_No_Actl 1;
BA_ "U_CD4_MY13_Hev_Rx" SG_ 1214 EhData1_No_Actl 1;
BA_ "U_CD4_MY13_Phev_Rx" SG_ 1214 EhData1_No_Actl 1;
BA_ "U_CD42_MY15_Diesel_Rx" SG_ 1214 EhData1_No_Actl 1;
BA_ "U_CD42_MY15_Gas_Rx" SG_ 1214 EhData1_No_Actl 1;
BA_ "U_UP375_MY18_Gas_Rx" SG_ 1214 EhData1_No_Actl 1;
BA_ "U_UP375_MY18_Diesel_Rx" SG_ 1214 EhData1_No_Actl 1;
BA_ "U_CD4_MY14_Diesel_Rx" SG_ 1214 EhData1_No_Actl 1;
BA_ "U_CD4_MY14_Gas_Rx" SG_ 1214 EhData1_No_Actl 1;
BA_ "U_CD4_MY14_Hev_Rx" SG_ 1214 EhData1_No_Actl 1;
BA_ "U_CD4_MY14_Phev_Rx" SG_ 1214 EhData1_No_Actl 1;
BA_ "U_CD4_MY17_Diesel_Rx" SG_ 1214 EhData1_No_Actl 1;
BA_ "U_CD4_MY17_Gas_Rx" SG_ 1214 EhData1_No_Actl 1;
BA_ "U_CD4_MY17_Hev_Rx" SG_ 1214 EhData1_No_Actl 1;
BA_ "U_CD4_MY17_Phev_Rx" SG_ 1214 EhData1_No_Actl 1;
BA_ "U_V36X_MY16_5_Diesel_Rx" SG_ 1214 EhData1_No_Actl 1;
BA_ "U_CD42_MY16_Diesel_Rx" SG_ 1214 EhData1_No_Actl 1;
BA_ "U_CD42_MY16_Gas_Rx" SG_ 1214 EhData1_No_Actl 1;
BA_ "U_P552_MY18_Gas_Rx" SG_ 1214 EhData1_No_Actl 1;
BA_ "U_U55x_MY18_Gas_Rx" SG_ 1214 EhData1_No_Actl 1;
BA_ "U_S550_MY18_Gas_Rx" SG_ 1214 EhData1_No_Actl 1;
BA_ "U_V408_MY18_Gas_Rx" SG_ 1214 EhData1_No_Actl 1;
BA_ "U_V408_MY18_Diesel_Rx" SG_ 1214 EhData1_No_Actl 1;
BA_ "U_V36X_MY18_5_Diesel_Rx" SG_ 1214 EhData1_No_Actl 1;
BA_ "U_V36X_MY19_5_Diesel_Rx" SG_ 1214 EhData1_No_Actl 1;
BA_ "U_V36X_MY18_5_Gas_Rx" SG_ 1214 EhData1_No_Actl 1;
BA_ "U_V36X_MY18_5_Hev_Rx" SG_ 1214 EhData1_No_Actl 1;
BA_ "GenSigStartValue" SG_ 980 AdbBrdr1Up_An_Rq 510;
BA_ "GenSigStartValue" SG_ 980 AdbBrdr1Right_An_Rq 2046;
BA_ "GenSigStartValue" SG_ 980 AdbBrdr1Low_An_Rq 510;
BA_ "GenSigStartValue" SG_ 980 AdbBrdr1Left_An_Rq 2046;
BA_ "U_V36X_MY18_5_Hev_Tx" SG_ 973 TsrVl1RstrcMsgTxt2_D_Rq 1;
BA_ "U_V36X_MY18_5_Gas_Tx" SG_ 973 TsrVl1RstrcMsgTxt2_D_Rq 1;
BA_ "U_V36X_MY19_5_Diesel_Tx" SG_ 973 TsrVl1RstrcMsgTxt2_D_Rq 1;
BA_ "U_V36X_MY18_5_Diesel_Tx" SG_ 973 TsrVl1RstrcMsgTxt2_D_Rq 1;
BA_ "U_V408_MY18_Diesel_Tx" SG_ 973 TsrVl1RstrcMsgTxt2_D_Rq 1;
BA_ "U_V408_MY18_Gas_Tx" SG_ 973 TsrVl1RstrcMsgTxt2_D_Rq 1;
BA_ "U_S550_MY18_Gas_Tx" SG_ 973 TsrVl1RstrcMsgTxt2_D_Rq 1;
BA_ "U_P552_MY18_Gas_Tx" SG_ 973 TsrVl1RstrcMsgTxt2_D_Rq 1;
BA_ "U_CD43_MY17_Gas_Tx" SG_ 973 TsrVl1RstrcMsgTxt2_D_Rq 1;
BA_ "U_CD42_MY16_Gas_Tx" SG_ 973 TsrVl1RstrcMsgTxt2_D_Rq 1;
BA_ "U_CD42_MY16_Diesel_Tx" SG_ 973 TsrVl1RstrcMsgTxt2_D_Rq 1;
BA_ "U_V36X_MY16_5_Diesel_Tx" SG_ 973 TsrVl1RstrcMsgTxt2_D_Rq 1;
BA_ "U_CD4_MY17_Phev_Tx" SG_ 973 TsrVl1RstrcMsgTxt2_D_Rq 1;
BA_ "U_CD4_MY17_Hev_Tx" SG_ 973 TsrVl1RstrcMsgTxt2_D_Rq 1;
BA_ "U_CD4_MY17_Gas_Tx" SG_ 973 TsrVl1RstrcMsgTxt2_D_Rq 1;
BA_ "U_CD4_MY17_Diesel_Tx" SG_ 973 TsrVl1RstrcMsgTxt2_D_Rq 1;
BA_ "U_CD4_MY14_Phev_Tx" SG_ 973 TsrVl1RstrcMsgTxt2_D_Rq 1;
BA_ "U_CD4_MY14_Hev_Tx" SG_ 973 TsrVl1RstrcMsgTxt2_D_Rq 1;
BA_ "U_CD4_MY14_Gas_Tx" SG_ 973 TsrVl1RstrcMsgTxt2_D_Rq 1;
BA_ "U_CD4_MY14_Diesel_Tx" SG_ 973 TsrVl1RstrcMsgTxt2_D_Rq 1;
BA_ "U_UP375_MY18_Diesel_Tx" SG_ 973 TsrVl1RstrcMsgTxt2_D_Rq 1;
BA_ "U_UP375_MY18_Gas_Tx" SG_ 973 TsrVl1RstrcMsgTxt2_D_Rq 1;
BA_ "U_CD42_MY15_Gas_Tx" SG_ 973 TsrVl1RstrcMsgTxt2_D_Rq 1;
BA_ "U_CD42_MY15_Diesel_Tx" SG_ 973 TsrVl1RstrcMsgTxt2_D_Rq 1;
BA_ "U_CD4_MY13_Phev_Tx" SG_ 973 TsrVl1RstrcMsgTxt2_D_Rq 1;
BA_ "U_CD4_MY13_Hev_Tx" SG_ 973 TsrVl1RstrcMsgTxt2_D_Rq 1;
BA_ "U_CD4_MY13_Gas_Tx" SG_ 973 TsrVl1RstrcMsgTxt2_D_Rq 1;
BA_ "U_CD4_MY13_Diesel_Tx" SG_ 973 TsrVl1RstrcMsgTxt2_D_Rq 1;
BA_ "GenSigStartValue" SG_ 973 TsrVl1RstrcMsgTxt2_D_Rq 1;
BA_ "GenSigSendType" SG_ 973 TsrVl1RstrcMsgTxt2_D_Rq 3;
BA_ "U_V36X_MY18_5_Hev_Tx" SG_ 973 TsrVl2RstrcMsgTxt2_D_Rq 1;
BA_ "U_V36X_MY18_5_Gas_Tx" SG_ 973 TsrVl2RstrcMsgTxt2_D_Rq 1;
BA_ "U_V36X_MY19_5_Diesel_Tx" SG_ 973 TsrVl2RstrcMsgTxt2_D_Rq 1;
BA_ "U_V36X_MY18_5_Diesel_Tx" SG_ 973 TsrVl2RstrcMsgTxt2_D_Rq 1;
BA_ "U_V408_MY18_Diesel_Tx" SG_ 973 TsrVl2RstrcMsgTxt2_D_Rq 1;
BA_ "U_V408_MY18_Gas_Tx" SG_ 973 TsrVl2RstrcMsgTxt2_D_Rq 1;
BA_ "U_S550_MY18_Gas_Tx" SG_ 973 TsrVl2RstrcMsgTxt2_D_Rq 1;
BA_ "U_P552_MY18_Gas_Tx" SG_ 973 TsrVl2RstrcMsgTxt2_D_Rq 1;
BA_ "U_CD43_MY17_Gas_Tx" SG_ 973 TsrVl2RstrcMsgTxt2_D_Rq 1;
BA_ "U_CD42_MY16_Gas_Tx" SG_ 973 TsrVl2RstrcMsgTxt2_D_Rq 1;
BA_ "U_CD42_MY16_Diesel_Tx" SG_ 973 TsrVl2RstrcMsgTxt2_D_Rq 1;
BA_ "U_V36X_MY16_5_Diesel_Tx" SG_ 973 TsrVl2RstrcMsgTxt2_D_Rq 1;
BA_ "U_CD4_MY17_Phev_Tx" SG_ 973 TsrVl2RstrcMsgTxt2_D_Rq 1;
BA_ "U_CD4_MY17_Hev_Tx" SG_ 973 TsrVl2RstrcMsgTxt2_D_Rq 1;
BA_ "U_CD4_MY17_Gas_Tx" SG_ 973 TsrVl2RstrcMsgTxt2_D_Rq 1;
BA_ "U_CD4_MY17_Diesel_Tx" SG_ 973 TsrVl2RstrcMsgTxt2_D_Rq 1;
BA_ "U_CD4_MY14_Phev_Tx" SG_ 973 TsrVl2RstrcMsgTxt2_D_Rq 1;
BA_ "U_CD4_MY14_Hev_Tx" SG_ 973 TsrVl2RstrcMsgTxt2_D_Rq 1;
BA_ "U_CD4_MY14_Gas_Tx" SG_ 973 TsrVl2RstrcMsgTxt2_D_Rq 1;
BA_ "U_CD4_MY14_Diesel_Tx" SG_ 973 TsrVl2RstrcMsgTxt2_D_Rq 1;
BA_ "U_UP375_MY18_Diesel_Tx" SG_ 973 TsrVl2RstrcMsgTxt2_D_Rq 1;
BA_ "U_UP375_MY18_Gas_Tx" SG_ 973 TsrVl2RstrcMsgTxt2_D_Rq 1;
BA_ "U_CD42_MY15_Gas_Tx" SG_ 973 TsrVl2RstrcMsgTxt2_D_Rq 1;
BA_ "U_CD42_MY15_Diesel_Tx" SG_ 973 TsrVl2RstrcMsgTxt2_D_Rq 1;
BA_ "U_CD4_MY13_Phev_Tx" SG_ 973 TsrVl2RstrcMsgTxt2_D_Rq 1;
BA_ "U_CD4_MY13_Hev_Tx" SG_ 973 TsrVl2RstrcMsgTxt2_D_Rq 1;
BA_ "U_CD4_MY13_Gas_Tx" SG_ 973 TsrVl2RstrcMsgTxt2_D_Rq 1;
BA_ "U_CD4_MY13_Diesel_Tx" SG_ 973 TsrVl2RstrcMsgTxt2_D_Rq 1;
BA_ "GenSigStartValue" SG_ 973 TsrVl2RstrcMsgTxt2_D_Rq 1;
BA_ "GenSigSendType" SG_ 973 TsrVl2RstrcMsgTxt2_D_Rq 3;
BA_ "U_V36X_MY18_5_Hev_Tx" SG_ 973 TsrOvtkMsgTxt_D_Rq 1;
BA_ "U_V36X_MY18_5_Gas_Tx" SG_ 973 TsrOvtkMsgTxt_D_Rq 1;
BA_ "U_V36X_MY19_5_Diesel_Tx" SG_ 973 TsrOvtkMsgTxt_D_Rq 1;
BA_ "U_V36X_MY18_5_Diesel_Tx" SG_ 973 TsrOvtkMsgTxt_D_Rq 1;
BA_ "U_V408_MY18_Diesel_Tx" SG_ 973 TsrOvtkMsgTxt_D_Rq 1;
BA_ "U_V408_MY18_Gas_Tx" SG_ 973 TsrOvtkMsgTxt_D_Rq 1;
BA_ "U_S550_MY18_Gas_Tx" SG_ 973 TsrOvtkMsgTxt_D_Rq 1;
BA_ "U_P552_MY18_Gas_Tx" SG_ 973 TsrOvtkMsgTxt_D_Rq 1;
BA_ "U_CD43_MY17_Gas_Tx" SG_ 973 TsrOvtkMsgTxt_D_Rq 1;
BA_ "U_CD42_MY16_Gas_Tx" SG_ 973 TsrOvtkMsgTxt_D_Rq 1;
BA_ "U_CD42_MY16_Diesel_Tx" SG_ 973 TsrOvtkMsgTxt_D_Rq 1;
BA_ "U_C489_MY17_Gas_Tx" SG_ 973 TsrOvtkMsgTxt_D_Rq 1;
BA_ "U_V36X_MY16_5_Diesel_Tx" SG_ 973 TsrOvtkMsgTxt_D_Rq 1;
BA_ "U_CD4_MY17_Phev_Tx" SG_ 973 TsrOvtkMsgTxt_D_Rq 1;
BA_ "U_CD4_MY17_Hev_Tx" SG_ 973 TsrOvtkMsgTxt_D_Rq 1;
BA_ "U_CD4_MY17_Gas_Tx" SG_ 973 TsrOvtkMsgTxt_D_Rq 1;
BA_ "U_CD4_MY17_Diesel_Tx" SG_ 973 TsrOvtkMsgTxt_D_Rq 1;
BA_ "U_CD4_MY14_Phev_Tx" SG_ 973 TsrOvtkMsgTxt_D_Rq 1;
BA_ "U_CD4_MY14_Hev_Tx" SG_ 973 TsrOvtkMsgTxt_D_Rq 1;
BA_ "U_CD4_MY14_Gas_Tx" SG_ 973 TsrOvtkMsgTxt_D_Rq 1;
BA_ "U_CD4_MY14_Diesel_Tx" SG_ 973 TsrOvtkMsgTxt_D_Rq 1;
BA_ "U_UP375_MY18_Diesel_Tx" SG_ 973 TsrOvtkMsgTxt_D_Rq 1;
BA_ "U_UP375_MY18_Gas_Tx" SG_ 973 TsrOvtkMsgTxt_D_Rq 1;
BA_ "U_C489_MY14_Gas_Tx" SG_ 973 TsrOvtkMsgTxt_D_Rq 1;
BA_ "U_CD42_MY15_Gas_Tx" SG_ 973 TsrOvtkMsgTxt_D_Rq 1;
BA_ "U_CD42_MY15_Diesel_Tx" SG_ 973 TsrOvtkMsgTxt_D_Rq 1;
BA_ "U_CD4_MY13_Phev_Tx" SG_ 973 TsrOvtkMsgTxt_D_Rq 1;
BA_ "U_CD4_MY13_Hev_Tx" SG_ 973 TsrOvtkMsgTxt_D_Rq 1;
BA_ "U_CD4_MY13_Gas_Tx" SG_ 973 TsrOvtkMsgTxt_D_Rq 1;
BA_ "U_CD4_MY13_Diesel_Tx" SG_ 973 TsrOvtkMsgTxt_D_Rq 1;
BA_ "GenSigStartValue" SG_ 973 TsrOvtkMsgTxt_D_Rq 1;
BA_ "CrossOver_InfoCAN" SG_ 973 TsrOvtkMsgTxt_D_Rq 1;
BA_ "GenSigSendType" SG_ 973 TsrOvtkMsgTxt_D_Rq 3;
BA_ "U_S550_MY18_Gas_Tx" SG_ 973 WwaWarn_B_Rq 1;
BA_ "U_P552_MY18_Gas_Tx" SG_ 973 WwaWarn_B_Rq 1;
BA_ "GenSigSendType" SG_ 973 WwaWarn_B_Rq 3;
BA_ "U_V36X_MY18_5_Hev_Tx" SG_ 973 TsrVl2PrmntMsgTxt_D_Rq 1;
BA_ "U_V36X_MY18_5_Gas_Tx" SG_ 973 TsrVl2PrmntMsgTxt_D_Rq 1;
BA_ "U_V36X_MY19_5_Diesel_Tx" SG_ 973 TsrVl2PrmntMsgTxt_D_Rq 1;
BA_ "U_V36X_MY18_5_Diesel_Tx" SG_ 973 TsrVl2PrmntMsgTxt_D_Rq 1;
BA_ "U_V408_MY18_Diesel_Tx" SG_ 973 TsrVl2PrmntMsgTxt_D_Rq 1;
BA_ "U_V408_MY18_Gas_Tx" SG_ 973 TsrVl2PrmntMsgTxt_D_Rq 1;
BA_ "U_S550_MY18_Gas_Tx" SG_ 973 TsrVl2PrmntMsgTxt_D_Rq 1;
BA_ "U_P552_MY18_Gas_Tx" SG_ 973 TsrVl2PrmntMsgTxt_D_Rq 1;
BA_ "U_CD43_MY17_Gas_Tx" SG_ 973 TsrVl2PrmntMsgTxt_D_Rq 1;
BA_ "U_CD42_MY16_Gas_Tx" SG_ 973 TsrVl2PrmntMsgTxt_D_Rq 1;
BA_ "U_CD42_MY16_Diesel_Tx" SG_ 973 TsrVl2PrmntMsgTxt_D_Rq 1;
BA_ "U_V36X_MY16_5_Diesel_Tx" SG_ 973 TsrVl2PrmntMsgTxt_D_Rq 1;
BA_ "U_CD4_MY17_Phev_Tx" SG_ 973 TsrVl2PrmntMsgTxt_D_Rq 1;
BA_ "U_CD4_MY17_Hev_Tx" SG_ 973 TsrVl2PrmntMsgTxt_D_Rq 1;
BA_ "U_CD4_MY17_Gas_Tx" SG_ 973 TsrVl2PrmntMsgTxt_D_Rq 1;
BA_ "U_CD4_MY17_Diesel_Tx" SG_ 973 TsrVl2PrmntMsgTxt_D_Rq 1;
BA_ "U_CD4_MY14_Phev_Tx" SG_ 973 TsrVl2PrmntMsgTxt_D_Rq 1;
BA_ "U_CD4_MY14_Hev_Tx" SG_ 973 TsrVl2PrmntMsgTxt_D_Rq 1;
BA_ "U_CD4_MY14_Gas_Tx" SG_ 973 TsrVl2PrmntMsgTxt_D_Rq 1;
BA_ "U_CD4_MY14_Diesel_Tx" SG_ 973 TsrVl2PrmntMsgTxt_D_Rq 1;
BA_ "U_UP375_MY18_Diesel_Tx" SG_ 973 TsrVl2PrmntMsgTxt_D_Rq 1;
BA_ "U_UP375_MY18_Gas_Tx" SG_ 973 TsrVl2PrmntMsgTxt_D_Rq 1;
BA_ "U_CD42_MY15_Gas_Tx" SG_ 973 TsrVl2PrmntMsgTxt_D_Rq 1;
BA_ "U_CD42_MY15_Diesel_Tx" SG_ 973 TsrVl2PrmntMsgTxt_D_Rq 1;
BA_ "U_CD4_MY13_Phev_Tx" SG_ 973 TsrVl2PrmntMsgTxt_D_Rq 1;
BA_ "U_CD4_MY13_Hev_Tx" SG_ 973 TsrVl2PrmntMsgTxt_D_Rq 1;
BA_ "U_CD4_MY13_Gas_Tx" SG_ 973 TsrVl2PrmntMsgTxt_D_Rq 1;
BA_ "U_CD4_MY13_Diesel_Tx" SG_ 973 TsrVl2PrmntMsgTxt_D_Rq 1;
BA_ "GenSigSendType" SG_ 973 TsrVl2PrmntMsgTxt_D_Rq 3;
BA_ "U_V36X_MY18_5_Hev_Tx" SG_ 973 TsrVl1PrmntMsgTxt_D_Rq 1;
BA_ "U_V36X_MY18_5_Gas_Tx" SG_ 973 TsrVl1PrmntMsgTxt_D_Rq 1;
BA_ "U_V36X_MY19_5_Diesel_Tx" SG_ 973 TsrVl1PrmntMsgTxt_D_Rq 1;
BA_ "U_V36X_MY18_5_Diesel_Tx" SG_ 973 TsrVl1PrmntMsgTxt_D_Rq 1;
BA_ "U_V408_MY18_Diesel_Tx" SG_ 973 TsrVl1PrmntMsgTxt_D_Rq 1;
BA_ "U_V408_MY18_Gas_Tx" SG_ 973 TsrVl1PrmntMsgTxt_D_Rq 1;
BA_ "U_S550_MY18_Gas_Tx" SG_ 973 TsrVl1PrmntMsgTxt_D_Rq 1;
BA_ "U_P552_MY18_Gas_Tx" SG_ 973 TsrVl1PrmntMsgTxt_D_Rq 1;
BA_ "U_CD43_MY17_Gas_Tx" SG_ 973 TsrVl1PrmntMsgTxt_D_Rq 1;
BA_ "U_CD42_MY16_Gas_Tx" SG_ 973 TsrVl1PrmntMsgTxt_D_Rq 1;
BA_ "U_CD42_MY16_Diesel_Tx" SG_ 973 TsrVl1PrmntMsgTxt_D_Rq 1;
BA_ "U_V36X_MY16_5_Diesel_Tx" SG_ 973 TsrVl1PrmntMsgTxt_D_Rq 1;
BA_ "U_CD4_MY17_Phev_Tx" SG_ 973 TsrVl1PrmntMsgTxt_D_Rq 1;
BA_ "U_CD4_MY17_Hev_Tx" SG_ 973 TsrVl1PrmntMsgTxt_D_Rq 1;
BA_ "U_CD4_MY17_Gas_Tx" SG_ 973 TsrVl1PrmntMsgTxt_D_Rq 1;
BA_ "U_CD4_MY17_Diesel_Tx" SG_ 973 TsrVl1PrmntMsgTxt_D_Rq 1;
BA_ "U_CD4_MY14_Phev_Tx" SG_ 973 TsrVl1PrmntMsgTxt_D_Rq 1;
BA_ "U_CD4_MY14_Hev_Tx" SG_ 973 TsrVl1PrmntMsgTxt_D_Rq 1;
BA_ "U_CD4_MY14_Gas_Tx" SG_ 973 TsrVl1PrmntMsgTxt_D_Rq 1;
BA_ "U_CD4_MY14_Diesel_Tx" SG_ 973 TsrVl1PrmntMsgTxt_D_Rq 1;
BA_ "U_UP375_MY18_Diesel_Tx" SG_ 973 TsrVl1PrmntMsgTxt_D_Rq 1;
BA_ "U_UP375_MY18_Gas_Tx" SG_ 973 TsrVl1PrmntMsgTxt_D_Rq 1;
BA_ "U_CD42_MY15_Gas_Tx" SG_ 973 TsrVl1PrmntMsgTxt_D_Rq 1;
BA_ "U_CD42_MY15_Diesel_Tx" SG_ 973 TsrVl1PrmntMsgTxt_D_Rq 1;
BA_ "U_CD4_MY13_Phev_Tx" SG_ 973 TsrVl1PrmntMsgTxt_D_Rq 1;
BA_ "U_CD4_MY13_Hev_Tx" SG_ 973 TsrVl1PrmntMsgTxt_D_Rq 1;
BA_ "U_CD4_MY13_Gas_Tx" SG_ 973 TsrVl1PrmntMsgTxt_D_Rq 1;
BA_ "U_CD4_MY13_Diesel_Tx" SG_ 973 TsrVl1PrmntMsgTxt_D_Rq 1;
BA_ "GenSigSendType" SG_ 973 TsrVl1PrmntMsgTxt_D_Rq 3;
BA_ "U_V36X_MY18_5_Hev_Tx" SG_ 973 TsrOvtkMsgTxt2_D_Rq 1;
BA_ "U_V36X_MY18_5_Gas_Tx" SG_ 973 TsrOvtkMsgTxt2_D_Rq 1;
BA_ "U_V363E_N_MY19_5_20_Diesel_Tx" SG_ 973 TsrOvtkMsgTxt2_D_Rq 1;
BA_ "U_V363E_N_MY19_5_20_Gas_Tx" SG_ 973 TsrOvtkMsgTxt2_D_Rq 1;
BA_ "U_V36X_MY19_5_Diesel_Tx" SG_ 973 TsrOvtkMsgTxt2_D_Rq 1;
BA_ "U_V36X_MY18_5_Diesel_Tx" SG_ 973 TsrOvtkMsgTxt2_D_Rq 1;
BA_ "U_V408_MY18_Diesel_Tx" SG_ 973 TsrOvtkMsgTxt2_D_Rq 1;
BA_ "U_V408_MY18_Gas_Tx" SG_ 973 TsrOvtkMsgTxt2_D_Rq 1;
BA_ "U_S550_MY18_Gas_Tx" SG_ 973 TsrOvtkMsgTxt2_D_Rq 1;
BA_ "U_P552_MY18_Gas_Tx" SG_ 973 TsrOvtkMsgTxt2_D_Rq 1;
BA_ "U_CD43_MY17_Gas_Tx" SG_ 973 TsrOvtkMsgTxt2_D_Rq 1;
BA_ "U_CD42_MY16_Gas_Tx" SG_ 973 TsrOvtkMsgTxt2_D_Rq 1;
BA_ "U_CD42_MY16_Diesel_Tx" SG_ 973 TsrOvtkMsgTxt2_D_Rq 1;
BA_ "U_V36X_MY16_5_Diesel_Tx" SG_ 973 TsrOvtkMsgTxt2_D_Rq 1;
BA_ "U_CD4_MY17_Phev_Tx" SG_ 973 TsrOvtkMsgTxt2_D_Rq 1;
BA_ "U_CD4_MY17_Hev_Tx" SG_ 973 TsrOvtkMsgTxt2_D_Rq 1;
BA_ "U_CD4_MY17_Gas_Tx" SG_ 973 TsrOvtkMsgTxt2_D_Rq 1;
BA_ "U_CD4_MY17_Diesel_Tx" SG_ 973 TsrOvtkMsgTxt2_D_Rq 1;
BA_ "U_CD4_MY14_Phev_Tx" SG_ 973 TsrOvtkMsgTxt2_D_Rq 1;
BA_ "U_CD4_MY14_Hev_Tx" SG_ 973 TsrOvtkMsgTxt2_D_Rq 1;
BA_ "U_CD4_MY14_Gas_Tx" SG_ 973 TsrOvtkMsgTxt2_D_Rq 1;
BA_ "U_CD4_MY14_Diesel_Tx" SG_ 973 TsrOvtkMsgTxt2_D_Rq 1;
BA_ "U_UP375_MY18_Diesel_Tx" SG_ 973 TsrOvtkMsgTxt2_D_Rq 1;
BA_ "U_UP375_MY18_Gas_Tx" SG_ 973 TsrOvtkMsgTxt2_D_Rq 1;
BA_ "U_CD42_MY15_Gas_Tx" SG_ 973 TsrOvtkMsgTxt2_D_Rq 1;
BA_ "U_CD42_MY15_Diesel_Tx" SG_ 973 TsrOvtkMsgTxt2_D_Rq 1;
BA_ "U_CD4_MY13_Phev_Tx" SG_ 973 TsrOvtkMsgTxt2_D_Rq 1;
BA_ "U_CD4_MY13_Hev_Tx" SG_ 973 TsrOvtkMsgTxt2_D_Rq 1;
BA_ "U_CD4_MY13_Gas_Tx" SG_ 973 TsrOvtkMsgTxt2_D_Rq 1;
BA_ "U_CD4_MY13_Diesel_Tx" SG_ 973 TsrOvtkMsgTxt2_D_Rq 1;
BA_ "GenSigSendType" SG_ 973 TsrOvtkMsgTxt2_D_Rq 3;
BA_ "U_V36X_MY18_5_Hev_Tx" SG_ 973 TsrVlUnitMsgTxt_D_Rq 1;
BA_ "U_V36X_MY18_5_Gas_Tx" SG_ 973 TsrVlUnitMsgTxt_D_Rq 1;
BA_ "U_V36X_MY19_5_Diesel_Tx" SG_ 973 TsrVlUnitMsgTxt_D_Rq 1;
BA_ "U_V36X_MY18_5_Diesel_Tx" SG_ 973 TsrVlUnitMsgTxt_D_Rq 1;
BA_ "U_V408_MY18_Diesel_Tx" SG_ 973 TsrVlUnitMsgTxt_D_Rq 1;
BA_ "U_V408_MY18_Gas_Tx" SG_ 973 TsrVlUnitMsgTxt_D_Rq 1;
BA_ "U_S550_MY18_Gas_Tx" SG_ 973 TsrVlUnitMsgTxt_D_Rq 1;
BA_ "U_P552_MY18_Gas_Tx" SG_ 973 TsrVlUnitMsgTxt_D_Rq 1;
BA_ "U_CD43_MY17_Gas_Tx" SG_ 973 TsrVlUnitMsgTxt_D_Rq 1;
BA_ "U_CD42_MY16_Gas_Tx" SG_ 973 TsrVlUnitMsgTxt_D_Rq 1;
BA_ "U_CD42_MY16_Diesel_Tx" SG_ 973 TsrVlUnitMsgTxt_D_Rq 1;
BA_ "U_C489_MY17_Gas_Tx" SG_ 973 TsrVlUnitMsgTxt_D_Rq 1;
BA_ "U_V36X_MY16_5_Diesel_Tx" SG_ 973 TsrVlUnitMsgTxt_D_Rq 1;
BA_ "U_CD4_MY17_Phev_Tx" SG_ 973 TsrVlUnitMsgTxt_D_Rq 1;
BA_ "U_CD4_MY17_Hev_Tx" SG_ 973 TsrVlUnitMsgTxt_D_Rq 1;
BA_ "U_CD4_MY17_Gas_Tx" SG_ 973 TsrVlUnitMsgTxt_D_Rq 1;
BA_ "U_CD4_MY17_Diesel_Tx" SG_ 973 TsrVlUnitMsgTxt_D_Rq 1;
BA_ "U_CD4_MY14_Phev_Tx" SG_ 973 TsrVlUnitMsgTxt_D_Rq 1;
BA_ "U_CD4_MY14_Hev_Tx" SG_ 973 TsrVlUnitMsgTxt_D_Rq 1;
BA_ "U_CD4_MY14_Gas_Tx" SG_ 973 TsrVlUnitMsgTxt_D_Rq 1;
BA_ "U_CD4_MY14_Diesel_Tx" SG_ 973 TsrVlUnitMsgTxt_D_Rq 1;
BA_ "U_UP375_MY18_Diesel_Tx" SG_ 973 TsrVlUnitMsgTxt_D_Rq 1;
BA_ "U_UP375_MY18_Gas_Tx" SG_ 973 TsrVlUnitMsgTxt_D_Rq 1;
BA_ "U_C489_MY14_Gas_Tx" SG_ 973 TsrVlUnitMsgTxt_D_Rq 1;
BA_ "U_CD42_MY15_Gas_Tx" SG_ 973 TsrVlUnitMsgTxt_D_Rq 1;
BA_ "U_CD42_MY15_Diesel_Tx" SG_ 973 TsrVlUnitMsgTxt_D_Rq 1;
BA_ "U_CD4_MY13_Phev_Tx" SG_ 973 TsrVlUnitMsgTxt_D_Rq 1;
BA_ "U_CD4_MY13_Hev_Tx" SG_ 973 TsrVlUnitMsgTxt_D_Rq 1;
BA_ "U_CD4_MY13_Gas_Tx" SG_ 973 TsrVlUnitMsgTxt_D_Rq 1;
BA_ "U_CD4_MY13_Diesel_Tx" SG_ 973 TsrVlUnitMsgTxt_D_Rq 1;
BA_ "GenSigStartValue" SG_ 973 TsrVlUnitMsgTxt_D_Rq 2;
BA_ "CrossOver_InfoCAN" SG_ 973 TsrVlUnitMsgTxt_D_Rq 1;
BA_ "GenSigSendType" SG_ 973 TsrVlUnitMsgTxt_D_Rq 3;
BA_ "U_V36X_MY18_5_Hev_Tx" SG_ 973 TsrVLim2MsgTxt_D_Rq 1;
BA_ "U_V36X_MY18_5_Gas_Tx" SG_ 973 TsrVLim2MsgTxt_D_Rq 1;
BA_ "U_V36X_MY19_5_Diesel_Tx" SG_ 973 TsrVLim2MsgTxt_D_Rq 1;
BA_ "U_V36X_MY18_5_Diesel_Tx" SG_ 973 TsrVLim2MsgTxt_D_Rq 1;
BA_ "U_V408_MY18_Diesel_Tx" SG_ 973 TsrVLim2MsgTxt_D_Rq 1;
BA_ "U_V408_MY18_Gas_Tx" SG_ 973 TsrVLim2MsgTxt_D_Rq 1;
BA_ "U_S550_MY18_Gas_Tx" SG_ 973 TsrVLim2MsgTxt_D_Rq 1;
BA_ "U_P552_MY18_Gas_Tx" SG_ 973 TsrVLim2MsgTxt_D_Rq 1;
BA_ "U_CD43_MY17_Gas_Tx" SG_ 973 TsrVLim2MsgTxt_D_Rq 1;
BA_ "U_CD42_MY16_Gas_Tx" SG_ 973 TsrVLim2MsgTxt_D_Rq 1;
BA_ "U_CD42_MY16_Diesel_Tx" SG_ 973 TsrVLim2MsgTxt_D_Rq 1;
BA_ "U_C489_MY17_Gas_Tx" SG_ 973 TsrVLim2MsgTxt_D_Rq 1;
BA_ "U_V36X_MY16_5_Diesel_Tx" SG_ 973 TsrVLim2MsgTxt_D_Rq 1;
BA_ "U_CD4_MY17_Phev_Tx" SG_ 973 TsrVLim2MsgTxt_D_Rq 1;
BA_ "U_CD4_MY17_Hev_Tx" SG_ 973 TsrVLim2MsgTxt_D_Rq 1;
BA_ "U_CD4_MY17_Gas_Tx" SG_ 973 TsrVLim2MsgTxt_D_Rq 1;
BA_ "U_CD4_MY17_Diesel_Tx" SG_ 973 TsrVLim2MsgTxt_D_Rq 1;
BA_ "U_CD4_MY14_Phev_Tx" SG_ 973 TsrVLim2MsgTxt_D_Rq 1;
BA_ "U_CD4_MY14_Hev_Tx" SG_ 973 TsrVLim2MsgTxt_D_Rq 1;
BA_ "U_CD4_MY14_Gas_Tx" SG_ 973 TsrVLim2MsgTxt_D_Rq 1;
BA_ "U_CD4_MY14_Diesel_Tx" SG_ 973 TsrVLim2MsgTxt_D_Rq 1;
BA_ "U_UP375_MY18_Diesel_Tx" SG_ 973 TsrVLim2MsgTxt_D_Rq 1;
BA_ "U_UP375_MY18_Gas_Tx" SG_ 973 TsrVLim2MsgTxt_D_Rq 1;
BA_ "U_C489_MY14_Gas_Tx" SG_ 973 TsrVLim2MsgTxt_D_Rq 1;
BA_ "U_CD42_MY15_Gas_Tx" SG_ 973 TsrVLim2MsgTxt_D_Rq 1;
BA_ "U_CD42_MY15_Diesel_Tx" SG_ 973 TsrVLim2MsgTxt_D_Rq 1;
BA_ "U_CD4_MY13_Phev_Tx" SG_ 973 TsrVLim2MsgTxt_D_Rq 1;
BA_ "U_CD4_MY13_Hev_Tx" SG_ 973 TsrVLim2MsgTxt_D_Rq 1;
BA_ "U_CD4_MY13_Gas_Tx" SG_ 973 TsrVLim2MsgTxt_D_Rq 1;
BA_ "U_CD4_MY13_Diesel_Tx" SG_ 973 TsrVLim2MsgTxt_D_Rq 1;
BA_ "GenSigStartValue" SG_ 973 TsrVLim2MsgTxt_D_Rq 255;
BA_ "CrossOver_InfoCAN" SG_ 973 TsrVLim2MsgTxt_D_Rq 1;
BA_ "GenSigSendType" SG_ 973 TsrVLim2MsgTxt_D_Rq 3;
BA_ "U_V36X_MY18_5_Hev_Tx" SG_ 973 TsrVLim1MsgTxt_D_Rq 1;
BA_ "U_V36X_MY18_5_Gas_Tx" SG_ 973 TsrVLim1MsgTxt_D_Rq 1;
BA_ "U_V36X_MY19_5_Diesel_Tx" SG_ 973 TsrVLim1MsgTxt_D_Rq 1;
BA_ "U_V36X_MY18_5_Diesel_Tx" SG_ 973 TsrVLim1MsgTxt_D_Rq 1;
BA_ "U_V408_MY18_Diesel_Tx" SG_ 973 TsrVLim1MsgTxt_D_Rq 1;
BA_ "U_V408_MY18_Gas_Tx" SG_ 973 TsrVLim1MsgTxt_D_Rq 1;
BA_ "U_S550_MY18_Gas_Tx" SG_ 973 TsrVLim1MsgTxt_D_Rq 1;
BA_ "U_P552_MY18_Gas_Tx" SG_ 973 TsrVLim1MsgTxt_D_Rq 1;
BA_ "U_CD43_MY17_Gas_Tx" SG_ 973 TsrVLim1MsgTxt_D_Rq 1;
BA_ "U_CD42_MY16_Gas_Tx" SG_ 973 TsrVLim1MsgTxt_D_Rq 1;
BA_ "U_CD42_MY16_Diesel_Tx" SG_ 973 TsrVLim1MsgTxt_D_Rq 1;
BA_ "U_C489_MY17_Gas_Tx" SG_ 973 TsrVLim1MsgTxt_D_Rq 1;
BA_ "U_V36X_MY16_5_Diesel_Tx" SG_ 973 TsrVLim1MsgTxt_D_Rq 1;
BA_ "U_CD4_MY17_Phev_Tx" SG_ 973 TsrVLim1MsgTxt_D_Rq 1;
BA_ "U_CD4_MY17_Hev_Tx" SG_ 973 TsrVLim1MsgTxt_D_Rq 1;
BA_ "U_CD4_MY17_Gas_Tx" SG_ 973 TsrVLim1MsgTxt_D_Rq 1;
BA_ "U_CD4_MY17_Diesel_Tx" SG_ 973 TsrVLim1MsgTxt_D_Rq 1;
BA_ "U_CD4_MY14_Phev_Tx" SG_ 973 TsrVLim1MsgTxt_D_Rq 1;
BA_ "U_CD4_MY14_Hev_Tx" SG_ 973 TsrVLim1MsgTxt_D_Rq 1;
BA_ "U_CD4_MY14_Gas_Tx" SG_ 973 TsrVLim1MsgTxt_D_Rq 1;
BA_ "U_CD4_MY14_Diesel_Tx" SG_ 973 TsrVLim1MsgTxt_D_Rq 1;
BA_ "U_UP375_MY18_Diesel_Tx" SG_ 973 TsrVLim1MsgTxt_D_Rq 1;
BA_ "U_UP375_MY18_Gas_Tx" SG_ 973 TsrVLim1MsgTxt_D_Rq 1;
BA_ "U_C489_MY14_Gas_Tx" SG_ 973 TsrVLim1MsgTxt_D_Rq 1;
BA_ "U_CD42_MY15_Gas_Tx" SG_ 973 TsrVLim1MsgTxt_D_Rq 1;
BA_ "U_CD42_MY15_Diesel_Tx" SG_ 973 TsrVLim1MsgTxt_D_Rq 1;
BA_ "U_CD4_MY13_Phev_Tx" SG_ 973 TsrVLim1MsgTxt_D_Rq 1;
BA_ "U_CD4_MY13_Hev_Tx" SG_ 973 TsrVLim1MsgTxt_D_Rq 1;
BA_ "U_CD4_MY13_Gas_Tx" SG_ 973 TsrVLim1MsgTxt_D_Rq 1;
BA_ "U_CD4_MY13_Diesel_Tx" SG_ 973 TsrVLim1MsgTxt_D_Rq 1;
BA_ "GenSigStartValue" SG_ 973 TsrVLim1MsgTxt_D_Rq 255;
BA_ "CrossOver_InfoCAN" SG_ 973 TsrVLim1MsgTxt_D_Rq 1;
BA_ "GenSigSendType" SG_ 973 TsrVLim1MsgTxt_D_Rq 3;
BA_ "U_V36X_MY18_5_Hev_Tx" SG_ 973 TsrVl2StatMsgTxt_D_Rq 1;
BA_ "U_V36X_MY18_5_Gas_Tx" SG_ 973 TsrVl2StatMsgTxt_D_Rq 1;
BA_ "U_V36X_MY19_5_Diesel_Tx" SG_ 973 TsrVl2StatMsgTxt_D_Rq 1;
BA_ "U_V36X_MY18_5_Diesel_Tx" SG_ 973 TsrVl2StatMsgTxt_D_Rq 1;
BA_ "U_V408_MY18_Diesel_Tx" SG_ 973 TsrVl2StatMsgTxt_D_Rq 1;
BA_ "U_V408_MY18_Gas_Tx" SG_ 973 TsrVl2StatMsgTxt_D_Rq 1;
BA_ "U_S550_MY18_Gas_Tx" SG_ 973 TsrVl2StatMsgTxt_D_Rq 1;
BA_ "U_P552_MY18_Gas_Tx" SG_ 973 TsrVl2StatMsgTxt_D_Rq 1;
BA_ "U_CD43_MY17_Gas_Tx" SG_ 973 TsrVl2StatMsgTxt_D_Rq 1;
BA_ "U_CD42_MY16_Gas_Tx" SG_ 973 TsrVl2StatMsgTxt_D_Rq 1;
BA_ "U_CD42_MY16_Diesel_Tx" SG_ 973 TsrVl2StatMsgTxt_D_Rq 1;
BA_ "U_C489_MY17_Gas_Tx" SG_ 973 TsrVl2StatMsgTxt_D_Rq 1;
BA_ "U_V36X_MY16_5_Diesel_Tx" SG_ 973 TsrVl2StatMsgTxt_D_Rq 1;
BA_ "U_CD4_MY17_Phev_Tx" SG_ 973 TsrVl2StatMsgTxt_D_Rq 1;
BA_ "U_CD4_MY17_Hev_Tx" SG_ 973 TsrVl2StatMsgTxt_D_Rq 1;
BA_ "U_CD4_MY17_Gas_Tx" SG_ 973 TsrVl2StatMsgTxt_D_Rq 1;
BA_ "U_CD4_MY17_Diesel_Tx" SG_ 973 TsrVl2StatMsgTxt_D_Rq 1;
BA_ "U_CD4_MY14_Phev_Tx" SG_ 973 TsrVl2StatMsgTxt_D_Rq 1;
BA_ "U_CD4_MY14_Hev_Tx" SG_ 973 TsrVl2StatMsgTxt_D_Rq 1;
BA_ "U_CD4_MY14_Gas_Tx" SG_ 973 TsrVl2StatMsgTxt_D_Rq 1;
BA_ "U_CD4_MY14_Diesel_Tx" SG_ 973 TsrVl2StatMsgTxt_D_Rq 1;
BA_ "U_UP375_MY18_Diesel_Tx" SG_ 973 TsrVl2StatMsgTxt_D_Rq 1;
BA_ "U_UP375_MY18_Gas_Tx" SG_ 973 TsrVl2StatMsgTxt_D_Rq 1;
BA_ "U_C489_MY14_Gas_Tx" SG_ 973 TsrVl2StatMsgTxt_D_Rq 1;
BA_ "U_CD42_MY15_Gas_Tx" SG_ 973 TsrVl2StatMsgTxt_D_Rq 1;
BA_ "U_CD42_MY15_Diesel_Tx" SG_ 973 TsrVl2StatMsgTxt_D_Rq 1;
BA_ "U_CD4_MY13_Phev_Tx" SG_ 973 TsrVl2StatMsgTxt_D_Rq 1;
BA_ "U_CD4_MY13_Hev_Tx" SG_ 973 TsrVl2StatMsgTxt_D_Rq 1;
BA_ "U_CD4_MY13_Gas_Tx" SG_ 973 TsrVl2StatMsgTxt_D_Rq 1;
BA_ "U_CD4_MY13_Diesel_Tx" SG_ 973 TsrVl2StatMsgTxt_D_Rq 1;
BA_ "CrossOver_InfoCAN" SG_ 973 TsrVl2StatMsgTxt_D_Rq 1;
BA_ "GenSigSendType" SG_ 973 TsrVl2StatMsgTxt_D_Rq 3;
BA_ "U_V36X_MY18_5_Hev_Tx" SG_ 973 TsrVl1StatMsgTxt_D_Rq 1;
BA_ "U_V36X_MY18_5_Gas_Tx" SG_ 973 TsrVl1StatMsgTxt_D_Rq 1;
BA_ "U_V36X_MY19_5_Diesel_Tx" SG_ 973 TsrVl1StatMsgTxt_D_Rq 1;
BA_ "U_V36X_MY18_5_Diesel_Tx" SG_ 973 TsrVl1StatMsgTxt_D_Rq 1;
BA_ "U_V408_MY18_Diesel_Tx" SG_ 973 TsrVl1StatMsgTxt_D_Rq 1;
BA_ "U_V408_MY18_Gas_Tx" SG_ 973 TsrVl1StatMsgTxt_D_Rq 1;
BA_ "U_S550_MY18_Gas_Tx" SG_ 973 TsrVl1StatMsgTxt_D_Rq 1;
BA_ "U_P552_MY18_Gas_Tx" SG_ 973 TsrVl1StatMsgTxt_D_Rq 1;
BA_ "U_CD43_MY17_Gas_Tx" SG_ 973 TsrVl1StatMsgTxt_D_Rq 1;
BA_ "U_CD42_MY16_Gas_Tx" SG_ 973 TsrVl1StatMsgTxt_D_Rq 1;
BA_ "U_CD42_MY16_Diesel_Tx" SG_ 973 TsrVl1StatMsgTxt_D_Rq 1;
BA_ "U_C489_MY17_Gas_Tx" SG_ 973 TsrVl1StatMsgTxt_D_Rq 1;
BA_ "U_V36X_MY16_5_Diesel_Tx" SG_ 973 TsrVl1StatMsgTxt_D_Rq 1;
BA_ "U_CD4_MY17_Phev_Tx" SG_ 973 TsrVl1StatMsgTxt_D_Rq 1;
BA_ "U_CD4_MY17_Hev_Tx" SG_ 973 TsrVl1StatMsgTxt_D_Rq 1;
BA_ "U_CD4_MY17_Gas_Tx" SG_ 973 TsrVl1StatMsgTxt_D_Rq 1;
BA_ "U_CD4_MY17_Diesel_Tx" SG_ 973 TsrVl1StatMsgTxt_D_Rq 1;
BA_ "U_CD4_MY14_Phev_Tx" SG_ 973 TsrVl1StatMsgTxt_D_Rq 1;
BA_ "U_CD4_MY14_Hev_Tx" SG_ 973 TsrVl1StatMsgTxt_D_Rq 1;
BA_ "U_CD4_MY14_Gas_Tx" SG_ 973 TsrVl1StatMsgTxt_D_Rq 1;
BA_ "U_CD4_MY14_Diesel_Tx" SG_ 973 TsrVl1StatMsgTxt_D_Rq 1;
BA_ "U_UP375_MY18_Diesel_Tx" SG_ 973 TsrVl1StatMsgTxt_D_Rq 1;
BA_ "U_UP375_MY18_Gas_Tx" SG_ 973 TsrVl1StatMsgTxt_D_Rq 1;
BA_ "U_C489_MY14_Gas_Tx" SG_ 973 TsrVl1StatMsgTxt_D_Rq 1;
BA_ "U_CD42_MY15_Gas_Tx" SG_ 973 TsrVl1StatMsgTxt_D_Rq 1;
BA_ "U_CD42_MY15_Diesel_Tx" SG_ 973 TsrVl1StatMsgTxt_D_Rq 1;
BA_ "U_CD4_MY13_Phev_Tx" SG_ 973 TsrVl1StatMsgTxt_D_Rq 1;
BA_ "U_CD4_MY13_Hev_Tx" SG_ 973 TsrVl1StatMsgTxt_D_Rq 1;
BA_ "U_CD4_MY13_Gas_Tx" SG_ 973 TsrVl1StatMsgTxt_D_Rq 1;
BA_ "U_CD4_MY13_Diesel_Tx" SG_ 973 TsrVl1StatMsgTxt_D_Rq 1;
BA_ "CrossOver_InfoCAN" SG_ 973 TsrVl1StatMsgTxt_D_Rq 1;
BA_ "GenSigSendType" SG_ 973 TsrVl1StatMsgTxt_D_Rq 3;
BA_ "U_V36X_MY18_5_Hev_Tx" SG_ 973 TsrStatMsgTxt_D_Rq 1;
BA_ "U_V36X_MY18_5_Gas_Tx" SG_ 973 TsrStatMsgTxt_D_Rq 1;
BA_ "U_V36X_MY19_5_Diesel_Tx" SG_ 973 TsrStatMsgTxt_D_Rq 1;
BA_ "U_V36X_MY18_5_Diesel_Tx" SG_ 973 TsrStatMsgTxt_D_Rq 1;
BA_ "U_V408_MY18_Diesel_Tx" SG_ 973 TsrStatMsgTxt_D_Rq 1;
BA_ "U_V408_MY18_Gas_Tx" SG_ 973 TsrStatMsgTxt_D_Rq 1;
BA_ "U_S550_MY18_Gas_Tx" SG_ 973 TsrStatMsgTxt_D_Rq 1;
BA_ "U_P552_MY18_Gas_Tx" SG_ 973 TsrStatMsgTxt_D_Rq 1;
BA_ "U_CD43_MY17_Gas_Tx" SG_ 973 TsrStatMsgTxt_D_Rq 1;
BA_ "U_CD42_MY16_Gas_Tx" SG_ 973 TsrStatMsgTxt_D_Rq 1;
BA_ "U_CD42_MY16_Diesel_Tx" SG_ 973 TsrStatMsgTxt_D_Rq 1;
BA_ "U_C489_MY17_Gas_Tx" SG_ 973 TsrStatMsgTxt_D_Rq 1;
BA_ "U_V36X_MY16_5_Diesel_Tx" SG_ 973 TsrStatMsgTxt_D_Rq 1;
BA_ "U_CD4_MY17_Phev_Tx" SG_ 973 TsrStatMsgTxt_D_Rq 1;
BA_ "U_CD4_MY17_Hev_Tx" SG_ 973 TsrStatMsgTxt_D_Rq 1;
BA_ "U_CD4_MY17_Gas_Tx" SG_ 973 TsrStatMsgTxt_D_Rq 1;
BA_ "U_CD4_MY17_Diesel_Tx" SG_ 973 TsrStatMsgTxt_D_Rq 1;
BA_ "U_CD4_MY14_Phev_Tx" SG_ 973 TsrStatMsgTxt_D_Rq 1;
BA_ "U_CD4_MY14_Hev_Tx" SG_ 973 TsrStatMsgTxt_D_Rq 1;
BA_ "U_CD4_MY14_Gas_Tx" SG_ 973 TsrStatMsgTxt_D_Rq 1;
BA_ "U_CD4_MY14_Diesel_Tx" SG_ 973 TsrStatMsgTxt_D_Rq 1;
BA_ "U_UP375_MY18_Diesel_Tx" SG_ 973 TsrStatMsgTxt_D_Rq 1;
BA_ "U_UP375_MY18_Gas_Tx" SG_ 973 TsrStatMsgTxt_D_Rq 1;
BA_ "U_C489_MY14_Gas_Tx" SG_ 973 TsrStatMsgTxt_D_Rq 1;
BA_ "U_CD42_MY15_Gas_Tx" SG_ 973 TsrStatMsgTxt_D_Rq 1;
BA_ "U_CD42_MY15_Diesel_Tx" SG_ 973 TsrStatMsgTxt_D_Rq 1;
BA_ "U_CD4_MY13_Phev_Tx" SG_ 973 TsrStatMsgTxt_D_Rq 1;
BA_ "U_CD4_MY13_Hev_Tx" SG_ 973 TsrStatMsgTxt_D_Rq 1;
BA_ "U_CD4_MY13_Gas_Tx" SG_ 973 TsrStatMsgTxt_D_Rq 1;
BA_ "U_CD4_MY13_Diesel_Tx" SG_ 973 TsrStatMsgTxt_D_Rq 1;
BA_ "CrossOver_InfoCAN" SG_ 973 TsrStatMsgTxt_D_Rq 1;
BA_ "GenSigSendType" SG_ 973 TsrStatMsgTxt_D_Rq 3;
BA_ "U_V36X_MY18_5_Hev_Tx" SG_ 973 TsrOvtkStatMsgTxt_D_Rq 1;
BA_ "U_V36X_MY18_5_Gas_Tx" SG_ 973 TsrOvtkStatMsgTxt_D_Rq 1;
BA_ "U_V36X_MY19_5_Diesel_Tx" SG_ 973 TsrOvtkStatMsgTxt_D_Rq 1;
BA_ "U_V36X_MY18_5_Diesel_Tx" SG_ 973 TsrOvtkStatMsgTxt_D_Rq 1;
BA_ "U_V408_MY18_Diesel_Tx" SG_ 973 TsrOvtkStatMsgTxt_D_Rq 1;
BA_ "U_V408_MY18_Gas_Tx" SG_ 973 TsrOvtkStatMsgTxt_D_Rq 1;
BA_ "U_S550_MY18_Gas_Tx" SG_ 973 TsrOvtkStatMsgTxt_D_Rq 1;
BA_ "U_P552_MY18_Gas_Tx" SG_ 973 TsrOvtkStatMsgTxt_D_Rq 1;
BA_ "U_CD43_MY17_Gas_Tx" SG_ 973 TsrOvtkStatMsgTxt_D_Rq 1;
BA_ "U_CD42_MY16_Gas_Tx" SG_ 973 TsrOvtkStatMsgTxt_D_Rq 1;
BA_ "U_CD42_MY16_Diesel_Tx" SG_ 973 TsrOvtkStatMsgTxt_D_Rq 1;
BA_ "U_C489_MY17_Gas_Tx" SG_ 973 TsrOvtkStatMsgTxt_D_Rq 1;
BA_ "U_V36X_MY16_5_Diesel_Tx" SG_ 973 TsrOvtkStatMsgTxt_D_Rq 1;
BA_ "U_CD4_MY17_Phev_Tx" SG_ 973 TsrOvtkStatMsgTxt_D_Rq 1;
BA_ "U_CD4_MY17_Hev_Tx" SG_ 973 TsrOvtkStatMsgTxt_D_Rq 1;
BA_ "U_CD4_MY17_Gas_Tx" SG_ 973 TsrOvtkStatMsgTxt_D_Rq 1;
BA_ "U_CD4_MY17_Diesel_Tx" SG_ 973 TsrOvtkStatMsgTxt_D_Rq 1;
BA_ "U_CD4_MY14_Phev_Tx" SG_ 973 TsrOvtkStatMsgTxt_D_Rq 1;
BA_ "U_CD4_MY14_Hev_Tx" SG_ 973 TsrOvtkStatMsgTxt_D_Rq 1;
BA_ "U_CD4_MY14_Gas_Tx" SG_ 973 TsrOvtkStatMsgTxt_D_Rq 1;
BA_ "U_CD4_MY14_Diesel_Tx" SG_ 973 TsrOvtkStatMsgTxt_D_Rq 1;
BA_ "U_UP375_MY18_Diesel_Tx" SG_ 973 TsrOvtkStatMsgTxt_D_Rq 1;
BA_ "U_UP375_MY18_Gas_Tx" SG_ 973 TsrOvtkStatMsgTxt_D_Rq 1;
BA_ "U_C489_MY14_Gas_Tx" SG_ 973 TsrOvtkStatMsgTxt_D_Rq 1;
BA_ "U_CD42_MY15_Gas_Tx" SG_ 973 TsrOvtkStatMsgTxt_D_Rq 1;
BA_ "U_CD42_MY15_Diesel_Tx" SG_ 973 TsrOvtkStatMsgTxt_D_Rq 1;
BA_ "U_CD4_MY13_Phev_Tx" SG_ 973 TsrOvtkStatMsgTxt_D_Rq 1;
BA_ "U_CD4_MY13_Hev_Tx" SG_ 973 TsrOvtkStatMsgTxt_D_Rq 1;
BA_ "U_CD4_MY13_Gas_Tx" SG_ 973 TsrOvtkStatMsgTxt_D_Rq 1;
BA_ "U_CD4_MY13_Diesel_Tx" SG_ 973 TsrOvtkStatMsgTxt_D_Rq 1;
BA_ "CrossOver_InfoCAN" SG_ 973 TsrOvtkStatMsgTxt_D_Rq 1;
BA_ "GenSigSendType" SG_ 973 TsrOvtkStatMsgTxt_D_Rq 3;
BA_ "U_V36X_MY18_5_Hev_Tx" SG_ 973 TsrMsgTxt_D_Rq 1;
BA_ "U_V36X_MY18_5_Gas_Tx" SG_ 973 TsrMsgTxt_D_Rq 1;
BA_ "U_V363E_N_MY19_5_20_Diesel_Tx" SG_ 973 TsrMsgTxt_D_Rq 1;
BA_ "U_V363E_N_MY19_5_20_Gas_Tx" SG_ 973 TsrMsgTxt_D_Rq 1;
BA_ "U_V36X_MY19_5_Diesel_Tx" SG_ 973 TsrMsgTxt_D_Rq 1;
BA_ "U_V36X_MY18_5_Diesel_Tx" SG_ 973 TsrMsgTxt_D_Rq 1;
BA_ "U_V408_MY18_Diesel_Tx" SG_ 973 TsrMsgTxt_D_Rq 1;
BA_ "U_V408_MY18_Gas_Tx" SG_ 973 TsrMsgTxt_D_Rq 1;
BA_ "U_S550_MY18_Gas_Tx" SG_ 973 TsrMsgTxt_D_Rq 1;
BA_ "U_P552_MY18_Gas_Tx" SG_ 973 TsrMsgTxt_D_Rq 1;
BA_ "U_CD43_MY17_Gas_Tx" SG_ 973 TsrMsgTxt_D_Rq 1;
BA_ "U_CD42_MY16_Gas_Tx" SG_ 973 TsrMsgTxt_D_Rq 1;
BA_ "U_CD42_MY16_Diesel_Tx" SG_ 973 TsrMsgTxt_D_Rq 1;
BA_ "U_C489_MY17_Gas_Tx" SG_ 973 TsrMsgTxt_D_Rq 1;
BA_ "U_V36X_MY16_5_Diesel_Tx" SG_ 973 TsrMsgTxt_D_Rq 1;
BA_ "U_CD4_MY17_Phev_Tx" SG_ 973 TsrMsgTxt_D_Rq 1;
BA_ "U_CD4_MY17_Hev_Tx" SG_ 973 TsrMsgTxt_D_Rq 1;
BA_ "U_CD4_MY17_Gas_Tx" SG_ 973 TsrMsgTxt_D_Rq 1;
BA_ "U_CD4_MY17_Diesel_Tx" SG_ 973 TsrMsgTxt_D_Rq 1;
BA_ "U_CD4_MY14_Phev_Tx" SG_ 973 TsrMsgTxt_D_Rq 1;
BA_ "U_CD4_MY14_Hev_Tx" SG_ 973 TsrMsgTxt_D_Rq 1;
BA_ "U_CD4_MY14_Gas_Tx" SG_ 973 TsrMsgTxt_D_Rq 1;
BA_ "U_CD4_MY14_Diesel_Tx" SG_ 973 TsrMsgTxt_D_Rq 1;
BA_ "U_UP375_MY18_Diesel_Tx" SG_ 973 TsrMsgTxt_D_Rq 1;
BA_ "U_UP375_MY18_Gas_Tx" SG_ 973 TsrMsgTxt_D_Rq 1;
BA_ "U_C489_MY14_Gas_Tx" SG_ 973 TsrMsgTxt_D_Rq 1;
BA_ "U_CD42_MY15_Gas_Tx" SG_ 973 TsrMsgTxt_D_Rq 1;
BA_ "U_CD42_MY15_Diesel_Tx" SG_ 973 TsrMsgTxt_D_Rq 1;
BA_ "U_CD4_MY13_Phev_Tx" SG_ 973 TsrMsgTxt_D_Rq 1;
BA_ "U_CD4_MY13_Hev_Tx" SG_ 973 TsrMsgTxt_D_Rq 1;
BA_ "U_CD4_MY13_Gas_Tx" SG_ 973 TsrMsgTxt_D_Rq 1;
BA_ "U_CD4_MY13_Diesel_Tx" SG_ 973 TsrMsgTxt_D_Rq 1;
BA_ "GenSigStartValue" SG_ 973 TsrMsgTxt_D_Rq 1;
BA_ "CrossOver_InfoCAN" SG_ 973 TsrMsgTxt_D_Rq 1;
BA_ "GenSigSendType" SG_ 973 TsrMsgTxt_D_Rq 3;
BA_ "U_V36X_MY19_5_Diesel_Tx" SG_ 979 LatCtlRampType_D_Rq 1;
BA_ "U_S550_MY18_Gas_Tx" SG_ 979 LatCtlRampType_D_Rq 1;
BA_ "U_P552_MY18_Gas_Tx" SG_ 979 LatCtlRampType_D_Rq 1;
BA_ "U_CD42_MY19_Gas_Rx" SG_ 979 LatCtlRampType_D_Rq 1;
BA_ "U_CD42_MY19_Diesel_Rx" SG_ 979 LatCtlRampType_D_Rq 1;
BA_ "U_V36X_MY19_5_Diesel_Tx" SG_ 979 LatCtlPrecision_D_Rq 1;
BA_ "U_S550_MY18_Gas_Tx" SG_ 979 LatCtlPrecision_D_Rq 1;
BA_ "U_P552_MY18_Gas_Tx" SG_ 979 LatCtlPrecision_D_Rq 1;
BA_ "U_CD42_MY19_Gas_Rx" SG_ 979 LatCtlPrecision_D_Rq 1;
BA_ "U_CD42_MY19_Diesel_Rx" SG_ 979 LatCtlPrecision_D_Rq 1;
BA_ "U_V36X_MY19_5_Diesel_Tx" SG_ 979 LatCtlPathOffst_L_Actl 1;
BA_ "U_S550_MY18_Gas_Tx" SG_ 979 LatCtlPathOffst_L_Actl 1;
BA_ "U_P552_MY18_Gas_Tx" SG_ 979 LatCtlPathOffst_L_Actl 1;
BA_ "U_CD42_MY19_Gas_Rx" SG_ 979 LatCtlPathOffst_L_Actl 1;
BA_ "U_CD42_MY19_Diesel_Rx" SG_ 979 LatCtlPathOffst_L_Actl 1;
BA_ "GenSigStartValue" SG_ 979 LatCtlPathOffst_L_Actl 512;
BA_ "U_V36X_MY19_5_Diesel_Tx" SG_ 979 LatCtlPath_An_Actl 1;
BA_ "U_S550_MY18_Gas_Tx" SG_ 979 LatCtlPath_An_Actl 1;
BA_ "U_P552_MY18_Gas_Tx" SG_ 979 LatCtlPath_An_Actl 1;
BA_ "U_CD42_MY19_Gas_Rx" SG_ 979 LatCtlPath_An_Actl 1;
BA_ "U_CD42_MY19_Diesel_Rx" SG_ 979 LatCtlPath_An_Actl 1;
BA_ "GenSigStartValue" SG_ 979 LatCtlPath_An_Actl 100;
BA_ "U_V36X_MY19_5_Diesel_Tx" SG_ 979 LatCtlCurv_NoRate_Actl 1;
BA_ "U_S550_MY18_Gas_Tx" SG_ 979 LatCtlCurv_NoRate_Actl 1;
BA_ "U_P552_MY18_Gas_Tx" SG_ 979 LatCtlCurv_NoRate_Actl 1;
BA_ "U_CD42_MY19_Gas_Rx" SG_ 979 LatCtlCurv_NoRate_Actl 1;
BA_ "U_CD42_MY19_Diesel_Rx" SG_ 979 LatCtlCurv_NoRate_Actl 1;
BA_ "GenSigStartValue" SG_ 979 LatCtlCurv_NoRate_Actl 4096;
BA_ "U_V36X_MY19_5_Diesel_Tx" SG_ 979 LatCtlCurv_No_Actl 1;
BA_ "U_S550_MY18_Gas_Tx" SG_ 979 LatCtlCurv_No_Actl 1;
BA_ "U_P552_MY18_Gas_Tx" SG_ 979 LatCtlCurv_No_Actl 1;
BA_ "U_CD42_MY19_Gas_Rx" SG_ 979 LatCtlCurv_No_Actl 1;
BA_ "U_CD42_MY19_Diesel_Rx" SG_ 979 LatCtlCurv_No_Actl 1;
BA_ "GenSigStartValue" SG_ 979 LatCtlCurv_No_Actl 1000;
BA_ "U_V36X_MY19_5_Diesel_Tx" SG_ 979 LatCtl_D_Rq 1;
BA_ "U_S550_MY18_Gas_Tx" SG_ 979 LatCtl_D_Rq 1;
BA_ "U_P552_MY18_Gas_Tx" SG_ 979 LatCtl_D_Rq 1;
BA_ "U_CD42_MY19_Gas_Rx" SG_ 979 LatCtl_D_Rq 1;
BA_ "U_CD42_MY19_Diesel_Rx" SG_ 979 LatCtl_D_Rq 1;
BA_ "U_V36X_MY19_5_Diesel_Tx" SG_ 979 HandsOffCnfm_B_Rq 1;
BA_ "U_S550_MY18_Gas_Tx" SG_ 979 HandsOffCnfm_B_Rq 1;
BA_ "U_U55x_MY18_Gas_Tx" SG_ 979 HandsOffCnfm_B_Rq 1;
BA_ "U_P552_MY18_Gas_Tx" SG_ 979 HandsOffCnfm_B_Rq 1;
BA_ "U_V36X_MY18_5_Hev_Rx" SG_ 979 HandsOffCnfm_B_Rq 1;
BA_ "U_V36X_MY18_5_Gas_Rx" SG_ 979 HandsOffCnfm_B_Rq 1;
BA_ "U_CD42_MY19_Gas_Rx" SG_ 979 HandsOffCnfm_B_Rq 1;
BA_ "U_CD42_MY19_Diesel_Rx" SG_ 979 HandsOffCnfm_B_Rq 1;
BA_ "U_V363E_N_MY19_5_20_Diesel_Rx" SG_ 979 HandsOffCnfm_B_Rq 1;
BA_ "U_V363E_N_MY19_5_20_Gas_Rx" SG_ 979 HandsOffCnfm_B_Rq 1;
BA_ "U_V36X_MY19_5_Diesel_Rx" SG_ 979 HandsOffCnfm_B_Rq 1;
BA_ "U_V36X_MY18_5_Diesel_Rx" SG_ 979 HandsOffCnfm_B_Rq 1;
BA_ "GenSigSendType" SG_ 985 AdbHiBeamKeepOff_D_Rq 3;
BA_ "GenSigSendType" SG_ 985 AdbDividedRoad_B_Stat 3;
BA_ "GenSigSendType" SG_ 985 AdbRampingV_D_Rq 3;
BA_ "GenSigSendType" SG_ 985 AdbLampOnOff_D_Rq 3;
BA_ "U_V36X_MY19_5_Diesel_Tx" SG_ 985 DasAlrtInfo_D_Dsply 1;
BA_ "U_S550_MY18_Gas_Tx" SG_ 985 DasAlrtInfo_D_Dsply 1;
BA_ "U_P552_MY18_Gas_Tx" SG_ 985 DasAlrtInfo_D_Dsply 1;
BA_ "GenSigSendType" SG_ 985 DasAlrtInfo_D_Dsply 3;
BA_ "U_V36X_MY19_5_Diesel_Tx" SG_ 985 IaccVLimUnit_D_Rq 1;
BA_ "U_S550_MY18_Gas_Tx" SG_ 985 IaccVLimUnit_D_Rq 1;
BA_ "U_P552_MY18_Gas_Tx" SG_ 985 IaccVLimUnit_D_Rq 1;
BA_ "GenSigStartValue" SG_ 985 IaccVLimUnit_D_Rq 3;
BA_ "GenSigSendType" SG_ 985 IaccVLimUnit_D_Rq 3;
BA_ "U_V36X_MY19_5_Diesel_Tx" SG_ 985 IaccVLim_D_Rq 1;
BA_ "U_S550_MY18_Gas_Tx" SG_ 985 IaccVLim_D_Rq 1;
BA_ "U_P552_MY18_Gas_Tx" SG_ 985 IaccVLim_D_Rq 1;
BA_ "GenSigStartValue" SG_ 985 IaccVLim_D_Rq 254;
BA_ "GenSigSendType" SG_ 985 IaccVLim_D_Rq 3;
BA_ "U_V36X_MY18_5_Hev_Tx" SG_ 985 IsaVLimUnit_D_Rq 1;
BA_ "U_V36X_MY18_5_Gas_Tx" SG_ 985 IsaVLimUnit_D_Rq 1;
BA_ "U_V36X_MY19_5_Diesel_Tx" SG_ 985 IsaVLimUnit_D_Rq 1;
BA_ "U_V36X_MY18_5_Diesel_Tx" SG_ 985 IsaVLimUnit_D_Rq 1;
BA_ "U_V408_MY18_Diesel_Tx" SG_ 985 IsaVLimUnit_D_Rq 1;
BA_ "U_V408_MY18_Gas_Tx" SG_ 985 IsaVLimUnit_D_Rq 1;
BA_ "U_S550_MY18_Gas_Tx" SG_ 985 IsaVLimUnit_D_Rq 1;
BA_ "U_P552_MY18_Gas_Tx" SG_ 985 IsaVLimUnit_D_Rq 1;
BA_ "U_CD42_MY16_Gas_Tx" SG_ 985 IsaVLimUnit_D_Rq 1;
BA_ "U_CD42_MY16_Diesel_Tx" SG_ 985 IsaVLimUnit_D_Rq 1;
BA_ "U_V36X_MY16_5_Diesel_Tx" SG_ 985 IsaVLimUnit_D_Rq 1;
BA_ "U_CD4_MY17_Phev_Tx" SG_ 985 IsaVLimUnit_D_Rq 1;
BA_ "U_CD4_MY17_Hev_Tx" SG_ 985 IsaVLimUnit_D_Rq 1;
BA_ "U_CD4_MY17_Gas_Tx" SG_ 985 IsaVLimUnit_D_Rq 1;
BA_ "U_CD4_MY17_Diesel_Tx" SG_ 985 IsaVLimUnit_D_Rq 1;
BA_ "U_CD4_MY14_Phev_Tx" SG_ 985 IsaVLimUnit_D_Rq 1;
BA_ "U_CD4_MY14_Hev_Tx" SG_ 985 IsaVLimUnit_D_Rq 1;
BA_ "U_CD4_MY14_Gas_Tx" SG_ 985 IsaVLimUnit_D_Rq 1;
BA_ "U_CD4_MY14_Diesel_Tx" SG_ 985 IsaVLimUnit_D_Rq 1;
BA_ "U_UP375_MY18_Diesel_Tx" SG_ 985 IsaVLimUnit_D_Rq 1;
BA_ "U_UP375_MY18_Gas_Tx" SG_ 985 IsaVLimUnit_D_Rq 1;
BA_ "U_CD42_MY15_Gas_Tx" SG_ 985 IsaVLimUnit_D_Rq 1;
BA_ "U_CD42_MY15_Diesel_Tx" SG_ 985 IsaVLimUnit_D_Rq 1;
BA_ "U_CD4_MY13_Phev_Tx" SG_ 985 IsaVLimUnit_D_Rq 1;
BA_ "U_CD4_MY13_Hev_Tx" SG_ 985 IsaVLimUnit_D_Rq 1;
BA_ "U_CD4_MY13_Gas_Tx" SG_ 985 IsaVLimUnit_D_Rq 1;
BA_ "U_CD4_MY13_Diesel_Tx" SG_ 985 IsaVLimUnit_D_Rq 1;
BA_ "GenSigSendType" SG_ 985 IsaVLimUnit_D_Rq 3;
BA_ "U_V36X_MY18_5_Hev_Tx" SG_ 985 IsaVLim_D_Rq 1;
BA_ "U_V36X_MY18_5_Gas_Tx" SG_ 985 IsaVLim_D_Rq 1;
BA_ "U_V36X_MY19_5_Diesel_Tx" SG_ 985 IsaVLim_D_Rq 1;
BA_ "U_V36X_MY18_5_Diesel_Tx" SG_ 985 IsaVLim_D_Rq 1;
BA_ "U_V408_MY18_Diesel_Tx" SG_ 985 IsaVLim_D_Rq 1;
BA_ "U_V408_MY18_Gas_Tx" SG_ 985 IsaVLim_D_Rq 1;
BA_ "U_S550_MY18_Gas_Tx" SG_ 985 IsaVLim_D_Rq 1;
BA_ "U_P552_MY18_Gas_Tx" SG_ 985 IsaVLim_D_Rq 1;
BA_ "U_CD42_MY16_Gas_Tx" SG_ 985 IsaVLim_D_Rq 1;
BA_ "U_CD42_MY16_Diesel_Tx" SG_ 985 IsaVLim_D_Rq 1;
BA_ "U_V36X_MY16_5_Diesel_Tx" SG_ 985 IsaVLim_D_Rq 1;
BA_ "U_CD4_MY17_Phev_Tx" SG_ 985 IsaVLim_D_Rq 1;
BA_ "U_CD4_MY17_Hev_Tx" SG_ 985 IsaVLim_D_Rq 1;
BA_ "U_CD4_MY17_Gas_Tx" SG_ 985 IsaVLim_D_Rq 1;
BA_ "U_CD4_MY17_Diesel_Tx" SG_ 985 IsaVLim_D_Rq 1;
BA_ "U_CD4_MY14_Phev_Tx" SG_ 985 IsaVLim_D_Rq 1;
BA_ "U_CD4_MY14_Hev_Tx" SG_ 985 IsaVLim_D_Rq 1;
BA_ "U_CD4_MY14_Gas_Tx" SG_ 985 IsaVLim_D_Rq 1;
BA_ "U_CD4_MY14_Diesel_Tx" SG_ 985 IsaVLim_D_Rq 1;
BA_ "U_UP375_MY18_Diesel_Tx" SG_ 985 IsaVLim_D_Rq 1;
BA_ "U_UP375_MY18_Gas_Tx" SG_ 985 IsaVLim_D_Rq 1;
BA_ "U_CD42_MY15_Gas_Tx" SG_ 985 IsaVLim_D_Rq 1;
BA_ "U_CD42_MY15_Diesel_Tx" SG_ 985 IsaVLim_D_Rq 1;
BA_ "U_CD4_MY13_Phev_Tx" SG_ 985 IsaVLim_D_Rq 1;
BA_ "U_CD4_MY13_Hev_Tx" SG_ 985 IsaVLim_D_Rq 1;
BA_ "U_CD4_MY13_Gas_Tx" SG_ 985 IsaVLim_D_Rq 1;
BA_ "U_CD4_MY13_Diesel_Tx" SG_ 985 IsaVLim_D_Rq 1;
BA_ "GenSigStartValue" SG_ 985 IsaVLim_D_Rq 254;
BA_ "GenSigSendType" SG_ 985 IsaVLim_D_Rq 3;
BA_ "U_S550_MY18_Gas_Tx" SG_ 983 EsaEnbl_D2_Rq 1;
BA_ "U_CD42_MY19_Gas_Rx" SG_ 983 EsaEnbl_D2_Rq 1;
BA_ "U_CD42_MY19_Diesel_Rx" SG_ 983 EsaEnbl_D2_Rq 1;
BA_ "U_V36X_MY19_5_Diesel_Tx" SG_ 983 CmbbObjRelLong_V_Actl 1;
BA_ "U_S550_MY18_Gas_Tx" SG_ 983 CmbbObjRelLong_V_Actl 1;
BA_ "U_P552_MY18_Gas_Tx" SG_ 983 CmbbObjRelLong_V_Actl 1;
BA_ "U_CD42_MY19_Gas_Rx" SG_ 983 CmbbObjRelLong_V_Actl 1;
BA_ "U_CD42_MY19_Diesel_Rx" SG_ 983 CmbbObjRelLong_V_Actl 1;
BA_ "GenSigStartValue" SG_ 983 CmbbObjRelLong_V_Actl 1022;
BA_ "U_V36X_MY19_5_Diesel_Tx" SG_ 983 CmbbObjRelLat_V_Actl 1;
BA_ "U_S550_MY18_Gas_Tx" SG_ 983 CmbbObjRelLat_V_Actl 1;
BA_ "U_P552_MY18_Gas_Tx" SG_ 983 CmbbObjRelLat_V_Actl 1;
BA_ "U_CD42_MY19_Gas_Rx" SG_ 983 CmbbObjRelLat_V_Actl 1;
BA_ "U_CD42_MY19_Diesel_Rx" SG_ 983 CmbbObjRelLat_V_Actl 1;
BA_ "GenSigStartValue" SG_ 983 CmbbObjRelLat_V_Actl 510;
BA_ "U_V36X_MY19_5_Diesel_Tx" SG_ 983 CmbbObjDistLong_L_Actl 1;
BA_ "U_S550_MY18_Gas_Tx" SG_ 983 CmbbObjDistLong_L_Actl 1;
BA_ "U_P552_MY18_Gas_Tx" SG_ 983 CmbbObjDistLong_L_Actl 1;
BA_ "U_CD42_MY19_Gas_Rx" SG_ 983 CmbbObjDistLong_L_Actl 1;
BA_ "U_CD42_MY19_Diesel_Rx" SG_ 983 CmbbObjDistLong_L_Actl 1;
BA_ "GenSigStartValue" SG_ 983 CmbbObjDistLong_L_Actl 1022;
BA_ "U_V36X_MY19_5_Diesel_Tx" SG_ 983 CmbbObjDistLat_L_Actl 1;
BA_ "U_S550_MY18_Gas_Tx" SG_ 983 CmbbObjDistLat_L_Actl 1;
BA_ "U_P552_MY18_Gas_Tx" SG_ 983 CmbbObjDistLat_L_Actl 1;
BA_ "U_CD42_MY19_Gas_Rx" SG_ 983 CmbbObjDistLat_L_Actl 1;
BA_ "U_CD42_MY19_Diesel_Rx" SG_ 983 CmbbObjDistLat_L_Actl 1;
BA_ "GenSigStartValue" SG_ 983 CmbbObjDistLat_L_Actl 510;
BA_ "U_V36X_MY19_5_Diesel_Tx" SG_ 983 CmbbObjConfdnc_D_Stat 1;
BA_ "U_S550_MY18_Gas_Tx" SG_ 983 CmbbObjConfdnc_D_Stat 1;
BA_ "U_P552_MY18_Gas_Tx" SG_ 983 CmbbObjConfdnc_D_Stat 1;
BA_ "U_CD42_MY19_Gas_Rx" SG_ 983 CmbbObjConfdnc_D_Stat 1;
BA_ "U_CD42_MY19_Diesel_Rx" SG_ 983 CmbbObjConfdnc_D_Stat 1;
BA_ "U_V36X_MY19_5_Diesel_Tx" SG_ 983 CmbbObjColl_T_Actl 1;
BA_ "U_S550_MY18_Gas_Tx" SG_ 983 CmbbObjColl_T_Actl 1;
BA_ "U_P552_MY18_Gas_Tx" SG_ 983 CmbbObjColl_T_Actl 1;
BA_ "U_CD42_MY19_Gas_Rx" SG_ 983 CmbbObjColl_T_Actl 1;
BA_ "U_CD42_MY19_Diesel_Rx" SG_ 983 CmbbObjColl_T_Actl 1;
BA_ "GenSigStartValue" SG_ 983 CmbbObjColl_T_Actl 126;
BA_ "U_V36X_MY19_5_Diesel_Tx" SG_ 983 CmbbObjClass_D_Stat 1;
BA_ "U_S550_MY18_Gas_Tx" SG_ 983 CmbbObjClass_D_Stat 1;
BA_ "U_P552_MY18_Gas_Tx" SG_ 983 CmbbObjClass_D_Stat 1;
BA_ "U_CD42_MY19_Gas_Rx" SG_ 983 CmbbObjClass_D_Stat 1;
BA_ "U_CD42_MY19_Diesel_Rx" SG_ 983 CmbbObjClass_D_Stat 1;
BA_ "U_S550_MY18_Gas_Tx" SG_ 962 AdbMde3_D_Rq 1;
BA_ "GenSigSendType" SG_ 962 AdbMde3_D_Rq 3;
BA_ "U_S550_MY18_Gas_Tx" SG_ 962 AdbIntns3_D_Rq 1;
BA_ "GenSigSendType" SG_ 962 AdbIntns3_D_Rq 3;
BA_ "U_S550_MY18_Gas_Tx" SG_ 962 AdbBrdr3Up_An_Rq 1;
BA_ "GenSigStartValue" SG_ 962 AdbBrdr3Up_An_Rq 400;
BA_ "U_S550_MY18_Gas_Tx" SG_ 962 AdbBrdr3Right_An_Rq 1;
BA_ "GenSigStartValue" SG_ 962 AdbBrdr3Right_An_Rq 1000;
BA_ "U_S550_MY18_Gas_Tx" SG_ 962 AdbBrdr3Low_An_Rq 1;
BA_ "GenSigStartValue" SG_ 962 AdbBrdr3Low_An_Rq 400;
BA_ "U_S550_MY18_Gas_Tx" SG_ 962 AdbBrdr3Left_An_Rq 1;
BA_ "GenSigStartValue" SG_ 962 AdbBrdr3Left_An_Rq 1000;
BA_ "U_S550_MY18_Gas_Tx" SG_ 962 AdbBrdr3CritRigh_T_Stat 1;
BA_ "U_S550_MY18_Gas_Tx" SG_ 962 AdbBrdr3CritLeft_T_Stat 1;
BA_ "U_S550_MY18_Gas_Tx" SG_ 961 AdbMde2_D_Rq 1;
BA_ "GenSigSendType" SG_ 961 AdbMde2_D_Rq 3;
BA_ "U_S550_MY18_Gas_Tx" SG_ 961 AdbIntns2_D_Rq 1;
BA_ "GenSigSendType" SG_ 961 AdbIntns2_D_Rq 3;
BA_ "U_S550_MY18_Gas_Tx" SG_ 961 AdbBrdr2Up_An_Rq 1;
BA_ "GenSigStartValue" SG_ 961 AdbBrdr2Up_An_Rq 400;
BA_ "U_S550_MY18_Gas_Tx" SG_ 961 AdbBrdr2Right_An_Rq 1;
BA_ "GenSigStartValue" SG_ 961 AdbBrdr2Right_An_Rq 1000;
BA_ "U_S550_MY18_Gas_Tx" SG_ 961 AdbBrdr2Low_An_Rq 1;
BA_ "GenSigStartValue" SG_ 961 AdbBrdr2Low_An_Rq 400;
BA_ "U_S550_MY18_Gas_Tx" SG_ 961 AdbBrdr2Left_An_Rq 1;
BA_ "GenSigStartValue" SG_ 961 AdbBrdr2Left_An_Rq 1000;
BA_ "U_S550_MY18_Gas_Tx" SG_ 961 AdbBrdr2CritRigh_T_Stat 1;
BA_ "U_S550_MY18_Gas_Tx" SG_ 961 AdbBrdr2CritLeft_T_Stat 1;
BA_ "U_S550_MY18_Gas_Rx" SG_ 1122 GpsHsphLongEast_D_Actl 1;
BA_ "U_P552_MY18_Gas_Rx" SG_ 1122 GpsHsphLongEast_D_Actl 1;
BA_ "CrossOver_InfoCAN" SG_ 1122 GpsHsphLongEast_D_Actl 1;
BA_ "U_S550_MY18_Gas_Rx" SG_ 1122 GpsHsphLattSth_D_Actl 1;
BA_ "U_P552_MY18_Gas_Rx" SG_ 1122 GpsHsphLattSth_D_Actl 1;
BA_ "CrossOver_InfoCAN" SG_ 1122 GpsHsphLattSth_D_Actl 1;
BA_ "U_V408_MY18_Diesel_Rx" SG_ 1122 GPS_Longitude_Minutes 1;
BA_ "U_V408_MY18_Gas_Rx" SG_ 1122 GPS_Longitude_Minutes 1;
BA_ "U_S550_MY18_Gas_Rx" SG_ 1122 GPS_Longitude_Minutes 1;
BA_ "U_U55x_MY18_Gas_Rx" SG_ 1122 GPS_Longitude_Minutes 1;
BA_ "U_P552_MY18_Gas_Rx" SG_ 1122 GPS_Longitude_Minutes 1;
BA_ "CrossOver_InfoCAN" SG_ 1122 GPS_Longitude_Minutes 1;
BA_ "U_V408_MY18_Diesel_Rx" SG_ 1122 GPS_Longitude_Min_dec 1;
BA_ "U_V408_MY18_Gas_Rx" SG_ 1122 GPS_Longitude_Min_dec 1;
BA_ "U_S550_MY18_Gas_Rx" SG_ 1122 GPS_Longitude_Min_dec 1;
BA_ "U_U55x_MY18_Gas_Rx" SG_ 1122 GPS_Longitude_Min_dec 1;
BA_ "U_P552_MY18_Gas_Rx" SG_ 1122 GPS_Longitude_Min_dec 1;
BA_ "CrossOver_InfoCAN" SG_ 1122 GPS_Longitude_Min_dec 1;
BA_ "U_V408_MY18_Diesel_Rx" SG_ 1122 GPS_Longitude_Degrees 1;
BA_ "U_V408_MY18_Gas_Rx" SG_ 1122 GPS_Longitude_Degrees 1;
BA_ "U_S550_MY18_Gas_Rx" SG_ 1122 GPS_Longitude_Degrees 1;
BA_ "U_U55x_MY18_Gas_Rx" SG_ 1122 GPS_Longitude_Degrees 1;
BA_ "U_P552_MY18_Gas_Rx" SG_ 1122 GPS_Longitude_Degrees 1;
BA_ "GenSigStartValue" SG_ 1122 GPS_Longitude_Degrees 179;
BA_ "CrossOver_InfoCAN" SG_ 1122 GPS_Longitude_Degrees 1;
BA_ "U_V408_MY18_Diesel_Rx" SG_ 1122 GPS_Latitude_Minutes 1;
BA_ "U_V408_MY18_Gas_Rx" SG_ 1122 GPS_Latitude_Minutes 1;
BA_ "U_S550_MY18_Gas_Rx" SG_ 1122 GPS_Latitude_Minutes 1;
BA_ "U_U55x_MY18_Gas_Rx" SG_ 1122 GPS_Latitude_Minutes 1;
BA_ "U_P552_MY18_Gas_Rx" SG_ 1122 GPS_Latitude_Minutes 1;
BA_ "CrossOver_InfoCAN" SG_ 1122 GPS_Latitude_Minutes 1;
BA_ "U_V408_MY18_Diesel_Rx" SG_ 1122 GPS_Latitude_Min_dec 1;
BA_ "U_V408_MY18_Gas_Rx" SG_ 1122 GPS_Latitude_Min_dec 1;
BA_ "U_S550_MY18_Gas_Rx" SG_ 1122 GPS_Latitude_Min_dec 1;
BA_ "U_U55x_MY18_Gas_Rx" SG_ 1122 GPS_Latitude_Min_dec 1;
BA_ "U_P552_MY18_Gas_Rx" SG_ 1122 GPS_Latitude_Min_dec 1;
BA_ "CrossOver_InfoCAN" SG_ 1122 GPS_Latitude_Min_dec 1;
BA_ "U_V408_MY18_Diesel_Rx" SG_ 1122 GPS_Latitude_Degrees 1;
BA_ "U_V408_MY18_Gas_Rx" SG_ 1122 GPS_Latitude_Degrees 1;
BA_ "U_S550_MY18_Gas_Rx" SG_ 1122 GPS_Latitude_Degrees 1;
BA_ "U_U55x_MY18_Gas_Rx" SG_ 1122 GPS_Latitude_Degrees 1;
BA_ "U_P552_MY18_Gas_Rx" SG_ 1122 GPS_Latitude_Degrees 1;
BA_ "CrossOver_InfoCAN" SG_ 1122 GPS_Latitude_Degrees 1;
BA_ "GenSigStartValue" SG_ 976 SrpHghtRight_L_Actl 256;
BA_ "GenSigStartValue" SG_ 976 SrpHghtLeft_L_Actl 256;
BA_ "GenSigSendType" SG_ 1080 AutoTowActv_B_Stat 3;
BA_ "U_P552_MY18_Gas_Rx" SG_ 1080 HeadLghtHiPrmsn_D_Stat_UB 1;
BA_ "U_U55x_MY18_Gas_Rx" SG_ 1080 HeadLghtHiPrmsn_D_Stat_UB 1;
BA_ "U_V408_MY18_Gas_Rx" SG_ 1080 HeadLghtHiPrmsn_D_Stat_UB 1;
BA_ "U_V408_MY18_Diesel_Rx" SG_ 1080 HeadLghtHiPrmsn_D_Stat_UB 1;
BA_ "U_V36X_MY18_5_Diesel_Rx" SG_ 1080 HeadLghtHiPrmsn_D_Stat_UB 1;
BA_ "U_V36X_MY19_5_Diesel_Rx" SG_ 1080 HeadLghtHiPrmsn_D_Stat_UB 1;
BA_ "U_CD42_MY19_Diesel_Rx" SG_ 1080 HeadLghtHiPrmsn_D_Stat_UB 1;
BA_ "U_CD42_MY19_Gas_Rx" SG_ 1080 HeadLghtHiPrmsn_D_Stat_UB 1;
BA_ "U_V36X_MY18_5_Gas_Rx" SG_ 1080 HeadLghtHiPrmsn_D_Stat_UB 1;
BA_ "U_V36X_MY18_5_Hev_Rx" SG_ 1080 HeadLghtHiPrmsn_D_Stat_UB 1;
BA_ "GenSigSendType" SG_ 1080 HeadLghtHiPrmsn_D_Stat 3;
BA_ "GenSigStartValue" SG_ 1080 HeadLghtHiPrmsn_D_Stat 3;
BA_ "U_P552_MY18_Gas_Rx" SG_ 1080 HeadLghtHiPrmsn_D_Stat 1;
BA_ "U_U55x_MY18_Gas_Rx" SG_ 1080 HeadLghtHiPrmsn_D_Stat 1;
BA_ "U_V408_MY18_Gas_Rx" SG_ 1080 HeadLghtHiPrmsn_D_Stat 1;
BA_ "U_V408_MY18_Diesel_Rx" SG_ 1080 HeadLghtHiPrmsn_D_Stat 1;
BA_ "U_V36X_MY18_5_Diesel_Rx" SG_ 1080 HeadLghtHiPrmsn_D_Stat 1;
BA_ "U_V36X_MY19_5_Diesel_Rx" SG_ 1080 HeadLghtHiPrmsn_D_Stat 1;
BA_ "U_V363E_N_MY19_5_20_Gas_Rx" SG_ 1080 HeadLghtHiPrmsn_D_Stat 1;
BA_ "U_V363E_N_MY19_5_20_Diesel_Rx" SG_ 1080 HeadLghtHiPrmsn_D_Stat 1;
BA_ "U_CD42_MY19_Diesel_Rx" SG_ 1080 HeadLghtHiPrmsn_D_Stat 1;
BA_ "U_CD42_MY19_Gas_Rx" SG_ 1080 HeadLghtHiPrmsn_D_Stat 1;
BA_ "U_V36X_MY18_5_Gas_Rx" SG_ 1080 HeadLghtHiPrmsn_D_Stat 1;
BA_ "U_V36X_MY18_5_Hev_Rx" SG_ 1080 HeadLghtHiPrmsn_D_Stat 1;
BA_ "U_U55x_MY18_Gas_Tx" SG_ 1080 HeadLghtHiPrmsn_D_Stat 1;
BA_ "GenSigStartValue" SG_ 1053 VehStab_D_Stat 14;
BA_ "U_V36X_MY16_5_Diesel_Rx" SG_ 1053 VehStab_D_Stat 1;
BA_ "U_V36X_MY18_5_Diesel_Rx" SG_ 1053 VehStab_D_Stat 1;
BA_ "U_CD43_MY16_Gas_Tx" SG_ 1053 VehStab_D_Stat 1;
BA_ "U_CD4_MY17_Diesel_Tx" SG_ 1053 VehStab_D_Stat 1;
BA_ "U_CD4_MY17_Gas_Tx" SG_ 1053 VehStab_D_Stat 1;
BA_ "U_V36X_MY16_5_Diesel_Tx" SG_ 1053 VehStab_D_Stat 1;
BA_ "U_CD43_MY17_Gas_Tx" SG_ 1053 VehStab_D_Stat 1;
BA_ "U_P552_MY18_Gas_Tx" SG_ 1053 VehStab_D_Stat 1;
BA_ "U_U55x_MY18_Gas_Tx" SG_ 1053 VehStab_D_Stat 1;
BA_ "U_V408_MY18_Gas_Tx" SG_ 1053 VehStab_D_Stat 1;
BA_ "U_V408_MY18_Diesel_Tx" SG_ 1053 VehStab_D_Stat 1;
BA_ "U_V36X_MY18_5_Diesel_Tx" SG_ 1053 VehStab_D_Stat 1;
BA_ "U_P552_MY18_5_Gas_Tx" SG_ 1053 VehStab_D_Stat 1;
BA_ "U_P552_MY18_5_Diesel_Tx" SG_ 1053 VehStab_D_Stat 1;
BA_ "U_V36X_MY19_5_Diesel_Tx" SG_ 1053 VehStab_D_Stat 1;
BA_ "U_U55x_MY18_Gas_Tx" SG_ 1102 SelDrvMdePos12_D_Stat 1;
BA_ "GenSigStartValue" SG_ 1102 SelDrvMdePos12_D_Stat 31;
BA_ "GenSigSendType" SG_ 1102 SelDrvMdePos12_D_Stat 3;
BA_ "U_U55x_MY18_Gas_Tx" SG_ 1102 SelDrvMdePos11_D_Stat 1;
BA_ "GenSigStartValue" SG_ 1102 SelDrvMdePos11_D_Stat 31;
BA_ "GenSigSendType" SG_ 1102 SelDrvMdePos11_D_Stat 3;
BA_ "U_U55x_MY18_Gas_Tx" SG_ 1102 SelDrvMdePos10_D_Stat 1;
BA_ "GenSigStartValue" SG_ 1102 SelDrvMdePos10_D_Stat 31;
BA_ "GenSigSendType" SG_ 1102 SelDrvMdePos10_D_Stat 3;
BA_ "U_U55x_MY18_Gas_Tx" SG_ 1102 SelDrvMdePos09_D_Stat 1;
BA_ "GenSigStartValue" SG_ 1102 SelDrvMdePos09_D_Stat 31;
BA_ "GenSigSendType" SG_ 1102 SelDrvMdePos09_D_Stat 3;
BA_ "U_U55x_MY18_Gas_Tx" SG_ 1102 SelDrvMdePos08_D_Stat 1;
BA_ "GenSigStartValue" SG_ 1102 SelDrvMdePos08_D_Stat 31;
BA_ "GenSigSendType" SG_ 1102 SelDrvMdePos08_D_Stat 3;
BA_ "U_U55x_MY18_Gas_Tx" SG_ 1102 SelDrvMdePos07_D_Stat 1;
BA_ "GenSigStartValue" SG_ 1102 SelDrvMdePos07_D_Stat 31;
BA_ "GenSigSendType" SG_ 1102 SelDrvMdePos07_D_Stat 3;
BA_ "U_U55x_MY18_Gas_Tx" SG_ 1102 SelDrvMdePos06_D_Stat 1;
BA_ "GenSigStartValue" SG_ 1102 SelDrvMdePos06_D_Stat 31;
BA_ "GenSigSendType" SG_ 1102 SelDrvMdePos06_D_Stat 3;
BA_ "U_U55x_MY18_Gas_Tx" SG_ 1102 SelDrvMdePos05_D_Stat 1;
BA_ "GenSigStartValue" SG_ 1102 SelDrvMdePos05_D_Stat 31;
BA_ "GenSigSendType" SG_ 1102 SelDrvMdePos05_D_Stat 3;
BA_ "U_U55x_MY18_Gas_Tx" SG_ 1102 SelDrvMdePos04_D_Stat 1;
BA_ "GenSigStartValue" SG_ 1102 SelDrvMdePos04_D_Stat 31;
BA_ "GenSigSendType" SG_ 1102 SelDrvMdePos04_D_Stat 3;
BA_ "U_U55x_MY18_Gas_Tx" SG_ 1102 SelDrvMdePos03_D_Stat 1;
BA_ "GenSigStartValue" SG_ 1102 SelDrvMdePos03_D_Stat 31;
BA_ "GenSigSendType" SG_ 1102 SelDrvMdePos03_D_Stat 3;
BA_ "U_U55x_MY18_Gas_Tx" SG_ 1102 SelDrvMdePos02_D_Stat 1;
BA_ "GenSigStartValue" SG_ 1102 SelDrvMdePos02_D_Stat 31;
BA_ "GenSigSendType" SG_ 1102 SelDrvMdePos02_D_Stat 3;
BA_ "U_U55x_MY18_Gas_Tx" SG_ 1102 SelDrvMdePos01_D_Stat 1;
BA_ "GenSigStartValue" SG_ 1102 SelDrvMdePos01_D_Stat 31;
BA_ "GenSigSendType" SG_ 1102 SelDrvMdePos01_D_Stat 3;
BA_ "GenSigSendType" SG_ 1056 SelDrvMde_D_Stat 3;
BA_ "U_U55x_MY18_Gas_Tx" SG_ 1056 SelDrvMde_D_Stat 1;
BA_ "U_V408_MY18_Gas_Tx" SG_ 1056 SelDrvMde_D_Stat 1;
BA_ "U_V408_MY18_Diesel_Tx" SG_ 1056 SelDrvMde_D_Stat 1;
BA_ "U_U55x_MY18_Gas_Tx" SG_ 1056 ActvDrvMde_D2_Stat 1;
BA_ "GenSigStartValue" SG_ 1056 ActvDrvMde_D2_Stat 31;
BA_ "GenSigSendType" SG_ 1056 ActvDrvMde_D2_Stat 3;
BA_ "GenSigSendType" SG_ 1056 SelDrvMde_D2_Rq 3;
BA_ "U_U55x_MY18_Gas_Tx" SG_ 1056 SelDrvMde_D2_Rq 1;
BA_ "GenSigSendType" SG_ 1056 SelDrvMdePos12_B_Avail 3;
BA_ "U_U55x_MY18_Gas_Tx" SG_ 1056 SelDrvMdePos12_B_Avail 1;
BA_ "GenSigSendType" SG_ 1056 SelDrvMdePos11_B_Avail 3;
BA_ "U_U55x_MY18_Gas_Tx" SG_ 1056 SelDrvMdePos11_B_Avail 1;
BA_ "GenSigSendType" SG_ 1056 SelDrvMdePos10_B_Avail 3;
BA_ "U_U55x_MY18_Gas_Tx" SG_ 1056 SelDrvMdePos10_B_Avail 1;
BA_ "GenSigSendType" SG_ 1056 SelDrvMdePos09_B_Avail 3;
BA_ "U_U55x_MY18_Gas_Tx" SG_ 1056 SelDrvMdePos09_B_Avail 1;
BA_ "GenSigSendType" SG_ 1056 SelDrvMdePos08_B_Avail 3;
BA_ "U_U55x_MY18_Gas_Tx" SG_ 1056 SelDrvMdePos08_B_Avail 1;
BA_ "GenSigSendType" SG_ 1056 SelDrvMdePos07_B_Avail 3;
BA_ "U_U55x_MY18_Gas_Tx" SG_ 1056 SelDrvMdePos07_B_Avail 1;
BA_ "GenSigSendType" SG_ 1056 SelDrvMdePos06_B_Avail 3;
BA_ "U_U55x_MY18_Gas_Tx" SG_ 1056 SelDrvMdePos06_B_Avail 1;
BA_ "GenSigSendType" SG_ 1056 SelDrvMdePos05_B_Avail 3;
BA_ "U_U55x_MY18_Gas_Tx" SG_ 1056 SelDrvMdePos05_B_Avail 1;
BA_ "GenSigSendType" SG_ 1056 SelDrvMdePos04_B_Avail 3;
BA_ "U_U55x_MY18_Gas_Tx" SG_ 1056 SelDrvMdePos04_B_Avail 1;
BA_ "GenSigSendType" SG_ 1056 SelDrvMdePos03_B_Avail 3;
BA_ "U_U55x_MY18_Gas_Tx" SG_ 1056 SelDrvMdePos03_B_Avail 1;
BA_ "GenSigSendType" SG_ 1056 SelDrvMdePos02_B_Avail 3;
BA_ "U_U55x_MY18_Gas_Tx" SG_ 1056 SelDrvMdePos02_B_Avail 1;
BA_ "GenSigSendType" SG_ 1056 SelDrvMdePos01_B_Avail 3;
BA_ "U_U55x_MY18_Gas_Tx" SG_ 1056 SelDrvMdePos01_B_Avail 1;
BA_ "U_V408_MY18_Diesel_Tx" SG_ 1056 SelDrvMdePt_D_Rq 1;
BA_ "U_V408_MY18_Gas_Tx" SG_ 1056 SelDrvMdePt_D_Rq 1;
BA_ "U_U55x_MY18_Gas_Tx" SG_ 1056 SelDrvMdePt_D_Rq 1;
BA_ "GenSigSendType" SG_ 1056 SelDrvMdePt_D_Rq 3;
BA_ "U_V408_MY18_Diesel_Tx" SG_ 1056 SelDrvMdeMsgTxt_D_Rq 1;
BA_ "U_V408_MY18_Gas_Tx" SG_ 1056 SelDrvMdeMsgTxt_D_Rq 1;
BA_ "U_U55x_MY18_Gas_Tx" SG_ 1056 SelDrvMdeMsgTxt_D_Rq 1;
BA_ "GenSigSendType" SG_ 1056 SelDrvMdeMsgTxt_D_Rq 3;
BA_ "U_V408_MY18_Diesel_Tx" SG_ 1056 AwdMde_D_RqBrk 1;
BA_ "U_V408_MY18_Gas_Tx" SG_ 1056 AwdMde_D_RqBrk 1;
BA_ "U_U55x_MY18_Gas_Tx" SG_ 1056 AwdMde_D_RqBrk 1;
BA_ "GenSigStartValue" SG_ 1056 AwdMde_D_RqBrk 5;
BA_ "GenSigSendType" SG_ 1056 AwdMde_D_RqBrk 3;
BA_ "ContentDependant" SG_ 1487 ATCM_GWOnBoardTester 1;
BA_ "GenSigStartValue" SG_ 1487 ATCM_GWOnBoardTester 255;
BA_ "ContentDependant" SG_ 1487 ATCM_GWNMProxy 1;
BA_ "GenSigStartValue" SG_ 1487 ATCM_GWNMProxy 255;
BA_ "ContentDependant" SG_ 1487 ATCM_AutoSarNMReserved4 1;
BA_ "GenSigStartValue" SG_ 1487 ATCM_AutoSarNMReserved4 255;
BA_ "ContentDependant" SG_ 1487 ATCM_AutoSarNMReserved3 1;
BA_ "GenSigStartValue" SG_ 1487 ATCM_AutoSarNMReserved3 255;
BA_ "ContentDependant" SG_ 1487 ATCM_AutoSarNMReserved2 1;
BA_ "GenSigStartValue" SG_ 1487 ATCM_AutoSarNMReserved2 255;
BA_ "ContentDependant" SG_ 1487 ATCM_AutoSarNMReserved1 1;
BA_ "GenSigStartValue" SG_ 1487 ATCM_AutoSarNMReserved1 255;
BA_ "ContentDependant" SG_ 1487 ATCM_AutoSarNMNodeId 1;
BA_ "GenSigStartValue" SG_ 1487 ATCM_AutoSarNMNodeId 207;
BA_ "ContentDependant" SG_ 1487 ATCM_AutoSarNMControl 1;
BA_ "U_U55x_MY18_Gas_Rx" SG_ 1938 TesterPhysicalReqATCM 1;
BA_ "U_P552_MY18_Gas_Rx" SG_ 1938 TesterPhysicalReqATCM 1;
BA_ "U_P552_MY17_Gas_Rx" SG_ 1938 TesterPhysicalReqATCM 1;
BA_ "U_UP375_MY15_Diesel_Rx" SG_ 1938 TesterPhysicalReqATCM 1;
BA_ "U_UP375_MY15_Gas_Rx" SG_ 1938 TesterPhysicalReqATCM 1;
BA_ "U_U502_MY16_Gas_Rx" SG_ 1938 TesterPhysicalReqATCM 1;
BA_ "GenSigSendType" SG_ 1938 TesterPhysicalReqATCM 3;
BA_ "U_U55x_MY18_Gas_Tx" SG_ 1120 RearDiffLck_D_RqDrv 1;
BA_ "U_P552_MY18_Gas_Tx" SG_ 1120 RearDiffLck_D_RqDrv 1;
BA_ "U_P552_MY17_Gas_Tx" SG_ 1120 RearDiffLck_D_RqDrv 1;
BA_ "U_P552_MY17_Gas_Rx" SG_ 1120 RearDiffLck_D_RqDrv 1;
BA_ "GenSigStartValue" SG_ 1120 RearDiffLck_D_RqDrv 2;
BA_ "GenSigSendType" SG_ 1120 RearDiffLck_D_RqDrv 3;
BA_ "U_U55x_MY18_Gas_Tx" SG_ 1120 AwdMde_D_RqDrv 1;
BA_ "U_P552_MY18_Gas_Tx" SG_ 1120 AwdMde_D_RqDrv 1;
BA_ "U_P552_MY17_Gas_Tx" SG_ 1120 AwdMde_D_RqDrv 1;
BA_ "U_P552_MY17_Gas_Rx" SG_ 1120 AwdMde_D_RqDrv 1;
BA_ "GenSigStartValue" SG_ 1120 AwdMde_D_RqDrv 5;
BA_ "GenSigSendType" SG_ 1120 AwdMde_D_RqDrv 3;
BA_ "U_U55x_MY18_Gas_Tx" SG_ 1946 TesterPhysicalResATCM 1;
BA_ "U_P552_MY18_Gas_Tx" SG_ 1946 TesterPhysicalResATCM 1;
BA_ "U_P552_MY17_Gas_Tx" SG_ 1946 TesterPhysicalResATCM 1;
BA_ "U_UP375_MY15_Diesel_Tx" SG_ 1946 TesterPhysicalResATCM 1;
BA_ "U_UP375_MY15_Gas_Tx" SG_ 1946 TesterPhysicalResATCM 1;
BA_ "U_U502_MY16_Gas_Tx" SG_ 1946 TesterPhysicalResATCM 1;
BA_ "GenSigSendType" SG_ 1946 TesterPhysicalResATCM 3;
BA_ "GenSigStartValue" SG_ 1110 RstrnMdulePw_D_Falt 1;
BA_ "U_CD4_MY17_Diesel_Rx" SG_ 1110 RstrnMdulePw_D_Falt 1;
BA_ "U_CD4_MY17_Gas_Rx" SG_ 1110 RstrnMdulePw_D_Falt 1;
BA_ "U_CD4_MY17_Hev_Rx" SG_ 1110 RstrnMdulePw_D_Falt 1;
BA_ "U_CD4_MY17_Phev_Rx" SG_ 1110 RstrnMdulePw_D_Falt 1;
BA_ "U_P558_MY17_Diesel_Rx" SG_ 1110 RstrnMdulePw_D_Falt 1;
BA_ "U_C489_MY17_Gas_Rx" SG_ 1110 RstrnMdulePw_D_Falt 1;
BA_ "U_CD43_MY17_Gas_Rx" SG_ 1110 RstrnMdulePw_D_Falt 1;
BA_ "GenSigTimeoutTime_RCM" SG_ 1110 RstrnMdulePw_D_Falt 1500;
BA_ "U_CD42_MY15_Diesel_Rx" SG_ 1073 HMI_HMIMode_St_UB 1;
BA_ "U_CD42_MY15_Gas_Rx" SG_ 1073 HMI_HMIMode_St_UB 1;
BA_ "U_B479_MY17_Gas_Rx" SG_ 1073 HMI_HMIMode_St_UB 1;
BA_ "U_UP375_MY19_Gas_Rx" SG_ 1073 HMI_HMIMode_St_UB 1;
BA_ "U_UP375_MY19_Diesel_Rx" SG_ 1073 HMI_HMIMode_St_UB 1;
BA_ "U_B479_MY17_Diesel_Rx" SG_ 1073 HMI_HMIMode_St_UB 1;
BA_ "U_P558_MY17_Gas_Rx" SG_ 1073 HMI_HMIMode_St_UB 1;
BA_ "U_P558_MY17_Diesel_Rx" SG_ 1073 HMI_HMIMode_St_UB 1;
BA_ "U_V36X_MY16_5_Diesel_Rx" SG_ 1073 HMI_HMIMode_St_UB 1;
BA_ "U_CD42_MY16_Diesel_Rx" SG_ 1073 HMI_HMIMode_St_UB 1;
BA_ "U_CD42_MY16_Gas_Rx" SG_ 1073 HMI_HMIMode_St_UB 1;
BA_ "U_CD43_MY17_Gas_Rx" SG_ 1073 HMI_HMIMode_St_UB 1;
BA_ "U_U55x_MY18_Gas_Rx" SG_ 1073 HMI_HMIMode_St_UB 1;
BA_ "U_V408_MY18_Gas_Rx" SG_ 1073 HMI_HMIMode_St_UB 1;
BA_ "U_V408_MY18_Diesel_Rx" SG_ 1073 HMI_HMIMode_St_UB 1;
BA_ "U_V36X_MY19_Rx" SG_ 1073 HMI_HMIMode_St_UB 1;
BA_ "U_V363E_N_MY19_5_20_Gas_Rx" SG_ 1073 HMI_HMIMode_St_UB 1;
BA_ "U_V363E_N_MY19_5_20_Diesel_Rx" SG_ 1073 HMI_HMIMode_St_UB 1;
BA_ "U_CD42_MY19_Diesel_Rx" SG_ 1073 HMI_HMIMode_St_UB 1;
BA_ "U_CD42_MY19_Gas_Rx" SG_ 1073 HMI_HMIMode_St_UB 1;
BA_ "GenSigSendType" SG_ 1073 HMI_HMIMode_St 3;
BA_ "WakeupSignal" SG_ 1073 HMI_HMIMode_St 1;
BA_ "CrossOver_InfoCAN" SG_ 1073 HMI_HMIMode_St 1;
BA_ "U_CD42_MY15_Diesel_Rx" SG_ 1073 HMI_HMIMode_St 1;
BA_ "U_CD42_MY15_Gas_Rx" SG_ 1073 HMI_HMIMode_St 1;
BA_ "U_B479_MY17_Gas_Rx" SG_ 1073 HMI_HMIMode_St 1;
BA_ "U_UP375_MY19_Gas_Rx" SG_ 1073 HMI_HMIMode_St 1;
BA_ "U_UP375_MY19_Diesel_Rx" SG_ 1073 HMI_HMIMode_St 1;
BA_ "U_B479_MY17_Diesel_Rx" SG_ 1073 HMI_HMIMode_St 1;
BA_ "U_P558_MY17_Gas_Rx" SG_ 1073 HMI_HMIMode_St 1;
BA_ "U_P558_MY17_Diesel_Rx" SG_ 1073 HMI_HMIMode_St 1;
BA_ "U_V36X_MY16_5_Diesel_Rx" SG_ 1073 HMI_HMIMode_St 1;
BA_ "U_CD42_MY16_Diesel_Rx" SG_ 1073 HMI_HMIMode_St 1;
BA_ "U_CD42_MY16_Gas_Rx" SG_ 1073 HMI_HMIMode_St 1;
BA_ "U_CD43_MY17_Gas_Rx" SG_ 1073 HMI_HMIMode_St 1;
BA_ "U_U55x_MY18_Gas_Rx" SG_ 1073 HMI_HMIMode_St 1;
BA_ "U_V408_MY18_Gas_Rx" SG_ 1073 HMI_HMIMode_St 1;
BA_ "U_V408_MY18_Diesel_Rx" SG_ 1073 HMI_HMIMode_St 1;
BA_ "U_V36X_MY19_Rx" SG_ 1073 HMI_HMIMode_St 1;
BA_ "U_V363E_N_MY19_5_20_Gas_Rx" SG_ 1073 HMI_HMIMode_St 1;
BA_ "U_V363E_N_MY19_5_20_Diesel_Rx" SG_ 1073 HMI_HMIMode_St 1;
BA_ "U_CD42_MY19_Diesel_Rx" SG_ 1073 HMI_HMIMode_St 1;
BA_ "U_CD42_MY19_Gas_Rx" SG_ 1073 HMI_HMIMode_St 1;
BA_ "U_P552_MY18_Gas_Rx" SG_ 1073 SteEffort_D_Rq_UB 1;
BA_ "U_P552_MY17_Gas_Rx" SG_ 1073 SteEffort_D_Rq_UB 1;
BA_ "U_S550_MY15_Gas_Rx" SG_ 1073 SteEffort_D_Rq_UB 1;
BA_ "U_P552_MY18_Gas_Rx" SG_ 1073 SteEffort_D_Rq 1;
BA_ "U_P552_MY17_Gas_Rx" SG_ 1073 SteEffort_D_Rq 1;
BA_ "U_S550_MY15_Gas_Rx" SG_ 1073 SteEffort_D_Rq 1;
BA_ "GenSigSendType" SG_ 1073 SteEffort_D_Rq 3;
BA_ "U_CD4_MY13_Diesel_Rx" SG_ 1073 DISPLAY_SPEED_SCALING_UB 1;
BA_ "U_CD4_MY13_Gas_Rx" SG_ 1073 DISPLAY_SPEED_SCALING_UB 1;
BA_ "U_CD4_MY13_Hev_Rx" SG_ 1073 DISPLAY_SPEED_SCALING_UB 1;
BA_ "U_CD4_MY13_Phev_Rx" SG_ 1073 DISPLAY_SPEED_SCALING_UB 1;
BA_ "U_CD42_MY15_Diesel_Rx" SG_ 1073 DISPLAY_SPEED_SCALING_UB 1;
BA_ "U_CD42_MY15_Gas_Rx" SG_ 1073 DISPLAY_SPEED_SCALING_UB 1;
BA_ "U_UP375_MY15_Gas_Rx" SG_ 1073 DISPLAY_SPEED_SCALING_UB 1;
BA_ "U_UP375_MY15_Diesel_Rx" SG_ 1073 DISPLAY_SPEED_SCALING_UB 1;
BA_ "U_CD4_MY14_Diesel_Rx" SG_ 1073 DISPLAY_SPEED_SCALING_UB 1;
BA_ "U_CD4_MY14_Gas_Rx" SG_ 1073 DISPLAY_SPEED_SCALING_UB 1;
BA_ "U_CD4_MY14_Hev_Rx" SG_ 1073 DISPLAY_SPEED_SCALING_UB 1;
BA_ "U_CD4_MY14_Phev_Rx" SG_ 1073 DISPLAY_SPEED_SCALING_UB 1;
BA_ "U_CD4_MY17_Diesel_Rx" SG_ 1073 DISPLAY_SPEED_SCALING_UB 1;
BA_ "U_CD4_MY17_Gas_Rx" SG_ 1073 DISPLAY_SPEED_SCALING_UB 1;
BA_ "U_CD4_MY17_Hev_Rx" SG_ 1073 DISPLAY_SPEED_SCALING_UB 1;
BA_ "U_CD4_MY17_Phev_Rx" SG_ 1073 DISPLAY_SPEED_SCALING_UB 1;
BA_ "U_V36X_MY16_5_Diesel_Rx" SG_ 1073 DISPLAY_SPEED_SCALING_UB 1;
BA_ "U_CD42_MY16_Diesel_Rx" SG_ 1073 DISPLAY_SPEED_SCALING_UB 1;
BA_ "U_CD42_MY16_Gas_Rx" SG_ 1073 DISPLAY_SPEED_SCALING_UB 1;
BA_ "U_CD43_MY17_Gas_Rx" SG_ 1073 DISPLAY_SPEED_SCALING_UB 1;
BA_ "U_U55x_MY18_Gas_Rx" SG_ 1073 DISPLAY_SPEED_SCALING_UB 1;
BA_ "GenSigSendType" SG_ 1073 DISPLAY_SPEED_SCALING 3;
BA_ "CrossOver_InfoCAN" SG_ 1073 DISPLAY_SPEED_SCALING 1;
BA_ "U_CD4_MY13_Diesel_Rx" SG_ 1073 DISPLAY_SPEED_SCALING 1;
BA_ "U_CD4_MY13_Gas_Rx" SG_ 1073 DISPLAY_SPEED_SCALING 1;
BA_ "U_CD4_MY13_Hev_Rx" SG_ 1073 DISPLAY_SPEED_SCALING 1;
BA_ "U_CD4_MY13_Phev_Rx" SG_ 1073 DISPLAY_SPEED_SCALING 1;
BA_ "U_CD42_MY15_Diesel_Rx" SG_ 1073 DISPLAY_SPEED_SCALING 1;
BA_ "U_CD42_MY15_Gas_Rx" SG_ 1073 DISPLAY_SPEED_SCALING 1;
BA_ "U_UP375_MY15_Gas_Rx" SG_ 1073 DISPLAY_SPEED_SCALING 1;
BA_ "U_UP375_MY15_Diesel_Rx" SG_ 1073 DISPLAY_SPEED_SCALING 1;
BA_ "U_CD4_MY14_Diesel_Rx" SG_ 1073 DISPLAY_SPEED_SCALING 1;
BA_ "U_CD4_MY14_Gas_Rx" SG_ 1073 DISPLAY_SPEED_SCALING 1;
BA_ "U_CD4_MY14_Hev_Rx" SG_ 1073 DISPLAY_SPEED_SCALING 1;
BA_ "U_CD4_MY14_Phev_Rx" SG_ 1073 DISPLAY_SPEED_SCALING 1;
BA_ "U_CD4_MY17_Diesel_Rx" SG_ 1073 DISPLAY_SPEED_SCALING 1;
BA_ "U_CD4_MY17_Gas_Rx" SG_ 1073 DISPLAY_SPEED_SCALING 1;
BA_ "U_CD4_MY17_Hev_Rx" SG_ 1073 DISPLAY_SPEED_SCALING 1;
BA_ "U_CD4_MY17_Phev_Rx" SG_ 1073 DISPLAY_SPEED_SCALING 1;
BA_ "U_V36X_MY16_5_Diesel_Rx" SG_ 1073 DISPLAY_SPEED_SCALING 1;
BA_ "U_CD42_MY16_Diesel_Rx" SG_ 1073 DISPLAY_SPEED_SCALING 1;
BA_ "U_CD42_MY16_Gas_Rx" SG_ 1073 DISPLAY_SPEED_SCALING 1;
BA_ "U_CD43_MY17_Gas_Rx" SG_ 1073 DISPLAY_SPEED_SCALING 1;
BA_ "U_U55x_MY18_Gas_Rx" SG_ 1073 DISPLAY_SPEED_SCALING 1;
BA_ "U_CD4_MY13_Diesel_Rx" SG_ 1073 DISPLAY_SPEED_OFFSET_UB 1;
BA_ "U_CD4_MY13_Gas_Rx" SG_ 1073 DISPLAY_SPEED_OFFSET_UB 1;
BA_ "U_CD4_MY13_Hev_Rx" SG_ 1073 DISPLAY_SPEED_OFFSET_UB 1;
BA_ "U_CD4_MY13_Phev_Rx" SG_ 1073 DISPLAY_SPEED_OFFSET_UB 1;
BA_ "U_CD42_MY15_Diesel_Rx" SG_ 1073 DISPLAY_SPEED_OFFSET_UB 1;
BA_ "U_CD42_MY15_Gas_Rx" SG_ 1073 DISPLAY_SPEED_OFFSET_UB 1;
BA_ "U_UP375_MY15_Gas_Rx" SG_ 1073 DISPLAY_SPEED_OFFSET_UB 1;
BA_ "U_UP375_MY15_Diesel_Rx" SG_ 1073 DISPLAY_SPEED_OFFSET_UB 1;
BA_ "U_CD4_MY14_Diesel_Rx" SG_ 1073 DISPLAY_SPEED_OFFSET_UB 1;
BA_ "U_CD4_MY14_Gas_Rx" SG_ 1073 DISPLAY_SPEED_OFFSET_UB 1;
BA_ "U_CD4_MY14_Hev_Rx" SG_ 1073 DISPLAY_SPEED_OFFSET_UB 1;
BA_ "U_CD4_MY14_Phev_Rx" SG_ 1073 DISPLAY_SPEED_OFFSET_UB 1;
BA_ "U_CD4_MY17_Diesel_Rx" SG_ 1073 DISPLAY_SPEED_OFFSET_UB 1;
BA_ "U_CD4_MY17_Gas_Rx" SG_ 1073 DISPLAY_SPEED_OFFSET_UB 1;
BA_ "U_CD4_MY17_Hev_Rx" SG_ 1073 DISPLAY_SPEED_OFFSET_UB 1;
BA_ "U_CD4_MY17_Phev_Rx" SG_ 1073 DISPLAY_SPEED_OFFSET_UB 1;
BA_ "U_V36X_MY16_5_Diesel_Rx" SG_ 1073 DISPLAY_SPEED_OFFSET_UB 1;
BA_ "U_CD42_MY16_Diesel_Rx" SG_ 1073 DISPLAY_SPEED_OFFSET_UB 1;
BA_ "U_CD42_MY16_Gas_Rx" SG_ 1073 DISPLAY_SPEED_OFFSET_UB 1;
BA_ "U_CD43_MY17_Gas_Rx" SG_ 1073 DISPLAY_SPEED_OFFSET_UB 1;
BA_ "U_U55x_MY18_Gas_Rx" SG_ 1073 DISPLAY_SPEED_OFFSET_UB 1;
BA_ "GenSigSendType" SG_ 1073 DISPLAY_SPEED_OFFSET 3;
BA_ "CrossOver_InfoCAN" SG_ 1073 DISPLAY_SPEED_OFFSET 1;
BA_ "U_CD4_MY13_Diesel_Rx" SG_ 1073 DISPLAY_SPEED_OFFSET 1;
BA_ "U_CD4_MY13_Gas_Rx" SG_ 1073 DISPLAY_SPEED_OFFSET 1;
BA_ "U_CD4_MY13_Hev_Rx" SG_ 1073 DISPLAY_SPEED_OFFSET 1;
BA_ "U_CD4_MY13_Phev_Rx" SG_ 1073 DISPLAY_SPEED_OFFSET 1;
BA_ "U_CD42_MY15_Diesel_Rx" SG_ 1073 DISPLAY_SPEED_OFFSET 1;
BA_ "U_CD42_MY15_Gas_Rx" SG_ 1073 DISPLAY_SPEED_OFFSET 1;
BA_ "U_UP375_MY15_Gas_Rx" SG_ 1073 DISPLAY_SPEED_OFFSET 1;
BA_ "U_UP375_MY15_Diesel_Rx" SG_ 1073 DISPLAY_SPEED_OFFSET 1;
BA_ "U_CD4_MY14_Diesel_Rx" SG_ 1073 DISPLAY_SPEED_OFFSET 1;
BA_ "U_CD4_MY14_Gas_Rx" SG_ 1073 DISPLAY_SPEED_OFFSET 1;
BA_ "U_CD4_MY14_Hev_Rx" SG_ 1073 DISPLAY_SPEED_OFFSET 1;
BA_ "U_CD4_MY14_Phev_Rx" SG_ 1073 DISPLAY_SPEED_OFFSET 1;
BA_ "U_CD4_MY17_Diesel_Rx" SG_ 1073 DISPLAY_SPEED_OFFSET 1;
BA_ "U_CD4_MY17_Gas_Rx" SG_ 1073 DISPLAY_SPEED_OFFSET 1;
BA_ "U_CD4_MY17_Hev_Rx" SG_ 1073 DISPLAY_SPEED_OFFSET 1;
BA_ "U_CD4_MY17_Phev_Rx" SG_ 1073 DISPLAY_SPEED_OFFSET 1;
BA_ "U_V36X_MY16_5_Diesel_Rx" SG_ 1073 DISPLAY_SPEED_OFFSET 1;
BA_ "U_CD42_MY16_Diesel_Rx" SG_ 1073 DISPLAY_SPEED_OFFSET 1;
BA_ "U_CD42_MY16_Gas_Rx" SG_ 1073 DISPLAY_SPEED_OFFSET 1;
BA_ "U_CD43_MY17_Gas_Rx" SG_ 1073 DISPLAY_SPEED_OFFSET 1;
BA_ "U_U55x_MY18_Gas_Rx" SG_ 1073 DISPLAY_SPEED_OFFSET 1;
BA_ "GenSigSendType" SG_ 1073 BrkDrvMde_D_Rq 3;
BA_ "U_S550_MY15_Gas_Rx" SG_ 1073 BrkDrvMde_D_Rq 1;
BA_ "U_V408_MY18_Diesel_Rx" SG_ 1082 SelDrvMdePt_D_Stat_UB 1;
BA_ "U_V408_MY18_Gas_Rx" SG_ 1082 SelDrvMdePt_D_Stat_UB 1;
BA_ "U_V408_MY18_Diesel_Rx" SG_ 1082 SelDrvMdePt_D_Stat 1;
BA_ "U_V408_MY18_Gas_Rx" SG_ 1082 SelDrvMdePt_D_Stat 1;
BA_ "U_U55x_MY18_Gas_Rx" SG_ 1082 SelDrvMdePt_D_Stat 1;
BA_ "GenSigSendType" SG_ 1082 SelDrvMdePt_D_Stat 3;
BA_ "GenSigSendType" SG_ 1082 SelDrvMdeTxtReset_B_Rq 3;
BA_ "U_U55x_MY18_Gas_Rx" SG_ 1082 SelDrvMdeTxtReset_B_Rq 1;
BA_ "GenSigSendType" SG_ 1082 SelDrvMdeDsply_B_Avail 3;
BA_ "U_U55x_MY18_Gas_Rx" SG_ 1082 SelDrvMdeDsply_B_Avail 1;
BA_ "U_V408_MY18_Diesel_Rx" SG_ 1082 DrvSlipCtlMde_B_RqMyKey_UB 1;
BA_ "U_V408_MY18_Gas_Rx" SG_ 1082 DrvSlipCtlMde_B_RqMyKey_UB 1;
BA_ "U_V408_MY18_Diesel_Rx" SG_ 1082 DrvSlipCtlMde_B_RqMyKey 1;
BA_ "U_V408_MY18_Gas_Rx" SG_ 1082 DrvSlipCtlMde_B_RqMyKey 1;
BA_ "U_CD4_MY17_Phev_Rx" SG_ 1082 DrvSlipCtlMde_B_RqMyKey 1;
BA_ "U_CD4_MY17_Hev_Rx" SG_ 1082 DrvSlipCtlMde_B_RqMyKey 1;
BA_ "U_CD4_MY17_Gas_Rx" SG_ 1082 DrvSlipCtlMde_B_RqMyKey 1;
BA_ "U_CD4_MY17_Diesel_Rx" SG_ 1082 DrvSlipCtlMde_B_RqMyKey 1;
BA_ "CrossOver_InfoCAN" SG_ 1082 DrvSlipCtlMde_B_RqMyKey 1;
BA_ "GenSigSendType" SG_ 1082 DrvSlipCtlMde_B_RqMyKey 3;
BA_ "U_P552_MY17_Gas_Rx" SG_ 1082 AwdDrvMde_D_Rq 1;
BA_ "GenSigSendType" SG_ 1082 AwdDrvMde_D_Rq 3;
BA_ "U_U55x_MY18_Gas_Rx" SG_ 1082 MetricActv_B_Actl_UB 1;
BA_ "GenSigSendType" SG_ 1082 MetricActv_B_Actl 3;
BA_ "CrossOver_InfoCAN" SG_ 1082 MetricActv_B_Actl 1;
BA_ "U_U55x_MY18_Gas_Rx" SG_ 1082 MetricActv_B_Actl 1;
BA_ "U_P552_MY17_Gas_Rx" SG_ 1082 NtrlTowMdeEnbl_B_RqDrv 1;
BA_ "CrossOver_InfoCAN" SG_ 1082 NtrlTowMdeEnbl_B_RqDrv 1;
BA_ "GenSigSendType" SG_ 1082 NtrlTowMdeEnbl_B_RqDrv 3;
BA_ "GenSigStartValue" SG_ 1082 RearDiffLck_D_RqArb 3;
BA_ "GenSigSendType" SG_ 1082 RearDiffLck_D_RqArb 3;
BA_ "GenSigSendType" SG_ 1054 SelDrvMdeChassis_D_Rq 3;
BA_ "U_U55x_MY18_Gas_Rx" SG_ 1054 SelDrvMdeChassis_D_Rq 1;
BA_ "U_U55x_MY18_Gas_Tx" SG_ 1054 SelDrvMdeChassis_D_Rq 1;
BA_ "U_V408_MY18_Gas_Tx" SG_ 1054 SelDrvMdeChassis_D_Rq 1;
BA_ "U_V408_MY18_Diesel_Tx" SG_ 1054 SelDrvMdeChassis_D_Rq 1;
BA_ "GenSigSendType" SG_ 1054 SelDrvMdeAwd_D_Rq 3;
BA_ "U_U55x_MY18_Gas_Rx" SG_ 1054 SelDrvMdeAwd_D_Rq 1;
BA_ "U_U55x_MY18_Gas_Tx" SG_ 1054 SelDrvMdeAwd_D_Rq 1;
BA_ "U_S550_MY18_Gas_Tx" SG_ 1054 BrkMdeInhbt_B_RqDsply 1;
BA_ "U_CD4_MY17_Phev_Tx" SG_ 1054 BrkMdeInhbt_B_RqDsply 1;
BA_ "U_CD4_MY17_Hev_Tx" SG_ 1054 BrkMdeInhbt_B_RqDsply 1;
BA_ "U_CD4_MY17_Gas_Tx" SG_ 1054 BrkMdeInhbt_B_RqDsply 1;
BA_ "U_CD4_MY17_Diesel_Tx" SG_ 1054 BrkMdeInhbt_B_RqDsply 1;
BA_ "U_S550_MY15_Gas_Tx" SG_ 1054 BrkMdeInhbt_B_RqDsply 1;
BA_ "WakeupSignal" SG_ 1054 BrkMdeInhbt_B_RqDsply 1;
BA_ "GenSigSendType" SG_ 1054 BrkMdeInhbt_B_RqDsply 3;
BA_ "U_V408_MY18_Diesel_Tx" SG_ 1054 BrkBstrVac_D_Stat 1;
BA_ "U_V408_MY18_Gas_Tx" SG_ 1054 BrkBstrVac_D_Stat 1;
BA_ "GenSigSendType" SG_ 1054 BrkBstrVac_D_Stat 3;
BA_ "GenSigSendType" SG_ 1054 DrvSlipCtlMdeMsg_D_Rq 3;
BA_ "U_S550_MY15_Gas_Tx" SG_ 1054 DrvSlipCtlMdeMsg_D_Rq 1;
BA_ "Gateway_ID" SG_ 1054 DrvSlipCtlMdeMsg_D_Rq 27613;
BA_ "GenSigSendType" SG_ 1054 DrvSlipCtlOffLamp_D_Rq 3;
BA_ "U_S550_MY15_Gas_Tx" SG_ 1054 DrvSlipCtlOffLamp_D_Rq 1;
BA_ "Gateway_ID" SG_ 1054 DrvSlipCtlOffLamp_D_Rq 27614;
BA_ "U_P552_MY17_Gas_Rx" SG_ 1114 TrlrTrgtPtrnId_No_Mem 1;
BA_ "U_P552_MY15_Gas_Rx" SG_ 1114 TrlrAidSetup_D_Rq 1;
BA_ "U_P552_MY15_Gas_Rx" SG_ 1114 TrlrAnOffstDir_D_Mem 1;
BA_ "U_P552_MY15_Gas_Rx" SG_ 1114 TrlrAnOffst_An_Mem 1;
BA_ "U_P552_MY15_Gas_Rx" SG_ 1114 TrlrTrgtOffstDir_D_Stat 1;
BA_ "U_P552_MY15_Gas_Rx" SG_ 1114 TrlrTrgtOffst_L_Actl 1;
BA_ "U_P552_MY15_Gas_Rx" SG_ 1114 TrlrTrgtToBmpr_L_Actl 1;
BA_ "U_P552_MY15_Gas_Rx" SG_ 1114 TrlrId_No_Actl 1;
BA_ "U_P552_MY15_Gas_Rx" SG_ 1114 TrlrBallToBmpr_L_Actl 1;
BA_ "U_P552_MY15_Gas_Rx" SG_ 1114 TrlrAxleToBmpr_L_Actl 1;
BA_ "U_P552_MY15_Gas_Rx" SG_ 1114 TrlrAidEnbl_D_Rq 1;
BA_ "GenSigSendType" SG_ 1047 TrlrAidMsgTxt_D_Rq 3;
BA_ "U_P552_MY15_Gas_Tx" SG_ 1047 TrlrAidMsgTxt_D_Rq 1;
BA_ "GenSigSendType" SG_ 1047 TrlrAidEnbl_D_Stat 3;
BA_ "U_P552_MY15_Gas_Tx" SG_ 1047 TrlrAidEnbl_D_Stat 1;
BA_ "GenSigSendType" SG_ 1105 TrlrRvrseMsgTxt_D_Rq 3;
BA_ "GenSigStartValue" SG_ 1105 TrlrRvrseMsgTxt_D_Rq 1;
BA_ "U_P558_MY17_Gas_Tx" SG_ 1105 TrlrRvrseMsgTxt_D_Rq 1;
BA_ "U_P558_MY17_Diesel_Tx" SG_ 1105 TrlrRvrseMsgTxt_D_Rq 1;
BA_ "U_CD43_MY17_Gas_Tx" SG_ 1105 TrlrRvrseMsgTxt_D_Rq 1;
BA_ "U_V36X_MY19_Tx" SG_ 1105 TrlrRvrseMsgTxt_D_Rq 1;
BA_ "GenSigSendType" SG_ 1105 TrlrHitchLamp_D_Rq2 3;
BA_ "U_P558_MY17_Gas_Tx" SG_ 1105 TrlrHitchLamp_D_Rq2 1;
BA_ "U_P558_MY17_Diesel_Tx" SG_ 1105 TrlrHitchLamp_D_Rq2 1;
BA_ "U_CD43_MY17_Gas_Tx" SG_ 1105 TrlrHitchLamp_D_Rq2 1;
BA_ "U_U55x_MY18_Gas_Tx" SG_ 1105 TrlrHitchLamp_D_Rq2 1;
BA_ "U_V36X_MY19_Tx" SG_ 1105 TrlrHitchLamp_D_Rq2 1;
BA_ "GenSigSendType" SG_ 1105 CamraFrntStat_D_Stat 3;
BA_ "U_P552_MY15_Gas_Tx" SG_ 1105 CamraFrntStat_D_Stat 1;
BA_ "CrossOver_InfoCAN" SG_ 939 PrkAidRear_D_Stat 1;
BA_ "CrossOver_InfoCAN" SG_ 939 PrkAidFront_D_Stat 1;
BA_ "CrossOver_InfoCAN" SG_ 939 PrkAidChime_D_Stat 1;
BA_ "CrossOver_InfoCAN" SG_ 939 PrkAid_D_Falt 1;
BA_ "U_V36X_MY19_Rx" SG_ 939 PrkAid_D_Falt 1;
BA_ "CrossOver_InfoCAN" SG_ 939 PrkAidSnsRlCntr_D_Stat 1;
BA_ "U_P552_MY15_Gas_Rx" SG_ 939 PrkAidSnsRlCntr_D_Stat 1;
BA_ "CrossOver_InfoCAN" SG_ 939 PrkAidSnsRrSide_D_Stat 1;
BA_ "U_P552_MY15_Gas_Rx" SG_ 939 PrkAidSnsRrSide_D_Stat 1;
BA_ "CrossOver_InfoCAN" SG_ 939 PrkAidSnsRrCrnr_D_Stat 1;
BA_ "U_P552_MY15_Gas_Rx" SG_ 939 PrkAidSnsRrCrnr_D_Stat 1;
BA_ "CrossOver_InfoCAN" SG_ 939 PrkAidSnsRrCntr_D_Stat 1;
BA_ "U_P552_MY15_Gas_Rx" SG_ 939 PrkAidSnsRrCntr_D_Stat 1;
BA_ "CrossOver_InfoCAN" SG_ 939 PrkAidSnsRlSide_D_Stat 1;
BA_ "U_P552_MY15_Gas_Rx" SG_ 939 PrkAidSnsRlSide_D_Stat 1;
BA_ "CrossOver_InfoCAN" SG_ 939 PrkAidSnsRlCrnr_D_Stat 1;
BA_ "U_P552_MY15_Gas_Rx" SG_ 939 PrkAidSnsRlCrnr_D_Stat 1;
VAL_ 1100 GrossTrainWeight_M_Est_UB 1 "Fresh_data" 0 "Unchanged_data" ;
VAL_ 1100 GrossTrainWeight_M_Est 255 "Faulty" 254 "NoDataExists" ;
VAL_ 370 GearPos_D_Actl 15 "Unknown" 14 "Reverse" 13 "Undefined_5" 12 "Undefined_4" 11 "Undefined_3" 10 "Tenth" 9 "Ninth" 8 "Eighth" 7 "Seventh" 6 "Sixth" 5 "Fifth" 4 "Fourth" 3 "Third" 2 "Second" 1 "First" 0 "Neutral" ;
VAL_ 1126 GpsUtcYr_No_Actl 31 "Fault" ;
VAL_ 1126 GpsUtcMnth_No_Actl 15 "Fault" ;
VAL_ 1126 GPS_UTC_seconds 63 "Fault" 62 "Unknown" ;
VAL_ 1126 GPS_UTC_minutes 63 "Fault" 62 "Unknown" ;
VAL_ 1126 GPS_UTC_hours 31 "Invalid" 30 "Unknown" ;
VAL_ 1126 GPS_Pdop 31 "Invalid" 30 "Unknown" ;
VAL_ 1126 GPS_Compass_direction 7 "NorthWest" 6 "West" 5 "SouthWest" 4 "South" 3 "SouthEast" 2 "East" 1 "NorthEast" 0 "North" ;
VAL_ 1126 GPS_Actual_vs_Infer_pos 1 "Inferred_Position" 0 "Actual_Postition" ;
VAL_ 1126 Gps_B_Falt 1 "Yes" 0 "No" ;
VAL_ 980 AdbMde1_D_Rq 3 "MarkerLightFlashing" 2 "MarkerLightConstant" 1 "Spot" 0 "None" ;
VAL_ 980 AdbIntns1_D_Rq 3 "Maximum" 2 "Medium" 1 "Low" 0 "Off" ;
VAL_ 980 AdbBrdr1Up_An_Rq 511 "Faulty" 510 "NoDataExists" ;
VAL_ 980 AdbBrdr1Right_An_Rq 2047 "Faulty" 2046 "NoDataExists" ;
VAL_ 980 AdbBrdr1Low_An_Rq 511 "Faulty" 510 "NoDataExists" ;
VAL_ 980 AdbBrdr1Left_An_Rq 2047 "Faulty" 2046 "NoDataExists" ;
VAL_ 973 TsrVl1RstrcMsgTxt2_D_Rq 7 "NotUsed" 6 "Time" 5 "Trailer" 4 "Snow" 3 "RainWet" 2 "NoRecognizableRestrictn" 1 "NoSpeedLimitRestrictn" 0 "Null" ;
VAL_ 973 TsrVl2RstrcMsgTxt2_D_Rq 7 "NotUsed" 6 "Time" 5 "Trailer" 4 "Snow" 3 "RainWet" 2 "NoRecognizableRestrictn" 1 "NoSpeedLimitRestrictn" 0 "Null" ;
VAL_ 973 TsrOvtkMsgTxt_D_Rq 7 "LimForTrucksCancelled" 6 "LimForTrucksWoQlfdRstrc" 5 "LimForTrucksWithoutRstrc" 4 "LimAllCancelled" 3 "LimAllWithoutQlfdRstrc" 2 "LimAllWithoutRestriction" 1 "OvertakingAllowed" 0 "Null" ;
VAL_ 973 WwaWarn_B_Rq 1 "On" 0 "Off" ;
VAL_ 973 TsrVl2PrmntMsgTxt_D_Rq 3 "NotUsed" 2 "ShowPermanentlyWithSupp" 1 "ShowPermanentlyWithoutSupp" 0 "DoNotShowSignPermanent" ;
VAL_ 973 TsrVl1PrmntMsgTxt_D_Rq 3 "NotUsed" 2 "ShowPermanentlyWithSupp" 1 "ShowPermanentlyWithoutSupp" 0 "DoNotShowSignPermanent" ;
VAL_ 973 TsrOvtkMsgTxt2_D_Rq 15 "NotUsed5" 14 "NotUsed4" 13 "NotUsed3" 12 "NotUsed2" 11 "NotUsed1" 10 "LimForTrucksCancelled" 9 "LimForTrucksWoQlfdRstrc" 8 "LimForTrucksWithoutRstrc" 7 "LimAllCancelled" 6 "LimAllWithRstrcTime" 5 "LimAllWithRstrcTrailer" 4 "LimAllWithRstrcSnow" 3 "LimAllWithRstrcRain" 2 "LimAllWithoutQlfdRstrc" 1 "LimAllWithoutRestriction" 0 "OvertakingAllowed" ;
VAL_ 973 TsrVlUnitMsgTxt_D_Rq 3 "NoDataExists" 2 "Mph" 1 "Kph" 0 "Null" ;
VAL_ 973 TsrVLim2MsgTxt_D_Rq 255 "NoLimit" 254 "NotUsed2" 253 "NotUsed1" 252 "NotToBeDisplayed" 251 "LimitCancelled" 31 "1F_FA_Message31_250" 30 "Message30" 29 "Message29" 28 "Message28" 27 "Message27" 26 "Message26" 25 "Message25" 24 "Message24" 23 "Message23" 22 "Message22" 21 "Message21" 20 "Message20" 19 "Message19" 18 "Message18" 17 "Message17" 16 "Message16" 15 "Message15" 14 "Message14" 13 "Message13" 12 "Message12" 11 "Message11" 10 "Message10" 9 "Message9" 8 "Message8" 7 "Message7" 6 "Message6" 5 "Message5" 4 "Message4" 3 "Message3" 2 "Message2" 1 "Message1" 0 "Null" ;
VAL_ 973 TsrVLim1MsgTxt_D_Rq 255 "NoLimit" 254 "NotUsed2" 253 "NotUsed1" 252 "NotToBeDisplayed" 251 "LimitCancelled" 31 "1F_FA_Message31_250" 30 "Message30" 29 "Message29" 28 "Message28" 27 "Message27" 26 "Message26" 25 "Message25" 24 "Message24" 23 "Message23" 22 "Message22" 21 "Message21" 20 "Message20" 19 "Message19" 18 "Message18" 17 "Message17" 16 "Message16" 15 "Message15" 14 "Message14" 13 "Message13" 12 "Message12" 11 "Message11" 10 "Message10" 9 "Message9" 8 "Message8" 7 "Message7" 6 "Message6" 5 "Message5" 4 "Message4" 3 "Message3" 2 "Message2" 1 "Message1" 0 "Null" ;
VAL_ 973 TsrVl2StatMsgTxt_D_Rq 3 "LimitOutdated" 2 "LimitReiable" 1 "LimitChanged" 0 "Null" ;
VAL_ 973 TsrVl1StatMsgTxt_D_Rq 3 "LimitOutdated" 2 "LimitReiable" 1 "LimitChanged" 0 "Null" ;
VAL_ 973 TsrStatMsgTxt_D_Rq 7 "NotUsed" 6 "NoDataExists" 5 "TSR_Error" 4 "Available_NavigationOnly" 3 "Available_CameraOnly" 2 "Available_FusionMode" 1 "TSR_Off" 0 "Null" ;
VAL_ 973 TsrOvtkStatMsgTxt_D_Rq 3 "LimitOutdated" 2 "LimitReiable" 1 "LimitChanged" 0 "Null" ;
VAL_ 973 TsrMsgTxt_D_Rq 15 "NotUsed6" 14 "NotUsed5" 13 "NotUsed4" 12 "NotUsed3" 11 "NotUsed2" 10 "NotUsed1" 9 "RecgnzdSignNotUsblForDsply" 8 "LimitedSystemPerformance" 7 "OffRoad" 6 "RegionNotSupported" 5 "CountryNotSupported" 4 "WrngNavDatIncompDatCarrier" 3 "NoNavDataAvailable" 2 "NoNavAvailableSwitchedOff" 1 "NoInformationAllOK" 0 "Null" ;
VAL_ 979 LatCtlRampType_D_Rq 3 "Immediately" 2 "Fast" 1 "Medium" 0 "Slow" ;
VAL_ 979 LatCtlPrecision_D_Rq 3 "NotUsed2" 2 "NotUsed1" 1 "Precise" 0 "Comfortable" ;
VAL_ 979 LatCtl_D_Rq 7 "NotUsed6" 6 "NotUsed5" 5 "NotUsed4" 4 "NotUsed3" 3 "InterventionRight" 2 "InterventionLeft" 1 "ContinuousPathFollowing" 0 "NoLateralControl" ;
VAL_ 979 HandsOffCnfm_B_Rq 1 "Active" 0 "Inactive" ;
VAL_ 985 AdbHiBeamKeepOff_D_Rq 3 "KeepBothOff" 2 "KeepLeftOff" 1 "KeepRightOff" 0 "BothFreeRunning" ;
VAL_ 985 AdbDividedRoad_B_Stat 1 "Yes" 0 "No" ;
VAL_ 985 AdbRampingV_D_Rq 3 "Slow" 2 "Medium" 1 "Fast" 0 "Immediately" ;
VAL_ 985 AdbLampOnOff_D_Rq 3 "BothOn" 2 "LeftOnRightOff" 1 "RightOnLeftOff" 0 "BothOff" ;
VAL_ 985 DasAlrtInfo_D_Dsply 3 "NotUsed" 2 "On" 1 "Off" 0 "Null" ;
VAL_ 985 IaccVLimUnit_D_Rq 3 "NoDataExists" 2 "Mph" 1 "Kph" 0 "Null" ;
VAL_ 985 IaccVLim_D_Rq 183 "NotUsed_3_to_72_toHexFC" 2 "LimitSpeed2_to_178_toHexB2" 255 "Faulty" 254 "NoDataExists" 253 "NotUsed_73" 182 "NotUsed_2" 181 "NotUsed_1" 180 "LimitSpeed_180_kph_mph" 179 "LimitSpeed_179_kph_mph" 1 "LimitSpeed_1_kph_mph" 0 "LimitSpeed_0_kph_mph" ;
VAL_ 985 IsaVLimUnit_D_Rq 3 "NoDataExists" 2 "Mph" 1 "Kph" 0 "Null" ;
VAL_ 985 IsaVLim_D_Rq 183 "NotUsed_3_to_72_toHexFC" 2 "LimitSpeed2_to_178_toHexB2" 255 "Faulty" 254 "NoDataExists" 253 "NotUsed_73" 182 "NotUsed_2" 181 "NotUsed_1" 180 "LimitSpeed_180_kph_mph" 179 "LimitSpeed_179_kph_mph" 1 "LimitSpeed_1_kph_mph" 0 "LimitSpeed_0_kph_mph" ;
VAL_ 983 EsaEnbl_D2_Rq 3 "NotConfigured" 2 "Enabled" 1 "Pending" 0 "Disabled" ;
VAL_ 983 CmbbObjRelLong_V_Actl 1023 "Faulty" 1022 "NoDataExists" ;
VAL_ 983 CmbbObjRelLat_V_Actl 511 "Faulty" 510 "NoDataExists" ;
VAL_ 983 CmbbObjDistLong_L_Actl 1023 "Faulty" 1022 "NoDataExists" ;
VAL_ 983 CmbbObjDistLat_L_Actl 511 "Faulty" 510 "NoDataExists" ;
VAL_ 983 CmbbObjConfdnc_D_Stat 3 "High" 2 "Medium" 1 "Low" 0 "NotDetermined" ;
VAL_ 983 CmbbObjColl_T_Actl 127 "Faulty" 126 "NoDataExists" ;
VAL_ 983 CmbbObjClass_D_Stat 15 "NotUsed_9" 14 "NotUsed_8" 13 "NotUsed_7" 12 "NotUsed_6" 11 "NotUsed_5" 10 "NotUsed_4" 9 "NotUsed_3" 8 "NotUsed_2" 7 "NotUsed_1" 6 "Unclassified_Vehicle" 5 "Bicycle" 4 "Pedestrian" 3 "Truck" 2 "Motorcycle" 1 "Vehicle" 0 "Undetermined" ;
VAL_ 962 AdbMde3_D_Rq 3 "MarkerLightFlashing" 2 "MarkerLightConstant" 1 "Spot" 0 "None" ;
VAL_ 962 AdbIntns3_D_Rq 3 "Maximum" 2 "Medium" 1 "Low" 0 "Off" ;
VAL_ 962 AdbBrdr3Up_An_Rq 511 "Faulty" 510 "NoDataExists" ;
VAL_ 962 AdbBrdr3Right_An_Rq 2047 "Faulty" 2046 "NoDataExists" ;
VAL_ 962 AdbBrdr3Low_An_Rq 511 "Faulty" 510 "NoDataExists" ;
VAL_ 962 AdbBrdr3Left_An_Rq 2047 "Faulty" 2046 "NoDataExists" ;
VAL_ 961 AdbMde2_D_Rq 3 "MarkerLightFlashing" 2 "MarkerLightConstant" 1 "Spot" 0 "None" ;
VAL_ 961 AdbIntns2_D_Rq 3 "Maximum" 2 "Medium" 1 "Low" 0 "Off" ;
VAL_ 961 AdbBrdr2Up_An_Rq 511 "Faulty" 510 "NoDataExists" ;
VAL_ 961 AdbBrdr2Right_An_Rq 2047 "Faulty" 2046 "NoDataExists" ;
VAL_ 961 AdbBrdr2Low_An_Rq 511 "Faulty" 510 "NoDataExists" ;
VAL_ 961 AdbBrdr2Left_An_Rq 2047 "Faulty" 2046 "NoDataExists" ;
VAL_ 1122 GpsHsphLongEast_D_Actl 0 "Invalid" 1 "Eastern" 2 "Western" 3 "Fault" ;
VAL_ 1122 GpsHsphLattSth_D_Actl 3 "Fault" 2 "Northern" 1 "Southern" 0 "Invalid" ;
VAL_ 1122 GPS_Longitude_Minutes 63 "Fault" 62 "Unknown" ;
VAL_ 1122 GPS_Longitude_Min_dec 16383 "Invalid" 16382 "Unknown" ;
VAL_ 1122 GPS_Longitude_Degrees 511 "Fault" 510 "Unknown" ;
VAL_ 1122 GPS_Latitude_Minutes 63 "Fault" 62 "Unknown" ;
VAL_ 1122 GPS_Latitude_Min_dec 16383 "Invalid" 16382 "Unknown" ;
VAL_ 1122 GPS_Latitude_Degrees 255 "Invalid" 254 "Unknown" ;
VAL_ 976 SrpSigValid_B_Stat 1 "True" 0 "False" ;
VAL_ 976 SrpHghtRight_L_Actl 511 "Faulty" ;
VAL_ 976 SrpHghtLeft_L_Actl 511 "Faulty" ;
VAL_ 976 SrpDistRight_L_Actl 511 "Faulty" ;
VAL_ 976 SrpDistLeft_L_Actl 511 "Faulty" ;
VAL_ 1080 AutoTowActv_B_Stat_UB 1 "Fresh_data" 0 "Unchanged_data" ;
VAL_ 1080 AutoTowActv_B_Stat 1 "Yes" 0 "No" ;
VAL_ 1080 HeadLghtHiPrmsn_D_Stat_UB 1 "Fresh_data" 0 "Unchanged_data" ;
VAL_ 1080 HeadLghtHiPrmsn_D_Stat 3 "CancelAndSuppress" 2 "Cancel" 1 "Hold" 0 "AllowChange" ;
VAL_ 945 KeyOffMde_D_Actl 15 "NotUsed_11" 14 "NotUsed_10" 13 "NotUsed_9" 12 "NotUsed_8" 11 "NotUsed_7" 10 "NotUsed_6" 9 "NotUsed_5" 8 "NotUsed_4" 7 "NotUsed_3" 6 "NotUsed_2" 5 "NotUsed_1" 4 "CriticalBattery" 3 "Hibernate" 2 "TransportPower" 1 "FactoryPower" 0 "NormalPower" ;
VAL_ 1053 VehStab_D_Stat 15 "Faulty" 14 "No_Data_Exists" 13 "NotUsed6" 12 "NotUsed5" 11 "NotUsed4" 10 "NotUsed3" 9 "NotUsed2" 8 "NotUsed1" 7 "High_SSRA_no_OS" 6 "Straight" 5 "Post_Oversteer" 4 "Post_Transition" 3 "Countersteer" 2 "Understeer" 1 "Oversteer" 0 "Linear" ;
VAL_ 1102 SelDrvMdePos12_D_Stat 31 "Faulty" 30 "SelDrvMde_31" 1 "SelDrvMde02_30" 0 "SelDrvMde01" ;
VAL_ 1102 SelDrvMdePos11_D_Stat 31 "Faulty" 30 "SelDrvMde_31" 1 "SelDrvMde02_30" 0 "SelDrvMde01" ;
VAL_ 1102 SelDrvMdePos10_D_Stat 31 "Faulty" 30 "SelDrvMde_31" 1 "SelDrvMde02_30" 0 "SelDrvMde01" ;
VAL_ 1102 SelDrvMdePos09_D_Stat 31 "Faulty" 30 "SelDrvMde_31" 1 "SelDrvMde02_30" 0 "SelDrvMde01" ;
VAL_ 1102 SelDrvMdePos08_D_Stat 31 "Faulty" 30 "SelDrvMde_31" 1 "SelDrvMde02_30" 0 "SelDrvMde01" ;
VAL_ 1102 SelDrvMdePos07_D_Stat 31 "Faulty" 30 "SelDrvMde_31" 1 "SelDrvMde02_30" 0 "SelDrvMde01" ;
VAL_ 1102 SelDrvMdePos06_D_Stat 31 "Faulty" 30 "SelDrvMde_31" 1 "SelDrvMde02_30" 0 "SelDrvMde01" ;
VAL_ 1102 SelDrvMdePos05_D_Stat 31 "Faulty" 30 "SelDrvMde_31" 1 "SelDrvMde02_30" 0 "SelDrvMde01" ;
VAL_ 1102 SelDrvMdePos04_D_Stat 31 "Faulty" 30 "SelDrvMde_31" 1 "SelDrvMde02_30" 0 "SelDrvMde01" ;
VAL_ 1102 SelDrvMdePos03_D_Stat 31 "Faulty" 30 "SelDrvMde_31" 1 "SelDrvMde02_30" 0 "SelDrvMde01" ;
VAL_ 1102 SelDrvMdePos02_D_Stat 31 "Faulty" 30 "SelDrvMde_31" 1 "SelDrvMde02_30" 0 "SelDrvMde01" ;
VAL_ 1102 SelDrvMdePos01_D_Stat 31 "Faulty" 30 "SelDrvMde_31" 1 "SelDrvMde02_30" 0 "SelDrvMde01" ;
VAL_ 1056 SelDrvMde_D_Stat 3 "NotUsed" 2 "DriveModeChangeRequest" 1 "DriveModeChangeSelection" 0 "NoDriveModeChangeRequest" ;
VAL_ 1056 ActvDrvMde_D2_Stat 31 "Faulty" 30 "SelDrvMde31" 29 "SelDrvMde30" 28 "SelDrvMde29" 27 "SelDrvMde28" 26 "SelDrvMde27" 25 "SelDrvMde26" 24 "SelDrvMde25" 23 "SelDrvMde24" 22 "SelDrvMde23" 21 "SelDrvMde22" 20 "SelDrvMde21" 19 "SelDrvMde20" 18 "SelDrvMde19" 17 "SelDrvMde18" 16 "SelDrvMde17" 15 "SelDrvMde16" 14 "SelDrvMde15" 13 "SelDrvMde14" 12 "SelDrvMde13" 11 "SelDrvMde12" 10 "SelDrvMde11" 9 "SelDrvMde10" 8 "SelDrvMde09" 7 "SelDrvMde08" 6 "SelDrvMde07" 5 "SelDrvMde06" 4 "SelDrvMde05" 3 "SelDrvMde04" 2 "SelDrvMde03" 1 "SelDrvMde02" 0 "SelDrvMde01" ;
VAL_ 1056 SelDrvMde_D2_Rq 31 "NotUsed" 30 "SelDrvMde31" 29 "SelDrvMde30" 28 "SelDrvMde29" 27 "SelDrvMde28" 26 "SelDrvMde27" 25 "SelDrvMde26" 24 "SelDrvMde25" 23 "SelDrvMde24" 22 "SelDrvMde23" 21 "SelDrvMde22" 20 "SelDrvMde21" 19 "SelDrvMde20" 18 "SelDrvMde19" 17 "SelDrvMde18" 16 "SelDrvMde17" 15 "SelDrvMde16" 14 "SelDrvMde15" 13 "SelDrvMde14" 12 "SelDrvMde13" 11 "SelDrvMde12" 10 "SelDrvMde11" 9 "SelDrvMde10" 8 "SelDrvMde09" 7 "SelDrvMde08" 6 "SelDrvMde07" 5 "SelDrvMde06" 4 "SelDrvMde05" 3 "SelDrvMde04" 2 "SelDrvMde03" 1 "SelDrvMde02" 0 "SelDrvMde01" ;
VAL_ 1056 SelDrvMdePos12_B_Avail 1 "Available" 0 "NotAvailable" ;
VAL_ 1056 SelDrvMdePos11_B_Avail 1 "Available" 0 "NotAvailable" ;
VAL_ 1056 SelDrvMdePos10_B_Avail 1 "Available" 0 "NotAvailable" ;
VAL_ 1056 SelDrvMdePos09_B_Avail 1 "Available" 0 "NotAvailable" ;
VAL_ 1056 SelDrvMdePos08_B_Avail 1 "Available" 0 "NotAvailable" ;
VAL_ 1056 SelDrvMdePos07_B_Avail 1 "Available" 0 "NotAvailable" ;
VAL_ 1056 SelDrvMdePos06_B_Avail 1 "Available" 0 "NotAvailable" ;
VAL_ 1056 SelDrvMdePos05_B_Avail 1 "Available" 0 "NotAvailable" ;
VAL_ 1056 SelDrvMdePos04_B_Avail 1 "Available" 0 "NotAvailable" ;
VAL_ 1056 SelDrvMdePos03_B_Avail 1 "Available" 0 "NotAvailable" ;
VAL_ 1056 SelDrvMdePos02_B_Avail 1 "Available" 0 "NotAvailable" ;
VAL_ 1056 SelDrvMdePos01_B_Avail 1 "Available" 0 "NotAvailable" ;
VAL_ 1056 SelDrvMdePt_D_Rq 31 "NotUsed16" 30 "NotUsed15" 29 "NotUsed14" 28 "NotUsed13" 27 "NotUsed12" 26 "NotUsed11" 25 "NotUsed10" 24 "NotUsed9" 23 "NotUsed8" 22 "NotUsed7" 21 "NotUsed6" 20 "NotUsed5" 19 "NotUsed4" 18 "NotUsed3" 17 "NotUsed2" 16 "NotUsed1" 15 "HighSpeedDesertMode_Baja" 14 "SportAdaptiveMode" 13 "NotAvailable_13" 12 "NotAvailable_12" 11 "NotAvailable_11" 10 "NotAvailable_10" 9 "RockCrawlMode" 8 "MudRutsMode" 7 "SandMode" 6 "EconomyMode" 5 "GrassGravelSnow" 4 "NotAvailable_04" 3 "TowHaulMode" 2 "NotAvailable_02" 1 "SportMode" 0 "NormalMode" ;
VAL_ 1056 SelDrvMdeMsgTxt_D_Rq 15 "Message15" 14 "Message14" 13 "Message13" 12 "Message12" 11 "Message11" 10 "Message10" 9 "Message9" 8 "Message8" 7 "Message7" 6 "Message6" 5 "Message5" 4 "Message4" 3 "Message3" 2 "Message2" 1 "Message1" 0 "NoMessage" ;
VAL_ 1056 AwdMde_D_RqBrk 7 "Faulty" 6 "NotUsed2" 5 "NoRequest" 4 "Neutral" 3 "FourByFourLow" 2 "FourByFourHigh" 1 "FourByFourAuto" 0 "FourByTwo" ;
VAL_ 1120 RearDiffLck_D_RqDrv 3 "Faulty" 2 "NoRequest" 1 "On" 0 "Off" ;
VAL_ 1120 AwdMde_D_RqDrv 7 "Faulty" 6 "NotUsed2" 5 "NoRequest" 4 "Neutral" 3 "FourByFourLow" 2 "FourByFourHigh" 1 "FourByFourAuto" 0 "FourByTwo" ;
VAL_ 1110 RstrnMdulePw_D_Falt 3 "NotUsed_1" 2 "NoFault" 1 "Fault" 0 "Null" ;
VAL_ 1073 HMI_HMIMode_St_UB 1 "Fresh_data" 0 "Unchanged_data" ;
VAL_ 1073 HMI_HMIMode_St 7 "NotUsed2" 6 "NotUsed1" 5 "Load_Shed_Active" 0 "Invalid" 1 "OffMode" 2 "On" 3 "Phone" 4 "Climate" ;
VAL_ 1073 SteEffort_D_Rq_UB 1 "Fresh_data" 0 "Unchanged_data" ;
VAL_ 1073 SteEffort_D_Rq 7 "NotUsed5" 6 "NotUsed4" 5 "NotUsed3" 4 "NotUsed2" 3 "NotUsed1" 2 "Comfort" 1 "Sport" 0 "Normal" ;
VAL_ 1073 DISPLAY_SPEED_SCALING_UB 1 "Fresh_data" 0 "Unchanged_data" ;
VAL_ 1073 DISPLAY_SPEED_OFFSET_UB 1 "Fresh_data" 0 "Unchanged_data" ;
VAL_ 1073 BrkDrvMde_D_Rq_UB 1 "Fresh_data" 0 "Unchanged_data" ;
VAL_ 1073 BrkDrvMde_D_Rq 7 "Faulty" 6 "RockCrawl" 5 "Baja" 4 "DragOrMudAndSand" 3 "Track" 2 "Snow_Wet" 1 "Sport" 0 "Normal" ;
VAL_ 1082 SelDrvMdePt_D_Stat_UB 1 "Fresh_data" 0 "Unchanged_data" ;
VAL_ 1082 SelDrvMdePt_D_Stat 3 "Faulty" 2 "TemporarilyNotAvailable" 1 "Available" 0 "NotAvailable" ;
VAL_ 1082 SelDrvMdeTxtReset_B_Rq_UB 1 "Fresh_data" 0 "Unchanged_data" ;
VAL_ 1082 SelDrvMdeTxtReset_B_Rq 1 "Yes" 0 "No" ;
VAL_ 1082 SelDrvMdeDsply_B_Avail_UB 1 "Fresh_data" 0 "Unchanged_data" ;
VAL_ 1082 SelDrvMdeDsply_B_Avail 1 "Available" 0 "NotAvailable" ;
VAL_ 1082 DrvSlipCtlMde_B_RqMyKey_UB 1 "Fresh_data" 0 "Unchanged_data" ;
VAL_ 1082 DrvSlipCtlMde_B_RqMyKey 1 "On" 0 "Off" ;
VAL_ 1082 AwdDrvMde_D_Rq_UB 1 "Fresh_data" 0 "Unchanged_data" ;
VAL_ 1082 AwdDrvMde_D_Rq 7 "Faulty" 6 "NotAvailable" 5 "RockCrawl" 4 "Baja" 3 "MudAndSand" 2 "Weather" 1 "Sport" 0 "Normal" ;
VAL_ 1082 MetricActv_B_Actl_UB 1 "Fresh_data" 0 "Unchanged_data" ;
VAL_ 1082 MetricActv_B_Actl 1 "Active" 0 "Inactive" ;
VAL_ 1082 NtrlTowMdeEnbl_B_RqDrv_UB 1 "Fresh_data" 0 "Unchanged_data" ;
VAL_ 1082 NtrlTowMdeEnbl_B_RqDrv 1 "Yes" 0 "No" ;
VAL_ 1082 RearDiffLck_D_RqArb_UB 1 "Fresh_data" 0 "Unchanged_data" ;
VAL_ 1082 RearDiffLck_D_RqArb 3 "Faulty" 2 "NotUsed" 1 "On" 0 "Off" ;
VAL_ 1059 TrlrTrgtAcquire_D_Rq_UB 1 "Fresh_data" 0 "Unchanged_data" ;
VAL_ 1059 TrlrTrgtAcquire_D_Rq 7 "NotUsed_2" 6 "NotUsed_1" 5 "ActivateRVCforTBA" 4 "CancelAcquisition" 3 "RetryAcquisition" 2 "AcquisitionSuccessful" 1 "StartAcquisition" 0 "Inactive" ;
VAL_ 1054 SelDrvMdeChassis_D_Rq 31 "Faulty" 30 "NotUsed17" 29 "NotUsed16" 28 "NotUsed15" 27 "NotUsed14" 26 "NotUsed13" 25 "NotUsed12" 24 "NotUsed11" 23 "NotUsed10" 22 "NotUsed9" 21 "NotUsed8" 20 "NotUsed7" 19 "NotUsed6" 18 "NotUsed5" 17 "NotUsed4" 16 "NotUsed3" 15 "NotUsed2" 14 "NotUsed1" 13 "TrackMode" 12 "HighSpeedDesertMode" 11 "TowHaulMode" 10 "RockCrawlMode" 9 "SandMode" 8 "MudAndRutsMode" 7 "LowMuMode" 6 "ComfortAdaptiveMode" 5 "ComfortMode" 4 "SportAdaptiveMode" 3 "SportMode" 2 "EconomyMode" 1 "NormalAdaptiveMode" 0 "NormalMode" ;
VAL_ 1054 SelDrvMdeAwd_D_Rq 31 "Faulty" 30 "NotUsed_17" 29 "NotUsed_16" 28 "NotUsed_15" 27 "NotUsed_14" 26 "NotUsed_13" 25 "NotUsed_12" 24 "NotUsed_11" 23 "NotUsed_10" 22 "NotUsed_9" 21 "NotUsed_8" 20 "NotUsed_7" 19 "NotUsed_6" 18 "NotUsed_5" 17 "NotUsed_4" 16 "NotUsed_3" 15 "NotUsed_2" 14 "NotUsed_1" 13 "NotAvailable" 12 "HighSpeedDesertMode_Baja" 11 "SportAdaptiveMode" 10 "RockCrawlMode" 9 "MudRutsMode" 8 "SandMode" 7 "EconomyMode" 6 "GrassGravelSnow" 5 "TowHaulMode" 4 "SportMode" 3 "Normal_4L" 2 "Normal_4A" 1 "Normal_2H" 0 "NormalMode" ;
VAL_ 1054 BrkMdeInhbt_B_RqDsply 1 "Yes" 0 "No" ;
VAL_ 1054 BrkBstrVac_D_Stat 3 "NotUsed" 2 "BoosterVacEstimator" 1 "BoosterVacSensor" 0 "NoBoosterVacuumMonitor" ;
VAL_ 1054 DrvSlipCtlMdeMsg_D_Rq 31 "Message31" 30 "Message30" 29 "Message29" 28 "Message28" 27 "Message27" 26 "Message26" 25 "Message25" 24 "Message24" 23 "Message23" 22 "Message22" 21 "Message21" 20 "Message20" 19 "Message19" 18 "Message18" 17 "Message17" 16 "Message16" 15 "Message15" 14 "Message14" 13 "Message13" 12 "Message12" 11 "Message11" 10 "Message10" 9 "Message9" 8 "Message8" 7 "Message7" 6 "Message6" 5 "Message5" 4 "Message4" 3 "Message3" 2 "Message2" 1 "Message1" 0 "NoMessage" ;
VAL_ 1054 DrvSlipCtlOffLamp_D_Rq 3 "Fast_Flash" 2 "Slow_Flash" 1 "On" 0 "Off" ;
VAL_ 1114 TrlrAidSetup_D_Rq 3 "NotUsed" 2 "EndSetup" 1 "BeginSetup" 0 "Inactive" ;
VAL_ 1114 TrlBrkInitOut_D_Rq 3 "Heavy" 2 "Medium" 1 "Light" 0 "Null" ;
VAL_ 1114 TrlrAnOffstDir_D_Mem 3 "NotUSed" 2 "Right" 1 "Left_or_Center" 0 "Null" ;
VAL_ 1114 TrlrTrgtOffstDir_D_Stat 3 "NotUSed" 2 "Right" 1 "Left_or_Center" 0 "Null" ;
VAL_ 1114 TrlrAidEnbl_D_Rq 3 "NotAvailable" 2 "DeactivateTba" 1 "ActivateTba" 0 "Inactive" ;
VAL_ 1047 TrlrAidMsgTxt_D_Rq 31 "Message31" 30 "Message30" 29 "Message29" 28 "Message28" 27 "Message27" 26 "Message26" 25 "Message25" 24 "Message24" 23 "Message23" 22 "Message22" 21 "Message21" 20 "Message20" 19 "Message19" 18 "Message18" 17 "Message17" 16 "Message16" 15 "Message15" 14 "Message14" 13 "Message13" 12 "Message12" 11 "Message11" 10 "Message10" 9 "Message9" 8 "Message8" 7 "Message7" 6 "Message6" 5 "Message5" 4 "Message4" 3 "Message3" 2 "Message2" 1 "Message1" 0 "NoMessage" ;
VAL_ 1047 TrlrAidEnbl_D_Stat 7 "Faulty" 6 "NoDataExists" 5 "TbaRecalibrate" 4 "TbaTadMonitor" 3 "TbaNotAvailable" 2 "TbaStandby" 1 "TbaActive" 0 "Null" ;
VAL_ 1105 TrlrRvrseMsgTxt_D_Rq 31 "Message31" 30 "Message30" 29 "Message29" 28 "Message28" 27 "Message27" 26 "Message26" 25 "Message25" 24 "Message24" 23 "Message23" 22 "Message22" 21 "Message21" 20 "Message20" 19 "Message19" 18 "Message18" 17 "Message17" 16 "Message16" 15 "Message15" 14 "Message14" 13 "Message13" 12 "Message12" 11 "Message11" 10 "Message10" 9 "Message9" 8 "Message8" 7 "Message7" 6 "Message6" 5 "Message5" 4 "Message4" 3 "Message3" 2 "Message2" 1 "Message1" 0 "NoMessage" ;
VAL_ 1105 TrlrHitchLamp_D_Rq2 1 "On" 0 "Off" ;
VAL_ 1105 CamraFrntStat_D_Stat 3 "No_Data_Present" 2 "NotUsed" 1 "On" 0 "Off" ;
VAL_ 939 PrkAidRear_D_Stat 3 "Faulted" 2 "Unused" 1 "Enabled" 0 "Disabled" ;
VAL_ 939 PrkAidFront_D_Stat 3 "Faulted" 2 "Unused" 1 "Enabled" 0 "Disabled" ;
VAL_ 939 PrkAidChime_D_Stat 3 "Fault" 2 "No_Data_Exists" 1 "On" 0 "Off" ;
VAL_ 939 PrkAid_D_Falt 7 "NotUsed2" 6 "NotUsed1" 5 "Failure_Front_PSM_Sensors" 4 "No_Data_Exists" 3 "Failure_Rear_Sensors" 2 "Speaker_Fault" 1 "ECU_Fault" 0 "No_Fault" ;
VAL_ 939 PrkAidSnsRlCntr_D_Stat 15 "Zone_15" 14 "Zone_14" 13 "Zone_13" 12 "Zone_12" 11 "Zone_11" 10 "Zone_10" 9 "Zone_9" 8 "Zone_8" 7 "Zone_7" 6 "Zone_6" 5 "Zone_5" 4 "Zone_4" 3 "Zone_3" 2 "Zone_2" 1 "Zone_1" 0 "Off" ;
VAL_ 939 PrkAidSnsRrSide_D_Stat 15 "Zone_15" 14 "Zone_14" 13 "Zone_13" 12 "Zone_12" 11 "Zone_11" 10 "Zone_10" 9 "Zone_9" 8 "Zone_8" 7 "Zone_7" 6 "Zone_6" 5 "Zone_5" 4 "Zone_4" 3 "Zone_3" 2 "Zone_2" 1 "Zone_1" 0 "Off" ;
VAL_ 939 PrkAidSnsRrCrnr_D_Stat 15 "Zone_15" 14 "Zone_14" 13 "Zone_13" 12 "Zone_12" 11 "Zone_11" 10 "Zone_10" 9 "Zone_9" 8 "Zone_8" 7 "Zone_7" 6 "Zone_6" 5 "Zone_5" 4 "Zone_4" 3 "Zone_3" 2 "Zone_2" 1 "Zone_1" 0 "Off" ;
VAL_ 939 PrkAidSnsRrCntr_D_Stat 15 "Zone_15" 14 "Zone_14" 13 "Zone_13" 12 "Zone_12" 11 "Zone_11" 10 "Zone_10" 9 "Zone_9" 8 "Zone_8" 7 "Zone_7" 6 "Zone_6" 5 "Zone_5" 4 "Zone_4" 3 "Zone_3" 2 "Zone_2" 1 "Zone_1" 0 "Off" ;
VAL_ 939 PrkAidSnsRlSide_D_Stat 15 "Zone_15" 14 "Zone_14" 13 "Zone_13" 12 "Zone_12" 11 "Zone_11" 10 "Zone_10" 9 "Zone_9" 8 "Zone_8" 7 "Zone_7" 6 "Zone_6" 5 "Zone_5" 4 "Zone_4" 3 "Zone_3" 2 "Zone_2" 1 "Zone_1" 0 "Off" ;
VAL_ 939 PrkAidSnsRlCrnr_D_Stat 15 "Zone_15" 14 "Zone_14" 13 "Zone_13" 12 "Zone_12" 11 "Zone_11" 10 "Zone_10" 9 "Zone_9" 8 "Zone_8" 7 "Zone_7" 6 "Zone_6" 5 "Zone_5" 4 "Zone_4" 3 "Zone_3" 2 "Zone_2" 1 "Zone_1" 0 "Off" ;
